VERSION ""

NS_ :

BS_:

BU_: ICC DVR PCL EAMP FLZCU_HCU_IC FLZCU_IC HCU_IC FLZCU_Signal_IC CGW TBOX BNCM CWC FRZCU

BO_ 771 FLZCU_303h: 16 FLZCU_Signal_IC
 SG_ TimeGapAdjustment_33Dh : 26|3@0+ (1,0) [0|7] ""  ICC

BO_ 1127 CDU_DCDC_1: 24 Vector__XXX
 SG_ DCDC_FaultLevelSts : 107|3@0+ (1,0) [0|7] ""  ICC

BO_ 1035 VCC_1: 8 FLZCU_Signal_IC
 SG_ VCC_1_OTASts : 17|2@0- (1,0) [0|3] ""  ICC

BO_ 1364 ICC_RISD_44: 64 ICC
 SG_ ICC_RISD_Pixel504_OnOff : 511|1@0+ (1,0) [0|1] "" Vector__XXX
 SG_ ICC_RISD_Pixel503_OnOff : 510|1@0+ (1,0) [0|1] "" Vector__XXX
 SG_ ICC_RISD_Pixel502_OnOff : 509|1@0+ (1,0) [0|1] "" Vector__XXX
 SG_ ICC_RISD_Pixel501_OnOff : 508|1@0+ (1,0) [0|1] "" Vector__XXX
 SG_ ICC_RISD_Pixel500_OnOff : 507|1@0+ (1,0) [0|1] "" Vector__XXX
 SG_ ICC_RISD_Pixel499_OnOff : 506|1@0+ (1,0) [0|1] "" Vector__XXX
 SG_ ICC_RISD_Pixel498_OnOff : 505|1@0+ (1,0) [0|1] "" Vector__XXX
 SG_ ICC_RISD_Pixel497_OnOff : 504|1@0+ (1,0) [0|1] "" Vector__XXX
 SG_ ICC_RISD_Pixel496_OnOff : 503|1@0+ (1,0) [0|1] "" Vector__XXX
 SG_ ICC_RISD_Pixel495_OnOff : 502|1@0+ (1,0) [0|1] "" Vector__XXX
 SG_ ICC_RISD_Pixel494_OnOff : 501|1@0+ (1,0) [0|1] "" Vector__XXX
 SG_ ICC_RISD_Pixel493_OnOff : 500|1@0+ (1,0) [0|1] "" Vector__XXX
 SG_ ICC_RISD_Pixel492_OnOff : 499|1@0+ (1,0) [0|1] "" Vector__XXX
 SG_ ICC_RISD_Pixel491_OnOff : 498|1@0+ (1,0) [0|1] "" Vector__XXX
 SG_ ICC_RISD_Pixel490_OnOff : 497|1@0+ (1,0) [0|1] "" Vector__XXX
 SG_ ICC_RISD_Pixel489_OnOff : 496|1@0+ (1,0) [0|1] "" Vector__XXX
 SG_ ICC_RISD_Pixel488_OnOff : 495|1@0+ (1,0) [0|1] "" Vector__XXX
 SG_ ICC_RISD_Pixel487_OnOff : 494|1@0+ (1,0) [0|1] "" Vector__XXX
 SG_ ICC_RISD_Pixel486_OnOff : 493|1@0+ (1,0) [0|1] "" Vector__XXX
 SG_ ICC_RISD_Pixel485_OnOff : 492|1@0+ (1,0) [0|1] "" Vector__XXX
 SG_ ICC_RISD_Pixel484_OnOff : 491|1@0+ (1,0) [0|1] "" Vector__XXX
 SG_ ICC_RISD_Pixel483_OnOff : 490|1@0+ (1,0) [0|1] "" Vector__XXX
 SG_ ICC_RISD_Pixel482_OnOff : 489|1@0+ (1,0) [0|1] "" Vector__XXX
 SG_ ICC_RISD_Pixel481_OnOff : 488|1@0+ (1,0) [0|1] "" Vector__XXX
 SG_ ICC_RISD_Pixel480_OnOff : 487|1@0+ (1,0) [0|1] "" Vector__XXX
 SG_ ICC_RISD_Pixel479_OnOff : 486|1@0+ (1,0) [0|1] "" Vector__XXX
 SG_ ICC_RISD_Pixel478_OnOff : 485|1@0+ (1,0) [0|1] "" Vector__XXX
 SG_ ICC_RISD_Pixel477_OnOff : 484|1@0+ (1,0) [0|1] "" Vector__XXX
 SG_ ICC_RISD_Pixel476_OnOff : 483|1@0+ (1,0) [0|1] "" Vector__XXX
 SG_ ICC_RISD_Pixel475_OnOff : 482|1@0+ (1,0) [0|1] "" Vector__XXX
 SG_ ICC_RISD_Pixel474_OnOff : 481|1@0+ (1,0) [0|1] "" Vector__XXX
 SG_ ICC_RISD_Pixel473_OnOff : 480|1@0+ (1,0) [0|1] "" Vector__XXX
 SG_ ICC_RISD_Pixel472_OnOff : 479|1@0+ (1,0) [0|1] "" Vector__XXX
 SG_ ICC_RISD_Pixel471_OnOff : 478|1@0+ (1,0) [0|1] "" Vector__XXX
 SG_ ICC_RISD_Pixel470_OnOff : 477|1@0+ (1,0) [0|1] "" Vector__XXX
 SG_ ICC_RISD_Pixel469_OnOff : 476|1@0+ (1,0) [0|1] "" Vector__XXX
 SG_ ICC_RISD_Pixel468_OnOff : 475|1@0+ (1,0) [0|1] "" Vector__XXX
 SG_ ICC_RISD_Pixel467_OnOff : 474|1@0+ (1,0) [0|1] "" Vector__XXX
 SG_ ICC_RISD_Pixel466_OnOff : 473|1@0+ (1,0) [0|1] "" Vector__XXX
 SG_ ICC_RISD_Pixel465_OnOff : 472|1@0+ (1,0) [0|1] "" Vector__XXX
 SG_ ICC_RISD_Pixel464_OnOff : 471|1@0+ (1,0) [0|1] "" Vector__XXX
 SG_ ICC_RISD_Pixel463_OnOff : 470|1@0+ (1,0) [0|1] "" Vector__XXX
 SG_ ICC_RISD_Pixel462_OnOff : 469|1@0+ (1,0) [0|1] "" Vector__XXX
 SG_ ICC_RISD_Pixel461_OnOff : 468|1@0+ (1,0) [0|1] "" Vector__XXX
 SG_ ICC_RISD_Pixel460_OnOff : 467|1@0+ (1,0) [0|1] "" Vector__XXX
 SG_ ICC_RISD_Pixel459_OnOff : 466|1@0+ (1,0) [0|1] "" Vector__XXX
 SG_ ICC_RISD_Pixel458_OnOff : 465|1@0+ (1,0) [0|1] "" Vector__XXX
 SG_ ICC_RISD_Pixel457_OnOff : 464|1@0+ (1,0) [0|1] "" Vector__XXX
 SG_ ICC_RISD_Pixel456_OnOff : 463|1@0+ (1,0) [0|1] "" Vector__XXX
 SG_ ICC_RISD_Pixel455_OnOff : 462|1@0+ (1,0) [0|1] "" Vector__XXX
 SG_ ICC_RISD_Pixel454_OnOff : 461|1@0+ (1,0) [0|1] "" Vector__XXX
 SG_ ICC_RISD_Pixel453_OnOff : 460|1@0+ (1,0) [0|1] "" Vector__XXX
 SG_ ICC_RISD_Pixel452_OnOff : 459|1@0+ (1,0) [0|1] "" Vector__XXX
 SG_ ICC_RISD_Pixel451_OnOff : 458|1@0+ (1,0) [0|1] "" Vector__XXX
 SG_ ICC_RISD_Pixel450_OnOff : 457|1@0+ (1,0) [0|1] "" Vector__XXX
 SG_ ICC_RISD_Pixel449_OnOff : 456|1@0+ (1,0) [0|1] "" Vector__XXX
 SG_ ICC_RISD_Pixel448_OnOff : 455|1@0+ (1,0) [0|1] "" Vector__XXX
 SG_ ICC_RISD_Pixel447_OnOff : 454|1@0+ (1,0) [0|1] "" Vector__XXX
 SG_ ICC_RISD_Pixel446_OnOff : 453|1@0+ (1,0) [0|1] "" Vector__XXX
 SG_ ICC_RISD_Pixel445_OnOff : 452|1@0+ (1,0) [0|1] "" Vector__XXX
 SG_ ICC_RISD_Pixel444_OnOff : 451|1@0+ (1,0) [0|1] "" Vector__XXX
 SG_ ICC_RISD_Pixel443_OnOff : 450|1@0+ (1,0) [0|1] "" Vector__XXX
 SG_ ICC_RISD_Pixel442_OnOff : 449|1@0+ (1,0) [0|1] "" Vector__XXX
 SG_ ICC_RISD_Pixel441_OnOff : 448|1@0+ (1,0) [0|1] "" Vector__XXX
 SG_ ICC_RISD_Pixel440_OnOff : 447|1@0+ (1,0) [0|1] "" Vector__XXX
 SG_ ICC_RISD_Pixel439_OnOff : 446|1@0+ (1,0) [0|1] "" Vector__XXX
 SG_ ICC_RISD_Pixel438_OnOff : 445|1@0+ (1,0) [0|1] "" Vector__XXX
 SG_ ICC_RISD_Pixel437_OnOff : 444|1@0+ (1,0) [0|1] "" Vector__XXX
 SG_ ICC_RISD_Pixel436_OnOff : 443|1@0+ (1,0) [0|1] "" Vector__XXX
 SG_ ICC_RISD_Pixel435_OnOff : 442|1@0+ (1,0) [0|1] "" Vector__XXX
 SG_ ICC_RISD_Pixel434_OnOff : 441|1@0+ (1,0) [0|1] "" Vector__XXX
 SG_ ICC_RISD_Pixel433_OnOff : 440|1@0+ (1,0) [0|1] "" Vector__XXX
 SG_ ICC_RISD_Pixel432_OnOff : 439|1@0+ (1,0) [0|1] "" Vector__XXX
 SG_ ICC_RISD_Pixel431_OnOff : 438|1@0+ (1,0) [0|1] "" Vector__XXX
 SG_ ICC_RISD_Pixel430_OnOff : 437|1@0+ (1,0) [0|1] "" Vector__XXX
 SG_ ICC_RISD_Pixel429_OnOff : 436|1@0+ (1,0) [0|1] "" Vector__XXX
 SG_ ICC_RISD_Pixel428_OnOff : 435|1@0+ (1,0) [0|1] "" Vector__XXX
 SG_ ICC_RISD_Pixel427_OnOff : 434|1@0+ (1,0) [0|1] "" Vector__XXX
 SG_ ICC_RISD_Pixel426_OnOff : 433|1@0+ (1,0) [0|1] "" Vector__XXX
 SG_ ICC_RISD_Pixel425_OnOff : 432|1@0+ (1,0) [0|1] "" Vector__XXX
 SG_ ICC_RISD_Pixel424_OnOff : 431|1@0+ (1,0) [0|1] "" Vector__XXX
 SG_ ICC_RISD_Pixel423_OnOff : 430|1@0+ (1,0) [0|1] "" Vector__XXX
 SG_ ICC_RISD_Pixel422_OnOff : 429|1@0+ (1,0) [0|1] "" Vector__XXX
 SG_ ICC_RISD_Pixel421_OnOff : 428|1@0+ (1,0) [0|1] "" Vector__XXX
 SG_ ICC_RISD_Pixel420_OnOff : 427|1@0+ (1,0) [0|1] "" Vector__XXX
 SG_ ICC_RISD_Pixel419_OnOff : 426|1@0+ (1,0) [0|1] "" Vector__XXX
 SG_ ICC_RISD_Pixel418_OnOff : 425|1@0+ (1,0) [0|1] "" Vector__XXX
 SG_ ICC_RISD_Pixel417_OnOff : 424|1@0+ (1,0) [0|1] "" Vector__XXX
 SG_ ICC_RISD_Pixel416_OnOff : 423|1@0+ (1,0) [0|1] "" Vector__XXX
 SG_ ICC_RISD_Pixel415_OnOff : 422|1@0+ (1,0) [0|1] "" Vector__XXX
 SG_ ICC_RISD_Pixel414_OnOff : 421|1@0+ (1,0) [0|1] "" Vector__XXX
 SG_ ICC_RISD_Pixel413_OnOff : 420|1@0+ (1,0) [0|1] "" Vector__XXX
 SG_ ICC_RISD_Pixel412_OnOff : 419|1@0+ (1,0) [0|1] "" Vector__XXX
 SG_ ICC_RISD_Pixel411_OnOff : 418|1@0+ (1,0) [0|1] "" Vector__XXX
 SG_ ICC_RISD_Pixel410_OnOff : 417|1@0+ (1,0) [0|1] "" Vector__XXX
 SG_ ICC_RISD_Pixel409_OnOff : 416|1@0+ (1,0) [0|1] "" Vector__XXX
 SG_ ICC_RISD_Pixel408_OnOff : 415|1@0+ (1,0) [0|1] "" Vector__XXX
 SG_ ICC_RISD_Pixel407_OnOff : 414|1@0+ (1,0) [0|1] "" Vector__XXX
 SG_ ICC_RISD_Pixel406_OnOff : 413|1@0+ (1,0) [0|1] "" Vector__XXX
 SG_ ICC_RISD_Pixel405_OnOff : 412|1@0+ (1,0) [0|1] "" Vector__XXX
 SG_ ICC_RISD_Pixel404_OnOff : 411|1@0+ (1,0) [0|1] "" Vector__XXX
 SG_ ICC_RISD_Pixel403_OnOff : 410|1@0+ (1,0) [0|1] "" Vector__XXX
 SG_ ICC_RISD_Pixel402_OnOff : 409|1@0+ (1,0) [0|1] "" Vector__XXX
 SG_ ICC_RISD_Pixel401_OnOff : 408|1@0+ (1,0) [0|1] "" Vector__XXX
 SG_ ICC_RISD_Pixel400_OnOff : 407|1@0+ (1,0) [0|1] "" Vector__XXX
 SG_ ICC_RISD_Pixel399_OnOff : 406|1@0+ (1,0) [0|1] "" Vector__XXX
 SG_ ICC_RISD_Pixel398_OnOff : 405|1@0+ (1,0) [0|1] "" Vector__XXX
 SG_ ICC_RISD_Pixel397_OnOff : 404|1@0+ (1,0) [0|1] "" Vector__XXX
 SG_ ICC_RISD_Pixel396_OnOff : 403|1@0+ (1,0) [0|1] "" Vector__XXX
 SG_ ICC_RISD_Pixel395_OnOff : 402|1@0+ (1,0) [0|1] "" Vector__XXX
 SG_ ICC_RISD_Pixel394_OnOff : 401|1@0+ (1,0) [0|1] "" Vector__XXX
 SG_ ICC_RISD_Pixel393_OnOff : 400|1@0+ (1,0) [0|1] "" Vector__XXX
 SG_ ICC_RISD_Pixel392_OnOff : 399|1@0+ (1,0) [0|1] "" Vector__XXX
 SG_ ICC_RISD_Pixel391_OnOff : 398|1@0+ (1,0) [0|1] "" Vector__XXX
 SG_ ICC_RISD_Pixel390_OnOff : 397|1@0+ (1,0) [0|1] "" Vector__XXX
 SG_ ICC_RISD_Pixel389_OnOff : 396|1@0+ (1,0) [0|1] "" Vector__XXX
 SG_ ICC_RISD_Pixel388_OnOff : 395|1@0+ (1,0) [0|1] "" Vector__XXX
 SG_ ICC_RISD_Pixel387_OnOff : 394|1@0+ (1,0) [0|1] "" Vector__XXX
 SG_ ICC_RISD_Pixel386_OnOff : 393|1@0+ (1,0) [0|1] "" Vector__XXX
 SG_ ICC_RISD_Pixel385_OnOff : 392|1@0+ (1,0) [0|1] "" Vector__XXX
 SG_ ICC_RISD_Pixel384_OnOff : 391|1@0+ (1,0) [0|1] "" Vector__XXX
 SG_ ICC_RISD_Pixel383_OnOff : 390|1@0+ (1,0) [0|1] "" Vector__XXX
 SG_ ICC_RISD_Pixel382_OnOff : 389|1@0+ (1,0) [0|1] "" Vector__XXX
 SG_ ICC_RISD_Pixel381_OnOff : 388|1@0+ (1,0) [0|1] "" Vector__XXX
 SG_ ICC_RISD_Pixel380_OnOff : 387|1@0+ (1,0) [0|1] "" Vector__XXX
 SG_ ICC_RISD_Pixel379_OnOff : 386|1@0+ (1,0) [0|1] "" Vector__XXX
 SG_ ICC_RISD_Pixel378_OnOff : 385|1@0+ (1,0) [0|1] "" Vector__XXX
 SG_ ICC_RISD_Pixel377_OnOff : 384|1@0+ (1,0) [0|1] "" Vector__XXX
 SG_ ICC_RISD_Pixel376_OnOff : 383|1@0+ (1,0) [0|1] "" Vector__XXX
 SG_ ICC_RISD_Pixel375_OnOff : 382|1@0+ (1,0) [0|1] "" Vector__XXX
 SG_ ICC_RISD_Pixel374_OnOff : 381|1@0+ (1,0) [0|1] "" Vector__XXX
 SG_ ICC_RISD_Pixel373_OnOff : 380|1@0+ (1,0) [0|1] "" Vector__XXX
 SG_ ICC_RISD_Pixel372_OnOff : 379|1@0+ (1,0) [0|1] "" Vector__XXX
 SG_ ICC_RISD_Pixel371_OnOff : 378|1@0+ (1,0) [0|1] "" Vector__XXX
 SG_ ICC_RISD_Pixel370_OnOff : 377|1@0+ (1,0) [0|1] "" Vector__XXX
 SG_ ICC_RISD_Pixel369_OnOff : 376|1@0+ (1,0) [0|1] "" Vector__XXX
 SG_ ICC_RISD_Pixel368_OnOff : 375|1@0+ (1,0) [0|1] "" Vector__XXX
 SG_ ICC_RISD_Pixel367_OnOff : 374|1@0+ (1,0) [0|1] "" Vector__XXX
 SG_ ICC_RISD_Pixel366_OnOff : 373|1@0+ (1,0) [0|1] "" Vector__XXX
 SG_ ICC_RISD_Pixel365_OnOff : 372|1@0+ (1,0) [0|1] "" Vector__XXX
 SG_ ICC_RISD_Pixel364_OnOff : 371|1@0+ (1,0) [0|1] "" Vector__XXX
 SG_ ICC_RISD_Pixel363_OnOff : 370|1@0+ (1,0) [0|1] "" Vector__XXX
 SG_ ICC_RISD_Pixel362_OnOff : 369|1@0+ (1,0) [0|1] "" Vector__XXX
 SG_ ICC_RISD_Pixel361_OnOff : 368|1@0+ (1,0) [0|1] "" Vector__XXX
 SG_ ICC_RISD_Pixel360_OnOff : 367|1@0+ (1,0) [0|1] "" Vector__XXX
 SG_ ICC_RISD_Pixel359_OnOff : 366|1@0+ (1,0) [0|1] "" Vector__XXX
 SG_ ICC_RISD_Pixel358_OnOff : 365|1@0+ (1,0) [0|1] "" Vector__XXX
 SG_ ICC_RISD_Pixel357_OnOff : 364|1@0+ (1,0) [0|1] "" Vector__XXX
 SG_ ICC_RISD_Pixel356_OnOff : 363|1@0+ (1,0) [0|1] "" Vector__XXX
 SG_ ICC_RISD_Pixel355_OnOff : 362|1@0+ (1,0) [0|1] "" Vector__XXX
 SG_ ICC_RISD_Pixel354_OnOff : 361|1@0+ (1,0) [0|1] "" Vector__XXX
 SG_ ICC_RISD_Pixel353_OnOff : 360|1@0+ (1,0) [0|1] "" Vector__XXX
 SG_ ICC_RISD_Pixel352_OnOff : 359|1@0+ (1,0) [0|1] "" Vector__XXX
 SG_ ICC_RISD_Pixel351_OnOff : 358|1@0+ (1,0) [0|1] "" Vector__XXX
 SG_ ICC_RISD_Pixel350_OnOff : 357|1@0+ (1,0) [0|1] "" Vector__XXX
 SG_ ICC_RISD_Pixel349_OnOff : 356|1@0+ (1,0) [0|1] "" Vector__XXX
 SG_ ICC_RISD_Pixel348_OnOff : 355|1@0+ (1,0) [0|1] "" Vector__XXX
 SG_ ICC_RISD_Pixel347_OnOff : 354|1@0+ (1,0) [0|1] "" Vector__XXX
 SG_ ICC_RISD_Pixel346_OnOff : 353|1@0+ (1,0) [0|1] "" Vector__XXX
 SG_ ICC_RISD_Pixel345_OnOff : 352|1@0+ (1,0) [0|1] "" Vector__XXX
 SG_ ICC_RISD_Pixel344_OnOff : 351|1@0+ (1,0) [0|1] "" Vector__XXX
 SG_ ICC_RISD_Pixel343_OnOff : 350|1@0+ (1,0) [0|1] "" Vector__XXX
 SG_ ICC_RISD_Pixel342_OnOff : 349|1@0+ (1,0) [0|1] "" Vector__XXX
 SG_ ICC_RISD_Pixel341_OnOff : 348|1@0+ (1,0) [0|1] "" Vector__XXX
 SG_ ICC_RISD_Pixel340_OnOff : 347|1@0+ (1,0) [0|1] "" Vector__XXX
 SG_ ICC_RISD_Pixel339_OnOff : 346|1@0+ (1,0) [0|1] "" Vector__XXX
 SG_ ICC_RISD_Pixel338_OnOff : 345|1@0+ (1,0) [0|1] "" Vector__XXX
 SG_ ICC_RISD_Pixel337_OnOff : 344|1@0+ (1,0) [0|1] "" Vector__XXX
 SG_ ICC_RISD_Pixel336_OnOff : 343|1@0+ (1,0) [0|1] "" Vector__XXX
 SG_ ICC_RISD_Pixel335_OnOff : 342|1@0+ (1,0) [0|1] "" Vector__XXX
 SG_ ICC_RISD_Pixel334_OnOff : 341|1@0+ (1,0) [0|1] "" Vector__XXX
 SG_ ICC_RISD_Pixel333_OnOff : 340|1@0+ (1,0) [0|1] "" Vector__XXX
 SG_ ICC_RISD_Pixel332_OnOff : 339|1@0+ (1,0) [0|1] "" Vector__XXX
 SG_ ICC_RISD_Pixel331_OnOff : 338|1@0+ (1,0) [0|1] "" Vector__XXX
 SG_ ICC_RISD_Pixel330_OnOff : 337|1@0+ (1,0) [0|1] "" Vector__XXX
 SG_ ICC_RISD_Pixel329_OnOff : 336|1@0+ (1,0) [0|1] "" Vector__XXX
 SG_ ICC_RISD_Pixel328_OnOff : 335|1@0+ (1,0) [0|1] "" Vector__XXX
 SG_ ICC_RISD_Pixel327_OnOff : 334|1@0+ (1,0) [0|1] "" Vector__XXX
 SG_ ICC_RISD_Pixel326_OnOff : 333|1@0+ (1,0) [0|1] "" Vector__XXX
 SG_ ICC_RISD_Pixel325_OnOff : 332|1@0+ (1,0) [0|1] "" Vector__XXX
 SG_ ICC_RISD_Pixel324_OnOff : 331|1@0+ (1,0) [0|1] "" Vector__XXX
 SG_ ICC_RISD_Pixel323_OnOff : 330|1@0+ (1,0) [0|1] "" Vector__XXX
 SG_ ICC_RISD_Pixel322_OnOff : 329|1@0+ (1,0) [0|1] "" Vector__XXX
 SG_ ICC_RISD_Pixel321_OnOff : 328|1@0+ (1,0) [0|1] "" Vector__XXX
 SG_ ICC_RISD_Pixel320_OnOff : 327|1@0+ (1,0) [0|1] "" Vector__XXX
 SG_ ICC_RISD_Pixel319_OnOff : 326|1@0+ (1,0) [0|1] "" Vector__XXX
 SG_ ICC_RISD_Pixel318_OnOff : 325|1@0+ (1,0) [0|1] "" Vector__XXX
 SG_ ICC_RISD_Pixel317_OnOff : 324|1@0+ (1,0) [0|1] "" Vector__XXX
 SG_ ICC_RISD_Pixel316_OnOff : 323|1@0+ (1,0) [0|1] "" Vector__XXX
 SG_ ICC_RISD_Pixel315_OnOff : 322|1@0+ (1,0) [0|1] "" Vector__XXX
 SG_ ICC_RISD_Pixel314_OnOff : 321|1@0+ (1,0) [0|1] "" Vector__XXX
 SG_ ICC_RISD_Pixel313_OnOff : 320|1@0+ (1,0) [0|1] "" Vector__XXX
 SG_ ICC_RISD_Pixel312_OnOff : 319|1@0+ (1,0) [0|1] "" Vector__XXX
 SG_ ICC_RISD_Pixel311_OnOff : 318|1@0+ (1,0) [0|1] "" Vector__XXX
 SG_ ICC_RISD_Pixel310_OnOff : 317|1@0+ (1,0) [0|1] "" Vector__XXX
 SG_ ICC_RISD_Pixel309_OnOff : 316|1@0+ (1,0) [0|1] "" Vector__XXX
 SG_ ICC_RISD_Pixel308_OnOff : 315|1@0+ (1,0) [0|1] "" Vector__XXX
 SG_ ICC_RISD_Pixel307_OnOff : 314|1@0+ (1,0) [0|1] "" Vector__XXX
 SG_ ICC_RISD_Pixel306_OnOff : 313|1@0+ (1,0) [0|1] "" Vector__XXX
 SG_ ICC_RISD_Pixel305_OnOff : 312|1@0+ (1,0) [0|1] "" Vector__XXX
 SG_ ICC_RISD_Pixel304_OnOff : 311|1@0+ (1,0) [0|1] "" Vector__XXX
 SG_ ICC_RISD_Pixel303_OnOff : 310|1@0+ (1,0) [0|1] "" Vector__XXX
 SG_ ICC_RISD_Pixel302_OnOff : 309|1@0+ (1,0) [0|1] "" Vector__XXX
 SG_ ICC_RISD_Pixel301_OnOff : 308|1@0+ (1,0) [0|1] "" Vector__XXX
 SG_ ICC_RISD_Pixel300_OnOff : 307|1@0+ (1,0) [0|1] "" Vector__XXX
 SG_ ICC_RISD_Pixel299_OnOff : 306|1@0+ (1,0) [0|1] "" Vector__XXX
 SG_ ICC_RISD_Pixel298_OnOff : 305|1@0+ (1,0) [0|1] "" Vector__XXX
 SG_ ICC_RISD_Pixel297_OnOff : 304|1@0+ (1,0) [0|1] "" Vector__XXX
 SG_ ICC_RISD_Pixel296_OnOff : 303|1@0+ (1,0) [0|1] "" Vector__XXX
 SG_ ICC_RISD_Pixel295_OnOff : 302|1@0+ (1,0) [0|1] "" Vector__XXX
 SG_ ICC_RISD_Pixel294_OnOff : 301|1@0+ (1,0) [0|1] "" Vector__XXX
 SG_ ICC_RISD_Pixel293_OnOff : 300|1@0+ (1,0) [0|1] "" Vector__XXX
 SG_ ICC_RISD_Pixel292_OnOff : 299|1@0+ (1,0) [0|1] "" Vector__XXX
 SG_ ICC_RISD_Pixel291_OnOff : 298|1@0+ (1,0) [0|1] "" Vector__XXX
 SG_ ICC_RISD_Pixel290_OnOff : 297|1@0+ (1,0) [0|1] "" Vector__XXX
 SG_ ICC_RISD_Pixel289_OnOff : 296|1@0+ (1,0) [0|1] "" Vector__XXX
 SG_ ICC_RISD_Pixel288_OnOff : 295|1@0+ (1,0) [0|1] "" Vector__XXX
 SG_ ICC_RISD_Pixel287_OnOff : 294|1@0+ (1,0) [0|1] "" Vector__XXX
 SG_ ICC_RISD_Pixel286_OnOff : 293|1@0+ (1,0) [0|1] "" Vector__XXX
 SG_ ICC_RISD_Pixel285_OnOff : 292|1@0+ (1,0) [0|1] "" Vector__XXX
 SG_ ICC_RISD_Pixel284_OnOff : 291|1@0+ (1,0) [0|1] "" Vector__XXX
 SG_ ICC_RISD_Pixel283_OnOff : 290|1@0+ (1,0) [0|1] "" Vector__XXX
 SG_ ICC_RISD_Pixel282_OnOff : 289|1@0+ (1,0) [0|1] "" Vector__XXX
 SG_ ICC_RISD_Pixel281_OnOff : 288|1@0+ (1,0) [0|1] "" Vector__XXX
 SG_ ICC_RISD_Pixel280_OnOff : 287|1@0+ (1,0) [0|1] "" Vector__XXX
 SG_ ICC_RISD_Pixel279_OnOff : 286|1@0+ (1,0) [0|1] "" Vector__XXX
 SG_ ICC_RISD_Pixel278_OnOff : 285|1@0+ (1,0) [0|1] "" Vector__XXX
 SG_ ICC_RISD_Pixel277_OnOff : 284|1@0+ (1,0) [0|1] "" Vector__XXX
 SG_ ICC_RISD_Pixel276_OnOff : 283|1@0+ (1,0) [0|1] "" Vector__XXX
 SG_ ICC_RISD_Pixel275_OnOff : 282|1@0+ (1,0) [0|1] "" Vector__XXX
 SG_ ICC_RISD_Pixel274_OnOff : 281|1@0+ (1,0) [0|1] "" Vector__XXX
 SG_ ICC_RISD_Pixel273_OnOff : 280|1@0+ (1,0) [0|1] "" Vector__XXX
 SG_ ICC_RISD_Pixel272_OnOff : 279|1@0+ (1,0) [0|1] "" Vector__XXX
 SG_ ICC_RISD_Pixel271_OnOff : 278|1@0+ (1,0) [0|1] "" Vector__XXX
 SG_ ICC_RISD_Pixel270_OnOff : 277|1@0+ (1,0) [0|1] "" Vector__XXX
 SG_ ICC_RISD_Pixel269_OnOff : 276|1@0+ (1,0) [0|1] "" Vector__XXX
 SG_ ICC_RISD_Pixel268_OnOff : 275|1@0+ (1,0) [0|1] "" Vector__XXX
 SG_ ICC_RISD_Pixel267_OnOff : 274|1@0+ (1,0) [0|1] "" Vector__XXX
 SG_ ICC_RISD_Pixel266_OnOff : 273|1@0+ (1,0) [0|1] "" Vector__XXX
 SG_ ICC_RISD_Pixel265_OnOff : 272|1@0+ (1,0) [0|1] "" Vector__XXX
 SG_ ICC_RISD_Pixel264_OnOff : 271|1@0+ (1,0) [0|1] "" Vector__XXX
 SG_ ICC_RISD_Pixel263_OnOff : 270|1@0+ (1,0) [0|1] "" Vector__XXX
 SG_ ICC_RISD_Pixel262_OnOff : 269|1@0+ (1,0) [0|1] "" Vector__XXX
 SG_ ICC_RISD_Pixel261_OnOff : 268|1@0+ (1,0) [0|1] "" Vector__XXX
 SG_ ICC_RISD_Pixel260_OnOff : 267|1@0+ (1,0) [0|1] "" Vector__XXX
 SG_ ICC_RISD_Pixel259_OnOff : 266|1@0+ (1,0) [0|1] "" Vector__XXX
 SG_ ICC_RISD_Pixel258_OnOff : 265|1@0+ (1,0) [0|1] "" Vector__XXX
 SG_ ICC_RISD_Pixel257_OnOff : 264|1@0+ (1,0) [0|1] "" Vector__XXX
 SG_ ICC_RISD_Pixel256_OnOff : 263|1@0+ (1,0) [0|1] "" Vector__XXX
 SG_ ICC_RISD_Pixel255_OnOff : 262|1@0+ (1,0) [0|1] "" Vector__XXX
 SG_ ICC_RISD_Pixel254_OnOff : 261|1@0+ (1,0) [0|1] "" Vector__XXX
 SG_ ICC_RISD_Pixel253_OnOff : 260|1@0+ (1,0) [0|1] "" Vector__XXX
 SG_ ICC_RISD_Pixel252_OnOff : 259|1@0+ (1,0) [0|1] "" Vector__XXX
 SG_ ICC_RISD_Pixel251_OnOff : 258|1@0+ (1,0) [0|1] "" Vector__XXX
 SG_ ICC_RISD_Pixel250_OnOff : 257|1@0+ (1,0) [0|1] "" Vector__XXX
 SG_ ICC_RISD_Pixel249_OnOff : 256|1@0+ (1,0) [0|1] "" Vector__XXX
 SG_ ICC_RISD_Pixel248_OnOff : 255|1@0+ (1,0) [0|1] "" Vector__XXX
 SG_ ICC_RISD_Pixel247_OnOff : 254|1@0+ (1,0) [0|1] "" Vector__XXX
 SG_ ICC_RISD_Pixel246_OnOff : 253|1@0+ (1,0) [0|1] "" Vector__XXX
 SG_ ICC_RISD_Pixel245_OnOff : 252|1@0+ (1,0) [0|1] "" Vector__XXX
 SG_ ICC_RISD_Pixel244_OnOff : 251|1@0+ (1,0) [0|1] "" Vector__XXX
 SG_ ICC_RISD_Pixel243_OnOff : 250|1@0+ (1,0) [0|1] "" Vector__XXX
 SG_ ICC_RISD_Pixel242_OnOff : 249|1@0+ (1,0) [0|1] "" Vector__XXX
 SG_ ICC_RISD_Pixel241_OnOff : 248|1@0+ (1,0) [0|1] "" Vector__XXX
 SG_ ICC_RISD_Pixel240_OnOff : 247|1@0+ (1,0) [0|1] "" Vector__XXX
 SG_ ICC_RISD_Pixel239_OnOff : 246|1@0+ (1,0) [0|1] "" Vector__XXX
 SG_ ICC_RISD_Pixel238_OnOff : 245|1@0+ (1,0) [0|1] "" Vector__XXX
 SG_ ICC_RISD_Pixel237_OnOff : 244|1@0+ (1,0) [0|1] "" Vector__XXX
 SG_ ICC_RISD_Pixel236_OnOff : 243|1@0+ (1,0) [0|1] "" Vector__XXX
 SG_ ICC_RISD_Pixel235_OnOff : 242|1@0+ (1,0) [0|1] "" Vector__XXX
 SG_ ICC_RISD_Pixel234_OnOff : 241|1@0+ (1,0) [0|1] "" Vector__XXX
 SG_ ICC_RISD_Pixel233_OnOff : 240|1@0+ (1,0) [0|1] "" Vector__XXX
 SG_ ICC_RISD_Pixel232_OnOff : 239|1@0+ (1,0) [0|1] "" Vector__XXX
 SG_ ICC_RISD_Pixel231_OnOff : 238|1@0+ (1,0) [0|1] "" Vector__XXX
 SG_ ICC_RISD_Pixel230_OnOff : 237|1@0+ (1,0) [0|1] "" Vector__XXX
 SG_ ICC_RISD_Pixel229_OnOff : 236|1@0+ (1,0) [0|1] "" Vector__XXX
 SG_ ICC_RISD_Pixel228_OnOff : 235|1@0+ (1,0) [0|1] "" Vector__XXX
 SG_ ICC_RISD_Pixel227_OnOff : 234|1@0+ (1,0) [0|1] "" Vector__XXX
 SG_ ICC_RISD_Pixel226_OnOff : 233|1@0+ (1,0) [0|1] "" Vector__XXX
 SG_ ICC_RISD_Pixel225_OnOff : 232|1@0+ (1,0) [0|1] "" Vector__XXX
 SG_ ICC_RISD_Pixel224_OnOff : 231|1@0+ (1,0) [0|1] "" Vector__XXX
 SG_ ICC_RISD_Pixel223_OnOff : 230|1@0+ (1,0) [0|1] "" Vector__XXX
 SG_ ICC_RISD_Pixel222_OnOff : 229|1@0+ (1,0) [0|1] "" Vector__XXX
 SG_ ICC_RISD_Pixel221_OnOff : 228|1@0+ (1,0) [0|1] "" Vector__XXX
 SG_ ICC_RISD_Pixel220_OnOff : 227|1@0+ (1,0) [0|1] "" Vector__XXX
 SG_ ICC_RISD_Pixel219_OnOff : 226|1@0+ (1,0) [0|1] "" Vector__XXX
 SG_ ICC_RISD_Pixel218_OnOff : 225|1@0+ (1,0) [0|1] "" Vector__XXX
 SG_ ICC_RISD_Pixel217_OnOff : 224|1@0+ (1,0) [0|1] "" Vector__XXX
 SG_ ICC_RISD_Pixel216_OnOff : 223|1@0+ (1,0) [0|1] "" Vector__XXX
 SG_ ICC_RISD_Pixel215_OnOff : 222|1@0+ (1,0) [0|1] "" Vector__XXX
 SG_ ICC_RISD_Pixel214_OnOff : 221|1@0+ (1,0) [0|1] "" Vector__XXX
 SG_ ICC_RISD_Pixel213_OnOff : 220|1@0+ (1,0) [0|1] "" Vector__XXX
 SG_ ICC_RISD_Pixel212_OnOff : 219|1@0+ (1,0) [0|1] "" Vector__XXX
 SG_ ICC_RISD_Pixel211_OnOff : 218|1@0+ (1,0) [0|1] "" Vector__XXX
 SG_ ICC_RISD_Pixel210_OnOff : 217|1@0+ (1,0) [0|1] "" Vector__XXX
 SG_ ICC_RISD_Pixel209_OnOff : 216|1@0+ (1,0) [0|1] "" Vector__XXX
 SG_ ICC_RISD_Pixel208_OnOff : 215|1@0+ (1,0) [0|1] "" Vector__XXX
 SG_ ICC_RISD_Pixel207_OnOff : 214|1@0+ (1,0) [0|1] "" Vector__XXX
 SG_ ICC_RISD_Pixel206_OnOff : 213|1@0+ (1,0) [0|1] "" Vector__XXX
 SG_ ICC_RISD_Pixel205_OnOff : 212|1@0+ (1,0) [0|1] "" Vector__XXX
 SG_ ICC_RISD_Pixel204_OnOff : 211|1@0+ (1,0) [0|1] "" Vector__XXX
 SG_ ICC_RISD_Pixel203_OnOff : 210|1@0+ (1,0) [0|1] "" Vector__XXX
 SG_ ICC_RISD_Pixel202_OnOff : 209|1@0+ (1,0) [0|1] "" Vector__XXX
 SG_ ICC_RISD_Pixel201_OnOff : 208|1@0+ (1,0) [0|1] "" Vector__XXX
 SG_ ICC_RISD_Pixel200_OnOff : 207|1@0+ (1,0) [0|1] "" Vector__XXX
 SG_ ICC_RISD_Pixel199_OnOff : 206|1@0+ (1,0) [0|1] "" Vector__XXX
 SG_ ICC_RISD_Pixel198_OnOff : 205|1@0+ (1,0) [0|1] "" Vector__XXX
 SG_ ICC_RISD_Pixel197_OnOff : 204|1@0+ (1,0) [0|1] "" Vector__XXX
 SG_ ICC_RISD_Pixel196_OnOff : 203|1@0+ (1,0) [0|1] "" Vector__XXX
 SG_ ICC_RISD_Pixel195_OnOff : 202|1@0+ (1,0) [0|1] "" Vector__XXX
 SG_ ICC_RISD_Pixel194_OnOff : 201|1@0+ (1,0) [0|1] "" Vector__XXX
 SG_ ICC_RISD_Pixel193_OnOff : 200|1@0+ (1,0) [0|1] "" Vector__XXX
 SG_ ICC_RISD_Pixel192_OnOff : 199|1@0+ (1,0) [0|1] "" Vector__XXX
 SG_ ICC_RISD_Pixel191_OnOff : 198|1@0+ (1,0) [0|1] "" Vector__XXX
 SG_ ICC_RISD_Pixel190_OnOff : 197|1@0+ (1,0) [0|1] "" Vector__XXX
 SG_ ICC_RISD_Pixel189_OnOff : 196|1@0+ (1,0) [0|1] "" Vector__XXX
 SG_ ICC_RISD_Pixel188_OnOff : 195|1@0+ (1,0) [0|1] "" Vector__XXX
 SG_ ICC_RISD_Pixel187_OnOff : 194|1@0+ (1,0) [0|1] "" Vector__XXX
 SG_ ICC_RISD_Pixel186_OnOff : 193|1@0+ (1,0) [0|1] "" Vector__XXX
 SG_ ICC_RISD_Pixel185_OnOff : 192|1@0+ (1,0) [0|1] "" Vector__XXX
 SG_ ICC_RISD_Pixel184_OnOff : 191|1@0+ (1,0) [0|1] "" Vector__XXX
 SG_ ICC_RISD_Pixel183_OnOff : 190|1@0+ (1,0) [0|1] "" Vector__XXX
 SG_ ICC_RISD_Pixel182_OnOff : 189|1@0+ (1,0) [0|1] "" Vector__XXX
 SG_ ICC_RISD_Pixel181_OnOff : 188|1@0+ (1,0) [0|1] "" Vector__XXX
 SG_ ICC_RISD_Pixel180_OnOff : 187|1@0+ (1,0) [0|1] "" Vector__XXX
 SG_ ICC_RISD_Pixel179_OnOff : 186|1@0+ (1,0) [0|1] "" Vector__XXX
 SG_ ICC_RISD_Pixel178_OnOff : 185|1@0+ (1,0) [0|1] "" Vector__XXX
 SG_ ICC_RISD_Pixel177_OnOff : 184|1@0+ (1,0) [0|1] "" Vector__XXX
 SG_ ICC_RISD_Pixel176_OnOff : 183|1@0+ (1,0) [0|1] "" Vector__XXX
 SG_ ICC_RISD_Pixel175_OnOff : 182|1@0+ (1,0) [0|1] "" Vector__XXX
 SG_ ICC_RISD_Pixel174_OnOff : 181|1@0+ (1,0) [0|1] "" Vector__XXX
 SG_ ICC_RISD_Pixel173_OnOff : 180|1@0+ (1,0) [0|1] "" Vector__XXX
 SG_ ICC_RISD_Pixel172_OnOff : 179|1@0+ (1,0) [0|1] "" Vector__XXX
 SG_ ICC_RISD_Pixel171_OnOff : 178|1@0+ (1,0) [0|1] "" Vector__XXX
 SG_ ICC_RISD_Pixel170_OnOff : 177|1@0+ (1,0) [0|1] "" Vector__XXX
 SG_ ICC_RISD_Pixel169_OnOff : 176|1@0+ (1,0) [0|1] "" Vector__XXX
 SG_ ICC_RISD_Pixel168_OnOff : 175|1@0+ (1,0) [0|1] "" Vector__XXX
 SG_ ICC_RISD_Pixel167_OnOff : 174|1@0+ (1,0) [0|1] "" Vector__XXX
 SG_ ICC_RISD_Pixel166_OnOff : 173|1@0+ (1,0) [0|1] "" Vector__XXX
 SG_ ICC_RISD_Pixel165_OnOff : 172|1@0+ (1,0) [0|1] "" Vector__XXX
 SG_ ICC_RISD_Pixel164_OnOff : 171|1@0+ (1,0) [0|1] "" Vector__XXX
 SG_ ICC_RISD_Pixel163_OnOff : 170|1@0+ (1,0) [0|1] "" Vector__XXX
 SG_ ICC_RISD_Pixel162_OnOff : 169|1@0+ (1,0) [0|1] "" Vector__XXX
 SG_ ICC_RISD_Pixel161_OnOff : 168|1@0+ (1,0) [0|1] "" Vector__XXX
 SG_ ICC_RISD_Pixel160_OnOff : 167|1@0+ (1,0) [0|1] "" Vector__XXX
 SG_ ICC_RISD_Pixel159_OnOff : 166|1@0+ (1,0) [0|1] "" Vector__XXX
 SG_ ICC_RISD_Pixel158_OnOff : 165|1@0+ (1,0) [0|1] "" Vector__XXX
 SG_ ICC_RISD_Pixel157_OnOff : 164|1@0+ (1,0) [0|1] "" Vector__XXX
 SG_ ICC_RISD_Pixel156_OnOff : 163|1@0+ (1,0) [0|1] "" Vector__XXX
 SG_ ICC_RISD_Pixel155_OnOff : 162|1@0+ (1,0) [0|1] "" Vector__XXX
 SG_ ICC_RISD_Pixel154_OnOff : 161|1@0+ (1,0) [0|1] "" Vector__XXX
 SG_ ICC_RISD_Pixel153_OnOff : 160|1@0+ (1,0) [0|1] "" Vector__XXX
 SG_ ICC_RISD_Pixel152_OnOff : 159|1@0+ (1,0) [0|1] "" Vector__XXX
 SG_ ICC_RISD_Pixel151_OnOff : 158|1@0+ (1,0) [0|1] "" Vector__XXX
 SG_ ICC_RISD_Pixel150_OnOff : 157|1@0+ (1,0) [0|1] "" Vector__XXX
 SG_ ICC_RISD_Pixel149_OnOff : 156|1@0+ (1,0) [0|1] "" Vector__XXX
 SG_ ICC_RISD_Pixel148_OnOff : 155|1@0+ (1,0) [0|1] "" Vector__XXX
 SG_ ICC_RISD_Pixel147_OnOff : 154|1@0+ (1,0) [0|1] "" Vector__XXX
 SG_ ICC_RISD_Pixel146_OnOff : 153|1@0+ (1,0) [0|1] "" Vector__XXX
 SG_ ICC_RISD_Pixel145_OnOff : 152|1@0+ (1,0) [0|1] "" Vector__XXX
 SG_ ICC_RISD_Pixel144_OnOff : 151|1@0+ (1,0) [0|1] "" Vector__XXX
 SG_ ICC_RISD_Pixel143_OnOff : 150|1@0+ (1,0) [0|1] "" Vector__XXX
 SG_ ICC_RISD_Pixel142_OnOff : 149|1@0+ (1,0) [0|1] "" Vector__XXX
 SG_ ICC_RISD_Pixel141_OnOff : 148|1@0+ (1,0) [0|1] "" Vector__XXX
 SG_ ICC_RISD_Pixel140_OnOff : 147|1@0+ (1,0) [0|1] "" Vector__XXX
 SG_ ICC_RISD_Pixel139_OnOff : 146|1@0+ (1,0) [0|1] "" Vector__XXX
 SG_ ICC_RISD_Pixel138_OnOff : 145|1@0+ (1,0) [0|1] "" Vector__XXX
 SG_ ICC_RISD_Pixel137_OnOff : 144|1@0+ (1,0) [0|1] "" Vector__XXX
 SG_ ICC_RISD_Pixel136_OnOff : 143|1@0+ (1,0) [0|1] "" Vector__XXX
 SG_ ICC_RISD_Pixel135_OnOff : 142|1@0+ (1,0) [0|1] "" Vector__XXX
 SG_ ICC_RISD_Pixel134_OnOff : 141|1@0+ (1,0) [0|1] "" Vector__XXX
 SG_ ICC_RISD_Pixel133_OnOff : 140|1@0+ (1,0) [0|1] "" Vector__XXX
 SG_ ICC_RISD_Pixel132_OnOff : 139|1@0+ (1,0) [0|1] "" Vector__XXX
 SG_ ICC_RISD_Pixel131_OnOff : 138|1@0+ (1,0) [0|1] "" Vector__XXX
 SG_ ICC_RISD_Pixel130_OnOff : 137|1@0+ (1,0) [0|1] "" Vector__XXX
 SG_ ICC_RISD_Pixel129_OnOff : 136|1@0+ (1,0) [0|1] "" Vector__XXX
 SG_ ICC_RISD_Pixel128_OnOff : 135|1@0+ (1,0) [0|1] "" Vector__XXX
 SG_ ICC_RISD_Pixel127_OnOff : 134|1@0+ (1,0) [0|1] "" Vector__XXX
 SG_ ICC_RISD_Pixel126_OnOff : 133|1@0+ (1,0) [0|1] "" Vector__XXX
 SG_ ICC_RISD_Pixel125_OnOff : 132|1@0+ (1,0) [0|1] "" Vector__XXX
 SG_ ICC_RISD_Pixel124_OnOff : 131|1@0+ (1,0) [0|1] "" Vector__XXX
 SG_ ICC_RISD_Pixel123_OnOff : 130|1@0+ (1,0) [0|1] "" Vector__XXX
 SG_ ICC_RISD_Pixel122_OnOff : 129|1@0+ (1,0) [0|1] "" Vector__XXX
 SG_ ICC_RISD_Pixel121_OnOff : 128|1@0+ (1,0) [0|1] "" Vector__XXX
 SG_ ICC_RISD_Pixel120_OnOff : 127|1@0+ (1,0) [0|1] "" Vector__XXX
 SG_ ICC_RISD_Pixel119_OnOff : 126|1@0+ (1,0) [0|1] "" Vector__XXX
 SG_ ICC_RISD_Pixel118_OnOff : 125|1@0+ (1,0) [0|1] "" Vector__XXX
 SG_ ICC_RISD_Pixel117_OnOff : 124|1@0+ (1,0) [0|1] "" Vector__XXX
 SG_ ICC_RISD_Pixel116_OnOff : 123|1@0+ (1,0) [0|1] "" Vector__XXX
 SG_ ICC_RISD_Pixel115_OnOff : 122|1@0+ (1,0) [0|1] "" Vector__XXX
 SG_ ICC_RISD_Pixel114_OnOff : 121|1@0+ (1,0) [0|1] "" Vector__XXX
 SG_ ICC_RISD_Pixel113_OnOff : 120|1@0+ (1,0) [0|1] "" Vector__XXX
 SG_ ICC_RISD_Pixel112_OnOff : 119|1@0+ (1,0) [0|1] "" Vector__XXX
 SG_ ICC_RISD_Pixel111_OnOff : 118|1@0+ (1,0) [0|1] "" Vector__XXX
 SG_ ICC_RISD_Pixel110_OnOff : 117|1@0+ (1,0) [0|1] "" Vector__XXX
 SG_ ICC_RISD_Pixel109_OnOff : 116|1@0+ (1,0) [0|1] "" Vector__XXX
 SG_ ICC_RISD_Pixel108_OnOff : 115|1@0+ (1,0) [0|1] "" Vector__XXX
 SG_ ICC_RISD_Pixel107_OnOff : 114|1@0+ (1,0) [0|1] "" Vector__XXX
 SG_ ICC_RISD_Pixel106_OnOff : 113|1@0+ (1,0) [0|1] "" Vector__XXX
 SG_ ICC_RISD_Pixel105_OnOff : 112|1@0+ (1,0) [0|1] "" Vector__XXX
 SG_ ICC_RISD_Pixel104_OnOff : 111|1@0+ (1,0) [0|1] "" Vector__XXX
 SG_ ICC_RISD_Pixel103_OnOff : 110|1@0+ (1,0) [0|1] "" Vector__XXX
 SG_ ICC_RISD_Pixel102_OnOff : 109|1@0+ (1,0) [0|1] "" Vector__XXX
 SG_ ICC_RISD_Pixel101_OnOff : 108|1@0+ (1,0) [0|1] "" Vector__XXX
 SG_ ICC_RISD_Pixel100_OnOff : 107|1@0+ (1,0) [0|1] "" Vector__XXX
 SG_ ICC_RISD_Pixel99_OnOff : 106|1@0+ (1,0) [0|1] "" Vector__XXX
 SG_ ICC_RISD_Pixel98_OnOff : 105|1@0+ (1,0) [0|1] "" Vector__XXX
 SG_ ICC_RISD_Pixel97_OnOff : 104|1@0+ (1,0) [0|1] "" Vector__XXX
 SG_ ICC_RISD_Pixel96_OnOff : 103|1@0+ (1,0) [0|1] "" Vector__XXX
 SG_ ICC_RISD_Pixel95_OnOff : 102|1@0+ (1,0) [0|1] "" Vector__XXX
 SG_ ICC_RISD_Pixel94_OnOff : 101|1@0+ (1,0) [0|1] "" Vector__XXX
 SG_ ICC_RISD_Pixel93_OnOff : 100|1@0+ (1,0) [0|1] "" Vector__XXX
 SG_ ICC_RISD_Pixel92_OnOff : 99|1@0+ (1,0) [0|1] "" Vector__XXX
 SG_ ICC_RISD_Pixel91_OnOff : 98|1@0+ (1,0) [0|1] "" Vector__XXX
 SG_ ICC_RISD_Pixel90_OnOff : 97|1@0+ (1,0) [0|1] "" Vector__XXX
 SG_ ICC_RISD_Pixel89_OnOff : 96|1@0+ (1,0) [0|1] "" Vector__XXX
 SG_ ICC_RISD_Pixel88_OnOff : 95|1@0+ (1,0) [0|1] "" Vector__XXX
 SG_ ICC_RISD_Pixel87_OnOff : 94|1@0+ (1,0) [0|1] "" Vector__XXX
 SG_ ICC_RISD_Pixel86_OnOff : 93|1@0+ (1,0) [0|1] "" Vector__XXX
 SG_ ICC_RISD_Pixel85_OnOff : 92|1@0+ (1,0) [0|1] "" Vector__XXX
 SG_ ICC_RISD_Pixel84_OnOff : 91|1@0+ (1,0) [0|1] "" Vector__XXX
 SG_ ICC_RISD_Pixel83_OnOff : 90|1@0+ (1,0) [0|1] "" Vector__XXX
 SG_ ICC_RISD_Pixel82_OnOff : 89|1@0+ (1,0) [0|1] "" Vector__XXX
 SG_ ICC_RISD_Pixel81_OnOff : 88|1@0+ (1,0) [0|1] "" Vector__XXX
 SG_ ICC_RISD_Pixel80_OnOff : 87|1@0+ (1,0) [0|1] "" Vector__XXX
 SG_ ICC_RISD_Pixel79_OnOff : 86|1@0+ (1,0) [0|1] "" Vector__XXX
 SG_ ICC_RISD_Pixel78_OnOff : 85|1@0+ (1,0) [0|1] "" Vector__XXX
 SG_ ICC_RISD_Pixel77_OnOff : 84|1@0+ (1,0) [0|1] "" Vector__XXX
 SG_ ICC_RISD_Pixel76_OnOff : 83|1@0+ (1,0) [0|1] "" Vector__XXX
 SG_ ICC_RISD_Pixel75_OnOff : 82|1@0+ (1,0) [0|1] "" Vector__XXX
 SG_ ICC_RISD_Pixel74_OnOff : 81|1@0+ (1,0) [0|1] "" Vector__XXX
 SG_ ICC_RISD_Pixel73_OnOff : 80|1@0+ (1,0) [0|1] "" Vector__XXX
 SG_ ICC_RISD_Pixel72_OnOff : 79|1@0+ (1,0) [0|1] "" Vector__XXX
 SG_ ICC_RISD_Pixel71_OnOff : 78|1@0+ (1,0) [0|1] "" Vector__XXX
 SG_ ICC_RISD_Pixel70_OnOff : 77|1@0+ (1,0) [0|1] "" Vector__XXX
 SG_ ICC_RISD_Pixel69_OnOff : 76|1@0+ (1,0) [0|1] "" Vector__XXX
 SG_ ICC_RISD_Pixel68_OnOff : 75|1@0+ (1,0) [0|1] "" Vector__XXX
 SG_ ICC_RISD_Pixel67_OnOff : 74|1@0+ (1,0) [0|1] "" Vector__XXX
 SG_ ICC_RISD_Pixel66_OnOff : 73|1@0+ (1,0) [0|1] "" Vector__XXX
 SG_ ICC_RISD_Pixel65_OnOff : 72|1@0+ (1,0) [0|1] "" Vector__XXX
 SG_ ICC_RISD_Pixel64_OnOff : 71|1@0+ (1,0) [0|1] "" Vector__XXX
 SG_ ICC_RISD_Pixel63_OnOff : 70|1@0+ (1,0) [0|1] "" Vector__XXX
 SG_ ICC_RISD_Pixel62_OnOff : 69|1@0+ (1,0) [0|1] "" Vector__XXX
 SG_ ICC_RISD_Pixel61_OnOff : 68|1@0+ (1,0) [0|1] "" Vector__XXX
 SG_ ICC_RISD_Pixel60_OnOff : 67|1@0+ (1,0) [0|1] "" Vector__XXX
 SG_ ICC_RISD_Pixel59_OnOff : 66|1@0+ (1,0) [0|1] "" Vector__XXX
 SG_ ICC_RISD_Pixel58_OnOff : 65|1@0+ (1,0) [0|1] "" Vector__XXX
 SG_ ICC_RISD_Pixel57_OnOff : 64|1@0+ (1,0) [0|1] "" Vector__XXX
 SG_ ICC_RISD_Pixel56_OnOff : 63|1@0+ (1,0) [0|1] "" Vector__XXX
 SG_ ICC_RISD_Pixel55_OnOff : 62|1@0+ (1,0) [0|1] "" Vector__XXX
 SG_ ICC_RISD_Pixel54_OnOff : 61|1@0+ (1,0) [0|1] "" Vector__XXX
 SG_ ICC_RISD_Pixel53_OnOff : 60|1@0+ (1,0) [0|1] "" Vector__XXX
 SG_ ICC_RISD_Pixel52_OnOff : 59|1@0+ (1,0) [0|1] "" Vector__XXX
 SG_ ICC_RISD_Pixel51_OnOff : 58|1@0+ (1,0) [0|1] "" Vector__XXX
 SG_ ICC_RISD_Pixel50_OnOff : 57|1@0+ (1,0) [0|1] "" Vector__XXX
 SG_ ICC_RISD_Pixel49_OnOff : 56|1@0+ (1,0) [0|1] "" Vector__XXX
 SG_ ICC_RISD_Pixel48_OnOff : 55|1@0+ (1,0) [0|1] "" Vector__XXX
 SG_ ICC_RISD_Pixel47_OnOff : 54|1@0+ (1,0) [0|1] "" Vector__XXX
 SG_ ICC_RISD_Pixel46_OnOff : 53|1@0+ (1,0) [0|1] "" Vector__XXX
 SG_ ICC_RISD_Pixel45_OnOff : 52|1@0+ (1,0) [0|1] "" Vector__XXX
 SG_ ICC_RISD_Pixel44_OnOff : 51|1@0+ (1,0) [0|1] "" Vector__XXX
 SG_ ICC_RISD_Pixel43_OnOff : 50|1@0+ (1,0) [0|1] "" Vector__XXX
 SG_ ICC_RISD_Pixel42_OnOff : 49|1@0+ (1,0) [0|1] "" Vector__XXX
 SG_ ICC_RISD_Pixel41_OnOff : 48|1@0+ (1,0) [0|1] "" Vector__XXX
 SG_ ICC_RISD_Pixel40_OnOff : 47|1@0+ (1,0) [0|1] "" Vector__XXX
 SG_ ICC_RISD_Pixel39_OnOff : 46|1@0+ (1,0) [0|1] "" Vector__XXX
 SG_ ICC_RISD_Pixel38_OnOff : 45|1@0+ (1,0) [0|1] "" Vector__XXX
 SG_ ICC_RISD_Pixel37_OnOff : 44|1@0+ (1,0) [0|1] "" Vector__XXX
 SG_ ICC_RISD_Pixel36_OnOff : 43|1@0+ (1,0) [0|1] "" Vector__XXX
 SG_ ICC_RISD_Pixel35_OnOff : 42|1@0+ (1,0) [0|1] "" Vector__XXX
 SG_ ICC_RISD_Pixel34_OnOff : 41|1@0+ (1,0) [0|1] "" Vector__XXX
 SG_ ICC_RISD_Pixel33_OnOff : 40|1@0+ (1,0) [0|1] "" Vector__XXX
 SG_ ICC_RISD_Pixel32_OnOff : 39|1@0+ (1,0) [0|1] "" Vector__XXX
 SG_ ICC_RISD_Pixel31_OnOff : 38|1@0+ (1,0) [0|1] "" Vector__XXX
 SG_ ICC_RISD_Pixel30_OnOff : 37|1@0+ (1,0) [0|1] "" Vector__XXX
 SG_ ICC_RISD_Pixel29_OnOff : 36|1@0+ (1,0) [0|1] "" Vector__XXX
 SG_ ICC_RISD_Pixel28_OnOff : 35|1@0+ (1,0) [0|1] "" Vector__XXX
 SG_ ICC_RISD_Pixel27_OnOff : 34|1@0+ (1,0) [0|1] "" Vector__XXX
 SG_ ICC_RISD_Pixel26_OnOff : 33|1@0+ (1,0) [0|1] "" Vector__XXX
 SG_ ICC_RISD_Pixel25_OnOff : 32|1@0+ (1,0) [0|1] "" Vector__XXX
 SG_ ICC_RISD_Pixel24_OnOff : 31|1@0+ (1,0) [0|1] "" Vector__XXX
 SG_ ICC_RISD_Pixel23_OnOff : 30|1@0+ (1,0) [0|1] "" Vector__XXX
 SG_ ICC_RISD_Pixel22_OnOff : 29|1@0+ (1,0) [0|1] "" Vector__XXX
 SG_ ICC_RISD_Pixel21_OnOff : 28|1@0+ (1,0) [0|1] "" Vector__XXX
 SG_ ICC_RISD_Pixel20_OnOff : 27|1@0+ (1,0) [0|1] "" Vector__XXX
 SG_ ICC_RISD_Pixel19_OnOff : 26|1@0+ (1,0) [0|1] "" Vector__XXX
 SG_ ICC_RISD_Pixel18_OnOff : 25|1@0+ (1,0) [0|1] "" Vector__XXX
 SG_ ICC_RISD_Pixel17_OnOff : 24|1@0+ (1,0) [0|1] "" Vector__XXX
 SG_ ICC_RISD_Pixel16_OnOff : 23|1@0+ (1,0) [0|1] "" Vector__XXX
 SG_ ICC_RISD_Pixel15_OnOff : 22|1@0+ (1,0) [0|1] "" Vector__XXX
 SG_ ICC_RISD_Pixel14_OnOff : 21|1@0+ (1,0) [0|1] "" Vector__XXX
 SG_ ICC_RISD_Pixel13_OnOff : 20|1@0+ (1,0) [0|1] "" Vector__XXX
 SG_ ICC_RISD_Pixel12_OnOff : 19|1@0+ (1,0) [0|1] "" Vector__XXX
 SG_ ICC_RISD_Pixel11_OnOff : 18|1@0+ (1,0) [0|1] "" Vector__XXX
 SG_ ICC_RISD_Pixel10_OnOff : 17|1@0+ (1,0) [0|1] "" Vector__XXX
 SG_ ICC_RISD_Pixel9_OnOff : 16|1@0+ (1,0) [0|1] "" Vector__XXX
 SG_ ICC_RISD_Pixel8_OnOff : 15|1@0+ (1,0) [0|1] "" Vector__XXX
 SG_ ICC_RISD_Pixel7_OnOff : 14|1@0+ (1,0) [0|1] "" Vector__XXX
 SG_ ICC_RISD_Pixel6_OnOff : 13|1@0+ (1,0) [0|1] "" Vector__XXX
 SG_ ICC_RISD_Pixel5_OnOff : 12|1@0+ (1,0) [0|1] "" Vector__XXX
 SG_ ICC_RISD_Pixel4_OnOff : 11|1@0+ (1,0) [0|1] "" Vector__XXX
 SG_ ICC_RISD_Pixel3_OnOff : 10|1@0+ (1,0) [0|1] "" Vector__XXX
 SG_ ICC_RISD_Pixel2_OnOff : 9|1@0+ (1,0) [0|1] "" Vector__XXX
 SG_ ICC_RISD_Pixel1_OnOff : 8|1@0+ (1,0) [0|1] "" Vector__XXX
 SG_ ICC_RISD_RollingCounter : 3|2@0+ (1,0) [0|3] "" Vector__XXX
 SG_ ICC_RISD_FrameCounter : 1|2@0+ (1,0) [0|3] "" Vector__XXX

BO_ 1345 DVR_1: 16 DVR
 SG_ DVR_1_Sdcard_Sts : 26|3@0+ (1,0) [0|7] ""  ICC
 SG_ DVR_1_DVRFailReasons : 20|3@0+ (1,0) [0|7] ""  ICC
 SG_ DVR_1_RecordSts : 22|2@0+ (1,0) [0|3] ""  ICC

BO_ 1121 EAMP_1: 8 EAMP
 SG_ STAT_AMPNaviVolume : 3|4@0+ (1,0) [0|15] ""  ICC
 SG_ STAT_AMPVRVolume : 7|4@0+ (1,0) [0|15] ""  ICC
 SG_ STAT_AMPKeyTone : 9|2@0+ (1,0) [0|3] ""  ICC
 SG_ STAT_AMPMediaVolume : 15|6@0+ (1,0) [0|63] ""  ICC
 SG_ STAT_AMPPhoneVolume : 20|5@0+ (1,0) [0|31] ""  ICC
 SG_ STAT_AMPSoundFocus : 23|3@0+ (1,0) [0|7] ""  ICC
 SG_ STAT_AMPSoundEffect : 27|4@0+ (1,0) [0|15] ""  ICC
 SG_ STAT_AMPSoundEffectBass : 31|4@0+ (1,0) [0|15] ""  ICC
 SG_ STAT_AMPSoundEffectMidrange : 35|4@0+ (1,0) [0|15] ""  ICC
 SG_ STAT_AMPSoundEffectTreble : 39|4@0+ (1,0) [0|15] ""  ICC
 SG_ STAT_AMPSoundFieldBalance : 43|4@0+ (1,0) [0|15] ""  ICC
 SG_ STAT_AMPSoundFieldFader : 47|4@0+ (1,0) [0|15] ""  ICC
 SG_ STAT_REQ_AMPA2BMediaSound : 49|2@0+ (1,0) [0|3] ""  ICC
 SG_ STAT_REQ_AMPA2BNaviSound : 51|2@0+ (1,0) [0|3] ""  ICC
 SG_ STAT_REQ_AMPA2BVRSound : 53|2@0+ (1,0) [0|3] ""  ICC
 SG_ STAT_REQ_AMPA2BTTSSound : 55|2@0+ (1,0) [0|3] ""  ICC
 SG_ STAT_REQ_AMPA2BPhoneSound : 57|2@0+ (1,0) [0|3] ""  ICC
 SG_ STAT_REQ_AMPAlarm : 63|6@0+ (1,0) [0|63] ""  ICC

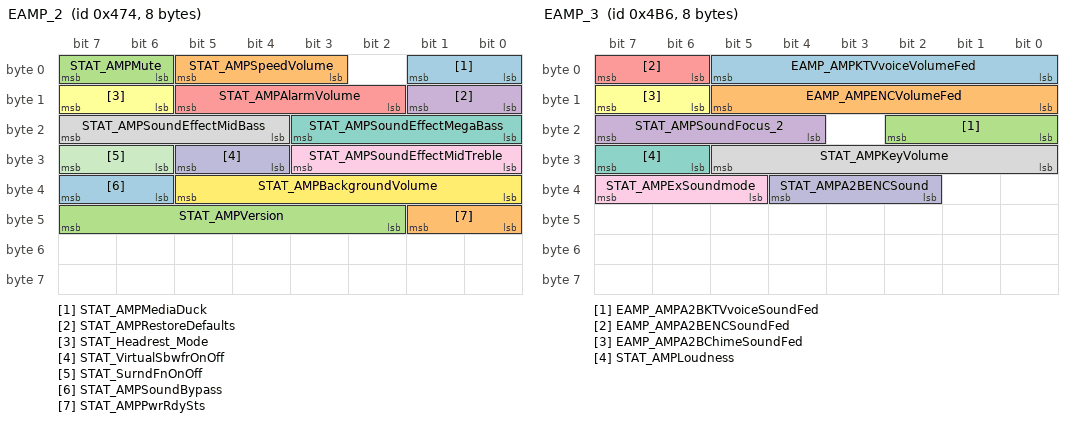
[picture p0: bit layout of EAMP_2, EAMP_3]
BO_ 1140 EAMP_2: 8 EAMP
 SG_ STAT_AMPMediaDuck : 1|2@0+ (1,0) [0|3] ""  ICC
 SG_ STAT_AMPSpeedVolume : 5|3@0+ (1,0) [0|7] ""  ICC
 SG_ STAT_AMPMute : 7|2@0+ (1,0) [0|3] ""  ICC
 SG_ STAT_AMPRestoreDefaults : 9|2@0+ (1,0) [0|3] ""  ICC
 SG_ STAT_AMPAlarmVolume : 13|4@0+ (1,0) [0|15] ""  ICC
 SG_ STAT_Headrest_Mode : 15|2@0+ (1,0) [0|3] ""  ICC
 SG_ STAT_AMPSoundEffectMegaBass : 19|4@0+ (1,0) [0|15] ""  ICC
 SG_ STAT_AMPSoundEffectMidBass : 23|4@0+ (1,0) [0|15] ""  ICC
 SG_ STAT_AMPSoundEffectMidTreble : 27|4@0+ (1,0) [0|15] ""  ICC
 SG_ STAT_VirtualSbwfrOnOff : 29|2@0+ (1,0) [0|3] ""  ICC
 SG_ STAT_SurndFnOnOff : 31|2@0+ (1,0) [0|3] ""  ICC
 SG_ STAT_AMPBackgroundVolume : 37|6@0+ (1,0) [0|63] ""  ICC
 SG_ STAT_AMPSoundBypass : 39|2@0+ (1,0) [0|3] ""  ICC
 SG_ STAT_AMPPwrRdySts : 41|2@0+ (1,0) [0|3] ""  ICC
 SG_ STAT_AMPVersion : 47|6@0+ (1,0) [0|63] ""  ICC

BO_ 1206 EAMP_3: 8 EAMP
 SG_ EAMP_AMPKTVvoiceVolumeFed : 5|6@0+ (1,0) [0|63] ""  ICC
 SG_ EAMP_AMPENCVolumeFed : 13|6@0+ (1,0) [0|63] ""  ICC
 SG_ EAMP_AMPA2BKTVvoiceSoundFed : 18|3@0+ (1,0) [0|7] ""  ICC
 SG_ STAT_AMPSoundFocus_2 : 23|4@0+ (1,0) [0|15] ""  ICC
 SG_ EAMP_AMPA2BENCSoundFed : 7|2@0+ (1,0) [0|3] ""  ICC
 SG_ EAMP_AMPA2BChimeSoundFed : 15|2@0+ (1,0) [0|3] ""  ICC
 SG_ STAT_AMPLoudness : 31|2@0+ (1,0) [0|3] ""  ICC
 SG_ STAT_AMPKeyVolume : 29|6@0+ (1,0) [0|63] ""  ICC
 SG_ STAT_AMPExSoundmode : 39|3@0+ (1,0) [0|7] ""  ICC
 SG_ STAT_AMPA2BENCSound : 36|3@0+ (1,0) [0|7] ""  ICC

BO_ 1078 PLG_1: 8 PCL
 SG_ PLG_LatchSts : 33|2@0+ (1,0) [0|3] ""  ICC,FLZCU_HCU_IC,FLZCU_IC,HCU_IC,TBOX,BNCM

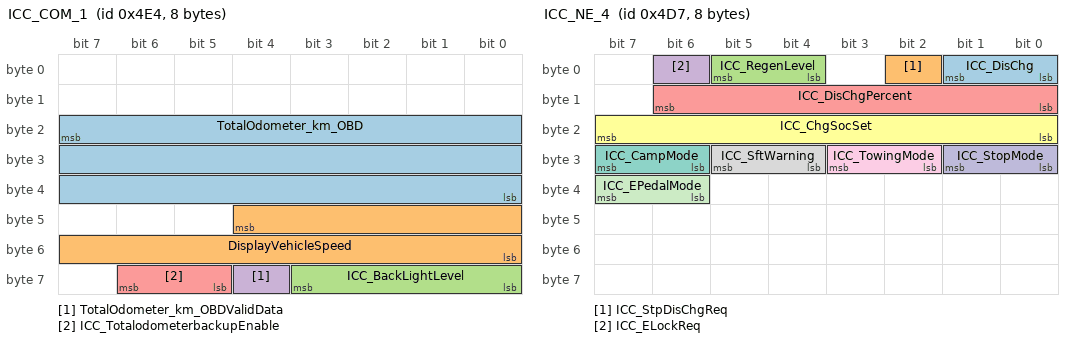
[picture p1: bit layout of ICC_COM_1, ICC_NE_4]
BO_ 1252 ICC_COM_1: 8 ICC
 SG_ TotalOdometer_km_OBD : 23|24@0+ (0.1,0) [0|999999.9] "km"  FLZCU_HCU_IC,FLZCU_IC,HCU_IC,TBOX,BNCM
 SG_ DisplayVehicleSpeed : 44|13@0+ (0.0625,0) [0|511.875] "km/h"  FLZCU_HCU_IC,FLZCU_IC,TBOX,BNCM
 SG_ ICC_BackLightLevel : 59|4@0+ (1,0) [0|15] ""  FLZCU_HCU_IC
 SG_ TotalOdometer_km_OBDValidData : 60|1@0+ (1,0) [0|1] ""  FLZCU_HCU_IC,FLZCU_IC,HCU_IC,TBOX,BNCM
 SG_ ICC_TotalodometerbackupEnable : 62|2@0+ (1,0) [0|3] ""  FLZCU_HCU_IC,FLZCU_IC

BO_ 1322 ICC_IC_2: 8 ICC
 SG_ STAT_AMPAlarm : 7|6@0+ (1,0) [0|63] ""  EAMP

BO_ 1176 ICC_CH_3: 8 ICC
 SG_ Fusa_498_6 : 51|2@0+ (1,0) [0|3] ""  CGW
 SG_ Fusa_498_5 : 45|4@0+ (1,0) [0|15] ""  CGW
 SG_ Fusa_498_4 : 34|3@0+ (1,0) [0|7] ""  CGW
 SG_ Fusa_498_3 : 39|3@0+ (1,0) [0|7] ""  CGW
 SG_ Fusa_498_2 : 31|4@0+ (1,0) [0|15] ""  CGW
 SG_ Fusa_498_1 : 15|2@0+ (1,0) [0|3] ""  CGW
 SG_ ICC_CH_3_CRC : 7|8@0+ (1,0) [0|255] ""  FLZCU_HCU_IC,FLZCU_Signal_IC,CGW
 SG_ ICC_CH_3_RollgCntr : 11|4@0+ (1,0) [0|14] ""  FLZCU_HCU_IC,FLZCU_Signal_IC,CGW
 SG_ ICC_ASUAssistPassSet : 13|2@0+ (1,0) [0|3] ""  FLZCU_HCU_IC,FLZCU_Signal_IC,CGW
 SG_ IHU_AutHldSet : 17|2@0+ (1,0) [0|3] ""  FLZCU_HCU_IC,FLZCU_Signal_IC,CGW
 SG_ ICC_AutoEasyEntrySet : 19|2@0+ (1,0) [0|3] ""  FLZCU_HCU_IC,FLZCU_Signal_IC,CGW
 SG_ ICC_ManualEasyOutSw : 21|2@0+ (1,0) [0|3] ""  FLZCU_HCU_IC,FLZCU_Signal_IC,CGW
 SG_ ICC_ASCMaintainModeReq : 23|2@0+ (1,0) [0|3] ""  FLZCU_HCU_IC,FLZCU_Signal_IC,CGW
 SG_ ICC_PABSetCmd : 25|2@0+ (1,0) [0|3] ""  FLZCU_HCU_IC,FLZCU_Signal_IC,CGW
 SG_ ICC_EPBSetCmd : 27|2@0+ (1,0) [0|3] ""  FLZCU_HCU_IC,FLZCU_Signal_IC,CGW
 SG_ ICC_ASUMemoryPosition : 36|2@0+ (1,0) [0|3] ""  FLZCU_HCU_IC,FLZCU_Signal_IC,CGW
 SG_ ICC_ASUEasyLoadingSet : 41|2@0+ (1,0) [0|3] ""  FLZCU_HCU_IC,FLZCU_Signal_IC,CGW
 SG_ Set_CSTFunctionSts : 47|2@0+ (1,0) [0|3] ""  FLZCU_HCU_IC,FLZCU_Signal_IC,CGW
 SG_ ICC_ASURearaxlewithTaildoor : 49|2@0+ (1,0) [0|3] ""  FLZCU_HCU_IC,FLZCU_Signal_IC,CGW
 SG_ CST_SensitivityReq : 53|2@0+ (1,0) [0|3] ""  FLZCU_HCU_IC,FLZCU_Signal_IC,CGW
 SG_ TIHU_SetHDCOnOff : 55|2@0+ (1,0) [0|3] ""  FLZCU_HCU_IC,FLZCU_Signal_IC,CGW
 SG_ Set_ESPFunctionSts : 57|2@0+ (1,0) [0|3] ""  FLZCU_HCU_IC,FLZCU_Signal_IC,CGW
 SG_ ICC_ASUPreviewCont : 59|2@0+ (1,0) [0|3] ""  FLZCU_HCU_IC,FLZCU_Signal_IC,CGW
 SG_ ICC_ASUHighwayModAdjust : 61|2@0+ (1,0) [0|3] ""  FLZCU_HCU_IC,FLZCU_Signal_IC,CGW
 SG_ ICC_ASUMapAdjust : 63|2@0+ (1,0) [0|3] ""  FLZCU_HCU_IC,FLZCU_Signal_IC,CGW

BO_ 1239 ICC_NE_4: 8 ICC
 SG_ ICC_DisChg : 1|2@0+ (1,0) [0|3] ""  FLZCU_HCU_IC,HCU_IC
 SG_ ICC_StpDisChgReq : 2|1@0+ (1,0) [0|1] "" Vector__XXX
 SG_ ICC_RegenLevel : 5|2@0+ (1,0) [0|3] "" Vector__XXX
 SG_ ICC_ELockReq : 6|1@0+ (1,0) [0|1] "" Vector__XXX
 SG_ ICC_DisChgPercent : 14|7@0+ (1,0) [1|100] "%"  FLZCU_HCU_IC,HCU_IC
 SG_ ICC_ChgSocSet : 23|8@0+ (1,0) [1|100] "%"  FLZCU_HCU_IC,HCU_IC
 SG_ ICC_CampMode : 31|2@0+ (1,0) [0|3] ""  FLZCU_HCU_IC,HCU_IC
 SG_ ICC_SftWarning : 29|2@0+ (1,0) [0|3] "" Vector__XXX
 SG_ ICC_TowingMode : 27|2@0+ (1,0) [0|3] ""  FLZCU_HCU_IC,HCU_IC
 SG_ ICC_StopMode : 25|2@0+ (1,0) [0|3] "" Vector__XXX
 SG_ ICC_EPedalMode : 39|2@0+ (1,0) [0|3] "" Vector__XXX

BO_ 1246 ICC_TMS_5: 32 ICC
 SG_ ICC_WindowKeySts : 1|2@0+ (1,0) [0|3] "" Vector__XXX
 SG_ ICC_FaceKeySts : 3|2@0+ (1,0) [0|3] "" Vector__XXX
 SG_ ICC_FootKeySts : 5|2@0+ (1,0) [0|3] "" Vector__XXX
 SG_ BltCallSts : 7|2@0+ (1,0) [0|3] "" Vector__XXX
 SG_ ICC_DockWinspSts : 9|2@0+ (1,0) [0|3] "" Vector__XXX
 SG_ ICC_DockTSts : 11|2@0+ (1,0) [0|3] "" Vector__XXX
 SG_ ICC_ACFastCool : 13|2@0+ (1,0) [0|3] "" Vector__XXX
 SG_ ICC_ACFastHeat : 15|2@0+ (1,0) [0|3] "" Vector__XXX
 SG_ ICC_SetCLMOn : 17|2@0+ (1,0) [0|3] "" Vector__XXX
 SG_ ICC_SetAutoKeySts : 19|2@0+ (1,0) [0|3] "" Vector__XXX
 SG_ ICC_SetFrontDeforestSts : 21|2@0+ (1,0) [0|3] "" Vector__XXX
 SG_ ICC_SetCirculationModeKeySts : 23|2@0+ (1,0) [0|3] "" Vector__XXX
 SG_ ICC_ZoneSelectionKeySts : 25|2@0+ (1,0) [0|3] "" Vector__XXX
 SG_ ICC_ResetFilter : 27|2@0+ (1,0) [0|3] "" Vector__XXX
 SG_ ICC_AUTODefrostOnKeySts : 29|2@0+ (1,0) [0|3] "" Vector__XXX
 SG_ ICC_AutoAirClean : 33|2@0+ (1,0) [0|3] "" Vector__XXX
 SG_ ICC_KeepWarm : 35|2@0+ (1,0) [0|3] ""  FLZCU_HCU_IC,HCU_IC
 SG_ ICC_BlowSpeedLevelKeySts : 39|4@0+ (1,0) [0|15] "" Vector__XXX
 SG_ ICC_SetACRequestKeySts : 42|3@0+ (1,0) [0|7] "" Vector__XXX
 SG_ ICC_DSwingSet : 45|3@0+ (1,0) [0|7] "" Vector__XXX
 SG_ ICC_PSwingSet : 50|3@0+ (1,0) [0|7] "" Vector__XXX
 SG_ ICC_AUTODefLevelSet : 58|3@0+ (1,0) [0|7] "" Vector__XXX
 SG_ ICC_SetTemperature_L_C : 55|5@0+ (0.5,15.5) [15.5|30.5] "℃" Vector__XXX
 SG_ ICC_SetTemperature_R_C : 63|5@0+ (0.5,15.5) [15.5|30.5] "℃" Vector__XXX
 SG_ ICC_DLSwingUpDwn : 70|7@0+ (1,0) [0|100] "%" Vector__XXX
 SG_ ICC_DLSwingLeRi : 78|7@0+ (1,0) [0|100] "%" Vector__XXX
 SG_ ICC_DRSwingUpDwn : 86|7@0+ (1,0) [0|100] "%" Vector__XXX
 SG_ ICC_DRSwingLeRi : 94|7@0+ (1,0) [0|100] "%" Vector__XXX
 SG_ ICC_PLSwingUpDwn : 102|7@0+ (1,0) [0|100] "%" Vector__XXX
 SG_ ICC_PLSwingLeRi : 110|7@0+ (1,0) [0|100] "%" Vector__XXX
 SG_ ICC_PRSwingUpDwn : 118|7@0+ (1,0) [0|100] "%" Vector__XXX
 SG_ ICC_PRSwingLeRi : 126|7@0+ (1,0) [0|100] "%" Vector__XXX
 SG_ ICC_DCSwingLeRi : 134|7@0+ (1,0) [0|100] "%" Vector__XXX
 SG_ ICC_NetWorkTemperature : 143|8@0+ (0.5,-40) [-40|85] "°C" Vector__XXX
 SG_ ICC_NetWorkHumidity : 151|8@0+ (0.5,-0.5) [0|100] "%" Vector__XXX
 SG_ ICC_DLOnOff : 201|2@0+ (1,0) [0|3] "" Vector__XXX
 SG_ ICC_DROnOff : 203|2@0+ (1,0) [0|3] "" Vector__XXX
 SG_ ICC_PLOnOff : 205|2@0+ (1,0) [0|3] "" Vector__XXX
 SG_ ICC_PROnOff : 207|2@0+ (1,0) [0|3] "" Vector__XXX
 SG_ ICC_DCOnOff : 209|2@0+ (1,0) [0|3] "" Vector__XXX
 SG_ ICC_LoveRemind : 211|2@0+ (1,0) [0|3] "" Vector__XXX
 SG_ ICC_InteCleanCar : 213|2@0+ (1,0) [0|3] "" Vector__XXX
 SG_ ICC_KeepWarmMemory : 223|2@0+ (1,0) [0|3] "" Vector__XXX

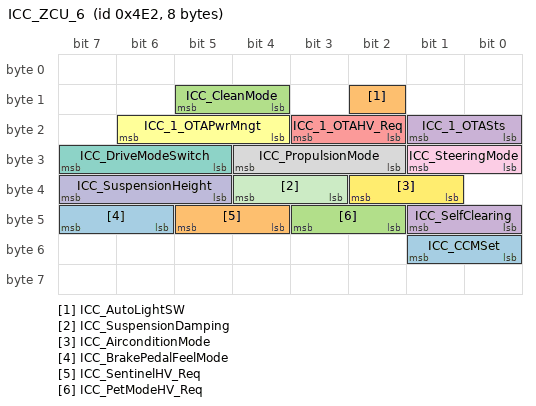
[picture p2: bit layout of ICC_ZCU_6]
BO_ 1250 ICC_ZCU_6: 8 ICC
 SG_ ICC_CCMSet : 49|2@0+ (1,0) [0|3] ""  FLZCU_HCU_IC,HCU_IC
 SG_ ICC_AutoLightSW : 10|1@0+ (1,0) [0|1] ""  FLZCU_HCU_IC,CGW
 SG_ ICC_CleanMode : 13|2@0+ (1,0) [0|3] ""  FLZCU_HCU_IC,FLZCU_IC,CGW
 SG_ ICC_1_OTASts : 17|2@0+ (1,0) [0|3] ""  FLZCU_HCU_IC,FLZCU_IC,HCU_IC,FLZCU_Signal_IC,CGW
 SG_ ICC_1_OTAHV_Req : 19|2@0+ (1,0) [0|3] ""  FLZCU_HCU_IC,FLZCU_IC,HCU_IC,CGW
 SG_ ICC_1_OTAPwrMngt : 22|3@0+ (1,0) [0|7] ""  FLZCU_HCU_IC,FLZCU_IC,CGW
 SG_ ICC_DriveModeSwitch : 31|3@0+ (1,0) [0|7] ""  FLZCU_HCU_IC,CGW
 SG_ ICC_PropulsionMode : 28|3@0+ (1,0) [0|7] ""  FLZCU_HCU_IC,CGW
 SG_ ICC_SteeringMode : 25|2@0+ (1,0) [0|3] ""  FLZCU_HCU_IC,HCU_IC,CGW
 SG_ ICC_SuspensionHeight : 39|3@0+ (1,0) [0|7] ""  FLZCU_HCU_IC,HCU_IC,CGW
 SG_ ICC_SuspensionDamping : 36|2@0+ (1,0) [0|3] ""  FLZCU_HCU_IC,HCU_IC,CGW
 SG_ ICC_AirconditionMode : 34|2@0+ (1,0) [0|3] ""  FLZCU_HCU_IC,CGW
 SG_ ICC_BrakePedalFeelMode : 47|2@0+ (1,0) [0|3] ""  FLZCU_HCU_IC,CGW
 SG_ ICC_SentinelHV_Req : 45|2@0+ (1,0) [0|3] ""  FLZCU_HCU_IC,HCU_IC,CGW
 SG_ ICC_PetModeHV_Req : 43|2@0+ (1,0) [0|3] ""  FLZCU_HCU_IC,HCU_IC,CGW
 SG_ ICC_SelfClearing : 41|2@0+ (1,0) [0|3] ""  FLZCU_HCU_IC,HCU_IC,CGW

BO_TX_BU_ 771 : FLZCU_HCU_IC,FLZCU_IC,FLZCU_Signal_IC;
BO_TX_BU_ 1035 : FLZCU_HCU_IC,FLZCU_IC,FLZCU_Signal_IC;

CM_ SG_ 1364 ICC_RISD_Pixel504_OnOff "对应像素点的亮灭";
CM_ SG_ 1364 ICC_RISD_Pixel503_OnOff "对应像素点的亮灭";
CM_ SG_ 1364 ICC_RISD_Pixel502_OnOff "对应像素点的亮灭";
CM_ SG_ 1364 ICC_RISD_Pixel501_OnOff "对应像素点的亮灭";
CM_ SG_ 1364 ICC_RISD_Pixel500_OnOff "对应像素点的亮灭";
CM_ SG_ 1364 ICC_RISD_Pixel499_OnOff "对应像素点的亮灭";
CM_ SG_ 1364 ICC_RISD_Pixel498_OnOff "对应像素点的亮灭";
CM_ SG_ 1364 ICC_RISD_Pixel497_OnOff "对应像素点的亮灭";
CM_ SG_ 1364 ICC_RISD_Pixel496_OnOff "对应像素点的亮灭";
CM_ SG_ 1364 ICC_RISD_Pixel495_OnOff "对应像素点的亮灭";
CM_ SG_ 1364 ICC_RISD_Pixel494_OnOff "对应像素点的亮灭";
CM_ SG_ 1364 ICC_RISD_Pixel493_OnOff "对应像素点的亮灭";
CM_ SG_ 1364 ICC_RISD_Pixel492_OnOff "对应像素点的亮灭";
CM_ SG_ 1364 ICC_RISD_Pixel491_OnOff "对应像素点的亮灭";
CM_ SG_ 1364 ICC_RISD_Pixel490_OnOff "对应像素点的亮灭";
CM_ SG_ 1364 ICC_RISD_Pixel489_OnOff "对应像素点的亮灭";
CM_ SG_ 1364 ICC_RISD_Pixel488_OnOff "对应像素点的亮灭";
CM_ SG_ 1364 ICC_RISD_Pixel487_OnOff "对应像素点的亮灭";
CM_ SG_ 1364 ICC_RISD_Pixel486_OnOff "对应像素点的亮灭";
CM_ SG_ 1364 ICC_RISD_Pixel485_OnOff "对应像素点的亮灭";
CM_ SG_ 1364 ICC_RISD_Pixel484_OnOff "对应像素点的亮灭";
CM_ SG_ 1364 ICC_RISD_Pixel483_OnOff "对应像素点的亮灭";
CM_ SG_ 1364 ICC_RISD_Pixel482_OnOff "对应像素点的亮灭";
CM_ SG_ 1364 ICC_RISD_Pixel481_OnOff "对应像素点的亮灭";
CM_ SG_ 1364 ICC_RISD_Pixel480_OnOff "对应像素点的亮灭";
CM_ SG_ 1364 ICC_RISD_Pixel479_OnOff "对应像素点的亮灭";
CM_ SG_ 1364 ICC_RISD_Pixel478_OnOff "对应像素点的亮灭";
CM_ SG_ 1364 ICC_RISD_Pixel477_OnOff "对应像素点的亮灭";
CM_ SG_ 1364 ICC_RISD_Pixel476_OnOff "对应像素点的亮灭";
CM_ SG_ 1364 ICC_RISD_Pixel475_OnOff "对应像素点的亮灭";
CM_ SG_ 1364 ICC_RISD_Pixel474_OnOff "对应像素点的亮灭";
CM_ SG_ 1364 ICC_RISD_Pixel473_OnOff "对应像素点的亮灭";
CM_ SG_ 1364 ICC_RISD_Pixel472_OnOff "对应像素点的亮灭";
CM_ SG_ 1364 ICC_RISD_Pixel471_OnOff "对应像素点的亮灭";
CM_ SG_ 1364 ICC_RISD_Pixel470_OnOff "对应像素点的亮灭";
CM_ SG_ 1364 ICC_RISD_Pixel469_OnOff "对应像素点的亮灭";
CM_ SG_ 1364 ICC_RISD_Pixel468_OnOff "对应像素点的亮灭";
CM_ SG_ 1364 ICC_RISD_Pixel467_OnOff "对应像素点的亮灭";
CM_ SG_ 1364 ICC_RISD_Pixel466_OnOff "对应像素点的亮灭";
CM_ SG_ 1364 ICC_RISD_Pixel465_OnOff "对应像素点的亮灭";
CM_ SG_ 1364 ICC_RISD_Pixel464_OnOff "对应像素点的亮灭";
CM_ SG_ 1364 ICC_RISD_Pixel463_OnOff "对应像素点的亮灭";
CM_ SG_ 1364 ICC_RISD_Pixel462_OnOff "对应像素点的亮灭";
CM_ SG_ 1364 ICC_RISD_Pixel461_OnOff "对应像素点的亮灭";
CM_ SG_ 1364 ICC_RISD_Pixel460_OnOff "对应像素点的亮灭";
CM_ SG_ 1364 ICC_RISD_Pixel459_OnOff "对应像素点的亮灭";
CM_ SG_ 1364 ICC_RISD_Pixel458_OnOff "对应像素点的亮灭";
CM_ SG_ 1364 ICC_RISD_Pixel457_OnOff "对应像素点的亮灭";
CM_ SG_ 1364 ICC_RISD_Pixel456_OnOff "对应像素点的亮灭";
CM_ SG_ 1364 ICC_RISD_Pixel455_OnOff "对应像素点的亮灭";
CM_ SG_ 1364 ICC_RISD_Pixel454_OnOff "对应像素点的亮灭";
CM_ SG_ 1364 ICC_RISD_Pixel453_OnOff "对应像素点的亮灭";
CM_ SG_ 1364 ICC_RISD_Pixel452_OnOff "对应像素点的亮灭";
CM_ SG_ 1364 ICC_RISD_Pixel451_OnOff "对应像素点的亮灭";
CM_ SG_ 1364 ICC_RISD_Pixel450_OnOff "对应像素点的亮灭";
CM_ SG_ 1364 ICC_RISD_Pixel449_OnOff "对应像素点的亮灭";
CM_ SG_ 1364 ICC_RISD_Pixel448_OnOff "对应像素点的亮灭";
CM_ SG_ 1364 ICC_RISD_Pixel447_OnOff "对应像素点的亮灭";
CM_ SG_ 1364 ICC_RISD_Pixel446_OnOff "对应像素点的亮灭";
CM_ SG_ 1364 ICC_RISD_Pixel445_OnOff "对应像素点的亮灭";
CM_ SG_ 1364 ICC_RISD_Pixel444_OnOff "对应像素点的亮灭";
CM_ SG_ 1364 ICC_RISD_Pixel443_OnOff "对应像素点的亮灭";
CM_ SG_ 1364 ICC_RISD_Pixel442_OnOff "对应像素点的亮灭";
CM_ SG_ 1364 ICC_RISD_Pixel441_OnOff "对应像素点的亮灭";
CM_ SG_ 1364 ICC_RISD_Pixel440_OnOff "对应像素点的亮灭";
CM_ SG_ 1364 ICC_RISD_Pixel439_OnOff "对应像素点的亮灭";
CM_ SG_ 1364 ICC_RISD_Pixel438_OnOff "对应像素点的亮灭";
CM_ SG_ 1364 ICC_RISD_Pixel437_OnOff "对应像素点的亮灭";
CM_ SG_ 1364 ICC_RISD_Pixel436_OnOff "对应像素点的亮灭";
CM_ SG_ 1364 ICC_RISD_Pixel435_OnOff "对应像素点的亮灭";
CM_ SG_ 1364 ICC_RISD_Pixel434_OnOff "对应像素点的亮灭";
CM_ SG_ 1364 ICC_RISD_Pixel433_OnOff "对应像素点的亮灭";
CM_ SG_ 1364 ICC_RISD_Pixel432_OnOff "对应像素点的亮灭";
CM_ SG_ 1364 ICC_RISD_Pixel431_OnOff "对应像素点的亮灭";
CM_ SG_ 1364 ICC_RISD_Pixel430_OnOff "对应像素点的亮灭";
CM_ SG_ 1364 ICC_RISD_Pixel429_OnOff "对应像素点的亮灭";
CM_ SG_ 1364 ICC_RISD_Pixel428_OnOff "对应像素点的亮灭";
CM_ SG_ 1364 ICC_RISD_Pixel427_OnOff "对应像素点的亮灭";
CM_ SG_ 1364 ICC_RISD_Pixel426_OnOff "对应像素点的亮灭";
CM_ SG_ 1364 ICC_RISD_Pixel425_OnOff "对应像素点的亮灭";
CM_ SG_ 1364 ICC_RISD_Pixel424_OnOff "对应像素点的亮灭";
CM_ SG_ 1364 ICC_RISD_Pixel423_OnOff "对应像素点的亮灭";
CM_ SG_ 1364 ICC_RISD_Pixel422_OnOff "对应像素点的亮灭";
CM_ SG_ 1364 ICC_RISD_Pixel421_OnOff "对应像素点的亮灭";
CM_ SG_ 1364 ICC_RISD_Pixel420_OnOff "对应像素点的亮灭";
CM_ SG_ 1364 ICC_RISD_Pixel419_OnOff "对应像素点的亮灭";
CM_ SG_ 1364 ICC_RISD_Pixel418_OnOff "对应像素点的亮灭";
CM_ SG_ 1364 ICC_RISD_Pixel417_OnOff "对应像素点的亮灭";
CM_ SG_ 1364 ICC_RISD_Pixel416_OnOff "对应像素点的亮灭";
CM_ SG_ 1364 ICC_RISD_Pixel415_OnOff "对应像素点的亮灭";
CM_ SG_ 1364 ICC_RISD_Pixel414_OnOff "对应像素点的亮灭";
CM_ SG_ 1364 ICC_RISD_Pixel413_OnOff "对应像素点的亮灭";
CM_ SG_ 1364 ICC_RISD_Pixel412_OnOff "对应像素点的亮灭";
CM_ SG_ 1364 ICC_RISD_Pixel411_OnOff "对应像素点的亮灭";
CM_ SG_ 1364 ICC_RISD_Pixel410_OnOff "对应像素点的亮灭";
CM_ SG_ 1364 ICC_RISD_Pixel409_OnOff "对应像素点的亮灭";
CM_ SG_ 1364 ICC_RISD_Pixel408_OnOff "对应像素点的亮灭";
CM_ SG_ 1364 ICC_RISD_Pixel407_OnOff "对应像素点的亮灭";
CM_ SG_ 1364 ICC_RISD_Pixel406_OnOff "对应像素点的亮灭";
CM_ SG_ 1364 ICC_RISD_Pixel405_OnOff "对应像素点的亮灭";
CM_ SG_ 1364 ICC_RISD_Pixel404_OnOff "对应像素点的亮灭";
CM_ SG_ 1364 ICC_RISD_Pixel403_OnOff "对应像素点的亮灭";
CM_ SG_ 1364 ICC_RISD_Pixel402_OnOff "对应像素点的亮灭";
CM_ SG_ 1364 ICC_RISD_Pixel401_OnOff "对应像素点的亮灭";
CM_ SG_ 1364 ICC_RISD_Pixel400_OnOff "对应像素点的亮灭";
CM_ SG_ 1364 ICC_RISD_Pixel399_OnOff "对应像素点的亮灭";
CM_ SG_ 1364 ICC_RISD_Pixel398_OnOff "对应像素点的亮灭";
CM_ SG_ 1364 ICC_RISD_Pixel397_OnOff "对应像素点的亮灭";
CM_ SG_ 1364 ICC_RISD_Pixel396_OnOff "对应像素点的亮灭";
CM_ SG_ 1364 ICC_RISD_Pixel395_OnOff "对应像素点的亮灭";
CM_ SG_ 1364 ICC_RISD_Pixel394_OnOff "对应像素点的亮灭";
CM_ SG_ 1364 ICC_RISD_Pixel393_OnOff "对应像素点的亮灭";
CM_ SG_ 1364 ICC_RISD_Pixel392_OnOff "对应像素点的亮灭";
CM_ SG_ 1364 ICC_RISD_Pixel391_OnOff "对应像素点的亮灭";
CM_ SG_ 1364 ICC_RISD_Pixel390_OnOff "对应像素点的亮灭";
CM_ SG_ 1364 ICC_RISD_Pixel389_OnOff "对应像素点的亮灭";
CM_ SG_ 1364 ICC_RISD_Pixel388_OnOff "对应像素点的亮灭";
CM_ SG_ 1364 ICC_RISD_Pixel387_OnOff "对应像素点的亮灭";
CM_ SG_ 1364 ICC_RISD_Pixel386_OnOff "对应像素点的亮灭";
CM_ SG_ 1364 ICC_RISD_Pixel385_OnOff "对应像素点的亮灭";
CM_ SG_ 1364 ICC_RISD_Pixel384_OnOff "对应像素点的亮灭";
CM_ SG_ 1364 ICC_RISD_Pixel383_OnOff "对应像素点的亮灭";
CM_ SG_ 1364 ICC_RISD_Pixel382_OnOff "对应像素点的亮灭";
CM_ SG_ 1364 ICC_RISD_Pixel381_OnOff "对应像素点的亮灭";
CM_ SG_ 1364 ICC_RISD_Pixel380_OnOff "对应像素点的亮灭";
CM_ SG_ 1364 ICC_RISD_Pixel379_OnOff "对应像素点的亮灭";
CM_ SG_ 1364 ICC_RISD_Pixel378_OnOff "对应像素点的亮灭";
CM_ SG_ 1364 ICC_RISD_Pixel377_OnOff "对应像素点的亮灭";
CM_ SG_ 1364 ICC_RISD_Pixel376_OnOff "对应像素点的亮灭";
CM_ SG_ 1364 ICC_RISD_Pixel375_OnOff "对应像素点的亮灭";
CM_ SG_ 1364 ICC_RISD_Pixel374_OnOff "对应像素点的亮灭";
CM_ SG_ 1364 ICC_RISD_Pixel373_OnOff "对应像素点的亮灭";
CM_ SG_ 1364 ICC_RISD_Pixel372_OnOff "对应像素点的亮灭";
CM_ SG_ 1364 ICC_RISD_Pixel371_OnOff "对应像素点的亮灭";
CM_ SG_ 1364 ICC_RISD_Pixel370_OnOff "对应像素点的亮灭";
CM_ SG_ 1364 ICC_RISD_Pixel369_OnOff "对应像素点的亮灭";
CM_ SG_ 1364 ICC_RISD_Pixel368_OnOff "对应像素点的亮灭";
CM_ SG_ 1364 ICC_RISD_Pixel367_OnOff "对应像素点的亮灭";
CM_ SG_ 1364 ICC_RISD_Pixel366_OnOff "对应像素点的亮灭";
CM_ SG_ 1364 ICC_RISD_Pixel365_OnOff "对应像素点的亮灭";
CM_ SG_ 1364 ICC_RISD_Pixel364_OnOff "对应像素点的亮灭";
CM_ SG_ 1364 ICC_RISD_Pixel363_OnOff "对应像素点的亮灭";
CM_ SG_ 1364 ICC_RISD_Pixel362_OnOff "对应像素点的亮灭";
CM_ SG_ 1364 ICC_RISD_Pixel361_OnOff "对应像素点的亮灭";
CM_ SG_ 1364 ICC_RISD_Pixel360_OnOff "对应像素点的亮灭";
CM_ SG_ 1364 ICC_RISD_Pixel359_OnOff "对应像素点的亮灭";
CM_ SG_ 1364 ICC_RISD_Pixel358_OnOff "对应像素点的亮灭";
CM_ SG_ 1364 ICC_RISD_Pixel357_OnOff "对应像素点的亮灭";
CM_ SG_ 1364 ICC_RISD_Pixel356_OnOff "对应像素点的亮灭";
CM_ SG_ 1364 ICC_RISD_Pixel355_OnOff "对应像素点的亮灭";
CM_ SG_ 1364 ICC_RISD_Pixel354_OnOff "对应像素点的亮灭";
CM_ SG_ 1364 ICC_RISD_Pixel353_OnOff "对应像素点的亮灭";
CM_ SG_ 1364 ICC_RISD_Pixel352_OnOff "对应像素点的亮灭";
CM_ SG_ 1364 ICC_RISD_Pixel351_OnOff "对应像素点的亮灭";
CM_ SG_ 1364 ICC_RISD_Pixel350_OnOff "对应像素点的亮灭";
CM_ SG_ 1364 ICC_RISD_Pixel349_OnOff "对应像素点的亮灭";
CM_ SG_ 1364 ICC_RISD_Pixel348_OnOff "对应像素点的亮灭";
CM_ SG_ 1364 ICC_RISD_Pixel347_OnOff "对应像素点的亮灭";
CM_ SG_ 1364 ICC_RISD_Pixel346_OnOff "对应像素点的亮灭";
CM_ SG_ 1364 ICC_RISD_Pixel345_OnOff "对应像素点的亮灭";
CM_ SG_ 1364 ICC_RISD_Pixel344_OnOff "对应像素点的亮灭";
CM_ SG_ 1364 ICC_RISD_Pixel343_OnOff "对应像素点的亮灭";
CM_ SG_ 1364 ICC_RISD_Pixel342_OnOff "对应像素点的亮灭";
CM_ SG_ 1364 ICC_RISD_Pixel341_OnOff "对应像素点的亮灭";
CM_ SG_ 1364 ICC_RISD_Pixel340_OnOff "对应像素点的亮灭";
CM_ SG_ 1364 ICC_RISD_Pixel339_OnOff "对应像素点的亮灭";
CM_ SG_ 1364 ICC_RISD_Pixel338_OnOff "对应像素点的亮灭";
CM_ SG_ 1364 ICC_RISD_Pixel337_OnOff "对应像素点的亮灭";
CM_ SG_ 1364 ICC_RISD_Pixel336_OnOff "对应像素点的亮灭";
CM_ SG_ 1364 ICC_RISD_Pixel335_OnOff "对应像素点的亮灭";
CM_ SG_ 1364 ICC_RISD_Pixel334_OnOff "对应像素点的亮灭";
CM_ SG_ 1364 ICC_RISD_Pixel333_OnOff "对应像素点的亮灭";
CM_ SG_ 1364 ICC_RISD_Pixel332_OnOff "对应像素点的亮灭";
CM_ SG_ 1364 ICC_RISD_Pixel331_OnOff "对应像素点的亮灭";
CM_ SG_ 1364 ICC_RISD_Pixel330_OnOff "对应像素点的亮灭";
CM_ SG_ 1364 ICC_RISD_Pixel329_OnOff "对应像素点的亮灭";
CM_ SG_ 1364 ICC_RISD_Pixel328_OnOff "对应像素点的亮灭";
CM_ SG_ 1364 ICC_RISD_Pixel327_OnOff "对应像素点的亮灭";
CM_ SG_ 1364 ICC_RISD_Pixel326_OnOff "对应像素点的亮灭";
CM_ SG_ 1364 ICC_RISD_Pixel325_OnOff "对应像素点的亮灭";
CM_ SG_ 1364 ICC_RISD_Pixel324_OnOff "对应像素点的亮灭";
CM_ SG_ 1364 ICC_RISD_Pixel323_OnOff "对应像素点的亮灭";
CM_ SG_ 1364 ICC_RISD_Pixel322_OnOff "对应像素点的亮灭";
CM_ SG_ 1364 ICC_RISD_Pixel321_OnOff "对应像素点的亮灭";
CM_ SG_ 1364 ICC_RISD_Pixel320_OnOff "对应像素点的亮灭";
CM_ SG_ 1364 ICC_RISD_Pixel319_OnOff "对应像素点的亮灭";
CM_ SG_ 1364 ICC_RISD_Pixel318_OnOff "对应像素点的亮灭";
CM_ SG_ 1364 ICC_RISD_Pixel317_OnOff "对应像素点的亮灭";
CM_ SG_ 1364 ICC_RISD_Pixel316_OnOff "对应像素点的亮灭";
CM_ SG_ 1364 ICC_RISD_Pixel315_OnOff "对应像素点的亮灭";
CM_ SG_ 1364 ICC_RISD_Pixel314_OnOff "对应像素点的亮灭";
CM_ SG_ 1364 ICC_RISD_Pixel313_OnOff "对应像素点的亮灭";
CM_ SG_ 1364 ICC_RISD_Pixel312_OnOff "对应像素点的亮灭";
CM_ SG_ 1364 ICC_RISD_Pixel311_OnOff "对应像素点的亮灭";
CM_ SG_ 1364 ICC_RISD_Pixel310_OnOff "对应像素点的亮灭";
CM_ SG_ 1364 ICC_RISD_Pixel309_OnOff "对应像素点的亮灭";
CM_ SG_ 1364 ICC_RISD_Pixel308_OnOff "对应像素点的亮灭";
CM_ SG_ 1364 ICC_RISD_Pixel307_OnOff "对应像素点的亮灭";
CM_ SG_ 1364 ICC_RISD_Pixel306_OnOff "对应像素点的亮灭";
CM_ SG_ 1364 ICC_RISD_Pixel305_OnOff "对应像素点的亮灭";
CM_ SG_ 1364 ICC_RISD_Pixel304_OnOff "对应像素点的亮灭";
CM_ SG_ 1364 ICC_RISD_Pixel303_OnOff "对应像素点的亮灭";
CM_ SG_ 1364 ICC_RISD_Pixel302_OnOff "对应像素点的亮灭";
CM_ SG_ 1364 ICC_RISD_Pixel301_OnOff "对应像素点的亮灭";
CM_ SG_ 1364 ICC_RISD_Pixel300_OnOff "对应像素点的亮灭";
CM_ SG_ 1364 ICC_RISD_Pixel299_OnOff "对应像素点的亮灭";
CM_ SG_ 1364 ICC_RISD_Pixel298_OnOff "对应像素点的亮灭";
CM_ SG_ 1364 ICC_RISD_Pixel297_OnOff "对应像素点的亮灭";
CM_ SG_ 1364 ICC_RISD_Pixel296_OnOff "对应像素点的亮灭";
CM_ SG_ 1364 ICC_RISD_Pixel295_OnOff "对应像素点的亮灭";
CM_ SG_ 1364 ICC_RISD_Pixel294_OnOff "对应像素点的亮灭";
CM_ SG_ 1364 ICC_RISD_Pixel293_OnOff "对应像素点的亮灭";
CM_ SG_ 1364 ICC_RISD_Pixel292_OnOff "对应像素点的亮灭";
CM_ SG_ 1364 ICC_RISD_Pixel291_OnOff "对应像素点的亮灭";
CM_ SG_ 1364 ICC_RISD_Pixel290_OnOff "对应像素点的亮灭";
CM_ SG_ 1364 ICC_RISD_Pixel289_OnOff "对应像素点的亮灭";
CM_ SG_ 1364 ICC_RISD_Pixel288_OnOff "对应像素点的亮灭";
CM_ SG_ 1364 ICC_RISD_Pixel287_OnOff "对应像素点的亮灭";
CM_ SG_ 1364 ICC_RISD_Pixel286_OnOff "对应像素点的亮灭";
CM_ SG_ 1364 ICC_RISD_Pixel285_OnOff "对应像素点的亮灭";
CM_ SG_ 1364 ICC_RISD_Pixel284_OnOff "对应像素点的亮灭";
CM_ SG_ 1364 ICC_RISD_Pixel283_OnOff "对应像素点的亮灭";
CM_ SG_ 1364 ICC_RISD_Pixel282_OnOff "对应像素点的亮灭";
CM_ SG_ 1364 ICC_RISD_Pixel281_OnOff "对应像素点的亮灭";
CM_ SG_ 1364 ICC_RISD_Pixel280_OnOff "对应像素点的亮灭";
CM_ SG_ 1364 ICC_RISD_Pixel279_OnOff "对应像素点的亮灭";
CM_ SG_ 1364 ICC_RISD_Pixel278_OnOff "对应像素点的亮灭";
CM_ SG_ 1364 ICC_RISD_Pixel277_OnOff "对应像素点的亮灭";
CM_ SG_ 1364 ICC_RISD_Pixel276_OnOff "对应像素点的亮灭";
CM_ SG_ 1364 ICC_RISD_Pixel275_OnOff "对应像素点的亮灭";
CM_ SG_ 1364 ICC_RISD_Pixel274_OnOff "对应像素点的亮灭";
CM_ SG_ 1364 ICC_RISD_Pixel273_OnOff "对应像素点的亮灭";
CM_ SG_ 1364 ICC_RISD_Pixel272_OnOff "对应像素点的亮灭";
CM_ SG_ 1364 ICC_RISD_Pixel271_OnOff "对应像素点的亮灭";
CM_ SG_ 1364 ICC_RISD_Pixel270_OnOff "对应像素点的亮灭";
CM_ SG_ 1364 ICC_RISD_Pixel269_OnOff "对应像素点的亮灭";
CM_ SG_ 1364 ICC_RISD_Pixel268_OnOff "对应像素点的亮灭";
CM_ SG_ 1364 ICC_RISD_Pixel267_OnOff "对应像素点的亮灭";
CM_ SG_ 1364 ICC_RISD_Pixel266_OnOff "对应像素点的亮灭";
CM_ SG_ 1364 ICC_RISD_Pixel265_OnOff "对应像素点的亮灭";
CM_ SG_ 1364 ICC_RISD_Pixel264_OnOff "对应像素点的亮灭";
CM_ SG_ 1364 ICC_RISD_Pixel263_OnOff "对应像素点的亮灭";
CM_ SG_ 1364 ICC_RISD_Pixel262_OnOff "对应像素点的亮灭";
CM_ SG_ 1364 ICC_RISD_Pixel261_OnOff "对应像素点的亮灭";
CM_ SG_ 1364 ICC_RISD_Pixel260_OnOff "对应像素点的亮灭";
CM_ SG_ 1364 ICC_RISD_Pixel259_OnOff "对应像素点的亮灭";
CM_ SG_ 1364 ICC_RISD_Pixel258_OnOff "对应像素点的亮灭";
CM_ SG_ 1364 ICC_RISD_Pixel257_OnOff "对应像素点的亮灭";
CM_ SG_ 1364 ICC_RISD_Pixel256_OnOff "对应像素点的亮灭";
CM_ SG_ 1364 ICC_RISD_Pixel255_OnOff "对应像素点的亮灭";
CM_ SG_ 1364 ICC_RISD_Pixel254_OnOff "对应像素点的亮灭";
CM_ SG_ 1364 ICC_RISD_Pixel253_OnOff "对应像素点的亮灭";
CM_ SG_ 1364 ICC_RISD_Pixel252_OnOff "对应像素点的亮灭";
CM_ SG_ 1364 ICC_RISD_Pixel251_OnOff "对应像素点的亮灭";
CM_ SG_ 1364 ICC_RISD_Pixel250_OnOff "对应像素点的亮灭";
CM_ SG_ 1364 ICC_RISD_Pixel249_OnOff "对应像素点的亮灭";
CM_ SG_ 1364 ICC_RISD_Pixel248_OnOff "对应像素点的亮灭";
CM_ SG_ 1364 ICC_RISD_Pixel247_OnOff "对应像素点的亮灭";
CM_ SG_ 1364 ICC_RISD_Pixel246_OnOff "对应像素点的亮灭";
CM_ SG_ 1364 ICC_RISD_Pixel245_OnOff "对应像素点的亮灭";
CM_ SG_ 1364 ICC_RISD_Pixel244_OnOff "对应像素点的亮灭";
CM_ SG_ 1364 ICC_RISD_Pixel243_OnOff "对应像素点的亮灭";
CM_ SG_ 1364 ICC_RISD_Pixel242_OnOff "对应像素点的亮灭";
CM_ SG_ 1364 ICC_RISD_Pixel241_OnOff "对应像素点的亮灭";
CM_ SG_ 1364 ICC_RISD_Pixel240_OnOff "对应像素点的亮灭";
CM_ SG_ 1364 ICC_RISD_Pixel239_OnOff "对应像素点的亮灭";
CM_ SG_ 1364 ICC_RISD_Pixel238_OnOff "对应像素点的亮灭";
CM_ SG_ 1364 ICC_RISD_Pixel237_OnOff "对应像素点的亮灭";
CM_ SG_ 1364 ICC_RISD_Pixel236_OnOff "对应像素点的亮灭";
CM_ SG_ 1364 ICC_RISD_Pixel235_OnOff "对应像素点的亮灭";
CM_ SG_ 1364 ICC_RISD_Pixel234_OnOff "对应像素点的亮灭";
CM_ SG_ 1364 ICC_RISD_Pixel233_OnOff "对应像素点的亮灭";
CM_ SG_ 1364 ICC_RISD_Pixel232_OnOff "对应像素点的亮灭";
CM_ SG_ 1364 ICC_RISD_Pixel231_OnOff "对应像素点的亮灭";
CM_ SG_ 1364 ICC_RISD_Pixel230_OnOff "对应像素点的亮灭";
CM_ SG_ 1364 ICC_RISD_Pixel229_OnOff "对应像素点的亮灭";
CM_ SG_ 1364 ICC_RISD_Pixel228_OnOff "对应像素点的亮灭";
CM_ SG_ 1364 ICC_RISD_Pixel227_OnOff "对应像素点的亮灭";
CM_ SG_ 1364 ICC_RISD_Pixel226_OnOff "对应像素点的亮灭";
CM_ SG_ 1364 ICC_RISD_Pixel225_OnOff "对应像素点的亮灭";
CM_ SG_ 1364 ICC_RISD_Pixel224_OnOff "对应像素点的亮灭";
CM_ SG_ 1364 ICC_RISD_Pixel223_OnOff "对应像素点的亮灭";
CM_ SG_ 1364 ICC_RISD_Pixel222_OnOff "对应像素点的亮灭";
CM_ SG_ 1364 ICC_RISD_Pixel221_OnOff "对应像素点的亮灭";
CM_ SG_ 1364 ICC_RISD_Pixel220_OnOff "对应像素点的亮灭";
CM_ SG_ 1364 ICC_RISD_Pixel219_OnOff "对应像素点的亮灭";
CM_ SG_ 1364 ICC_RISD_Pixel218_OnOff "对应像素点的亮灭";
CM_ SG_ 1364 ICC_RISD_Pixel217_OnOff "对应像素点的亮灭";
CM_ SG_ 1364 ICC_RISD_Pixel216_OnOff "对应像素点的亮灭";
CM_ SG_ 1364 ICC_RISD_Pixel215_OnOff "对应像素点的亮灭";
CM_ SG_ 1364 ICC_RISD_Pixel214_OnOff "对应像素点的亮灭";
CM_ SG_ 1364 ICC_RISD_Pixel213_OnOff "对应像素点的亮灭";
CM_ SG_ 1364 ICC_RISD_Pixel212_OnOff "对应像素点的亮灭";
CM_ SG_ 1364 ICC_RISD_Pixel211_OnOff "对应像素点的亮灭";
CM_ SG_ 1364 ICC_RISD_Pixel210_OnOff "对应像素点的亮灭";
CM_ SG_ 1364 ICC_RISD_Pixel209_OnOff "对应像素点的亮灭";
CM_ SG_ 1364 ICC_RISD_Pixel208_OnOff "对应像素点的亮灭";
CM_ SG_ 1364 ICC_RISD_Pixel207_OnOff "对应像素点的亮灭";
CM_ SG_ 1364 ICC_RISD_Pixel206_OnOff "对应像素点的亮灭";
CM_ SG_ 1364 ICC_RISD_Pixel205_OnOff "对应像素点的亮灭";
CM_ SG_ 1364 ICC_RISD_Pixel204_OnOff "对应像素点的亮灭";
CM_ SG_ 1364 ICC_RISD_Pixel203_OnOff "对应像素点的亮灭";
CM_ SG_ 1364 ICC_RISD_Pixel202_OnOff "对应像素点的亮灭";
CM_ SG_ 1364 ICC_RISD_Pixel201_OnOff "对应像素点的亮灭";
CM_ SG_ 1364 ICC_RISD_Pixel200_OnOff "对应像素点的亮灭";
CM_ SG_ 1364 ICC_RISD_Pixel199_OnOff "对应像素点的亮灭";
CM_ SG_ 1364 ICC_RISD_Pixel198_OnOff "对应像素点的亮灭";
CM_ SG_ 1364 ICC_RISD_Pixel197_OnOff "对应像素点的亮灭";
CM_ SG_ 1364 ICC_RISD_Pixel196_OnOff "对应像素点的亮灭";
CM_ SG_ 1364 ICC_RISD_Pixel195_OnOff "对应像素点的亮灭";
CM_ SG_ 1364 ICC_RISD_Pixel194_OnOff "对应像素点的亮灭";
CM_ SG_ 1364 ICC_RISD_Pixel193_OnOff "对应像素点的亮灭";
CM_ SG_ 1364 ICC_RISD_Pixel192_OnOff "对应像素点的亮灭";
CM_ SG_ 1364 ICC_RISD_Pixel191_OnOff "对应像素点的亮灭";
CM_ SG_ 1364 ICC_RISD_Pixel190_OnOff "对应像素点的亮灭";
CM_ SG_ 1364 ICC_RISD_Pixel189_OnOff "对应像素点的亮灭";
CM_ SG_ 1364 ICC_RISD_Pixel188_OnOff "对应像素点的亮灭";
CM_ SG_ 1364 ICC_RISD_Pixel187_OnOff "对应像素点的亮灭";
CM_ SG_ 1364 ICC_RISD_Pixel186_OnOff "对应像素点的亮灭";
CM_ SG_ 1364 ICC_RISD_Pixel185_OnOff "对应像素点的亮灭";
CM_ SG_ 1364 ICC_RISD_Pixel184_OnOff "对应像素点的亮灭";
CM_ SG_ 1364 ICC_RISD_Pixel183_OnOff "对应像素点的亮灭";
CM_ SG_ 1364 ICC_RISD_Pixel182_OnOff "对应像素点的亮灭";
CM_ SG_ 1364 ICC_RISD_Pixel181_OnOff "对应像素点的亮灭";
CM_ SG_ 1364 ICC_RISD_Pixel180_OnOff "对应像素点的亮灭";
CM_ SG_ 1364 ICC_RISD_Pixel179_OnOff "对应像素点的亮灭";
CM_ SG_ 1364 ICC_RISD_Pixel178_OnOff "对应像素点的亮灭";
CM_ SG_ 1364 ICC_RISD_Pixel177_OnOff "对应像素点的亮灭";
CM_ SG_ 1364 ICC_RISD_Pixel176_OnOff "对应像素点的亮灭";
CM_ SG_ 1364 ICC_RISD_Pixel175_OnOff "对应像素点的亮灭";
CM_ SG_ 1364 ICC_RISD_Pixel174_OnOff "对应像素点的亮灭";
CM_ SG_ 1364 ICC_RISD_Pixel173_OnOff "对应像素点的亮灭";
CM_ SG_ 1364 ICC_RISD_Pixel172_OnOff "对应像素点的亮灭";
CM_ SG_ 1364 ICC_RISD_Pixel171_OnOff "对应像素点的亮灭";
CM_ SG_ 1364 ICC_RISD_Pixel170_OnOff "对应像素点的亮灭";
CM_ SG_ 1364 ICC_RISD_Pixel169_OnOff "对应像素点的亮灭";
CM_ SG_ 1364 ICC_RISD_Pixel168_OnOff "对应像素点的亮灭";
CM_ SG_ 1364 ICC_RISD_Pixel167_OnOff "对应像素点的亮灭";
CM_ SG_ 1364 ICC_RISD_Pixel166_OnOff "对应像素点的亮灭";
CM_ SG_ 1364 ICC_RISD_Pixel165_OnOff "对应像素点的亮灭";
CM_ SG_ 1364 ICC_RISD_Pixel164_OnOff "对应像素点的亮灭";
CM_ SG_ 1364 ICC_RISD_Pixel163_OnOff "对应像素点的亮灭";
CM_ SG_ 1364 ICC_RISD_Pixel162_OnOff "对应像素点的亮灭";
CM_ SG_ 1364 ICC_RISD_Pixel161_OnOff "对应像素点的亮灭";
CM_ SG_ 1364 ICC_RISD_Pixel160_OnOff "对应像素点的亮灭";
CM_ SG_ 1364 ICC_RISD_Pixel159_OnOff "对应像素点的亮灭";
CM_ SG_ 1364 ICC_RISD_Pixel158_OnOff "对应像素点的亮灭";
CM_ SG_ 1364 ICC_RISD_Pixel157_OnOff "对应像素点的亮灭";
CM_ SG_ 1364 ICC_RISD_Pixel156_OnOff "对应像素点的亮灭";
CM_ SG_ 1364 ICC_RISD_Pixel155_OnOff "对应像素点的亮灭";
CM_ SG_ 1364 ICC_RISD_Pixel154_OnOff "对应像素点的亮灭";
CM_ SG_ 1364 ICC_RISD_Pixel153_OnOff "对应像素点的亮灭";
CM_ SG_ 1364 ICC_RISD_Pixel152_OnOff "对应像素点的亮灭";
CM_ SG_ 1364 ICC_RISD_Pixel151_OnOff "对应像素点的亮灭";
CM_ SG_ 1364 ICC_RISD_Pixel150_OnOff "对应像素点的亮灭";
CM_ SG_ 1364 ICC_RISD_Pixel149_OnOff "对应像素点的亮灭";
CM_ SG_ 1364 ICC_RISD_Pixel148_OnOff "对应像素点的亮灭";
CM_ SG_ 1364 ICC_RISD_Pixel147_OnOff "对应像素点的亮灭";
CM_ SG_ 1364 ICC_RISD_Pixel146_OnOff "对应像素点的亮灭";
CM_ SG_ 1364 ICC_RISD_Pixel145_OnOff "对应像素点的亮灭";
CM_ SG_ 1364 ICC_RISD_Pixel144_OnOff "对应像素点的亮灭";
CM_ SG_ 1364 ICC_RISD_Pixel143_OnOff "对应像素点的亮灭";
CM_ SG_ 1364 ICC_RISD_Pixel142_OnOff "对应像素点的亮灭";
CM_ SG_ 1364 ICC_RISD_Pixel141_OnOff "对应像素点的亮灭";
CM_ SG_ 1364 ICC_RISD_Pixel140_OnOff "对应像素点的亮灭";
CM_ SG_ 1364 ICC_RISD_Pixel139_OnOff "对应像素点的亮灭";
CM_ SG_ 1364 ICC_RISD_Pixel138_OnOff "对应像素点的亮灭";
CM_ SG_ 1364 ICC_RISD_Pixel137_OnOff "对应像素点的亮灭";
CM_ SG_ 1364 ICC_RISD_Pixel136_OnOff "对应像素点的亮灭";
CM_ SG_ 1364 ICC_RISD_Pixel135_OnOff "对应像素点的亮灭";
CM_ SG_ 1364 ICC_RISD_Pixel134_OnOff "对应像素点的亮灭";
CM_ SG_ 1364 ICC_RISD_Pixel133_OnOff "对应像素点的亮灭";
CM_ SG_ 1364 ICC_RISD_Pixel132_OnOff "对应像素点的亮灭";
CM_ SG_ 1364 ICC_RISD_Pixel131_OnOff "对应像素点的亮灭";
CM_ SG_ 1364 ICC_RISD_Pixel130_OnOff "对应像素点的亮灭";
CM_ SG_ 1364 ICC_RISD_Pixel129_OnOff "对应像素点的亮灭";
CM_ SG_ 1364 ICC_RISD_Pixel128_OnOff "对应像素点的亮灭";
CM_ SG_ 1364 ICC_RISD_Pixel127_OnOff "对应像素点的亮灭";
CM_ SG_ 1364 ICC_RISD_Pixel126_OnOff "对应像素点的亮灭";
CM_ SG_ 1364 ICC_RISD_Pixel125_OnOff "对应像素点的亮灭";
CM_ SG_ 1364 ICC_RISD_Pixel124_OnOff "对应像素点的亮灭";
CM_ SG_ 1364 ICC_RISD_Pixel123_OnOff "对应像素点的亮灭";
CM_ SG_ 1364 ICC_RISD_Pixel122_OnOff "对应像素点的亮灭";
CM_ SG_ 1364 ICC_RISD_Pixel121_OnOff "对应像素点的亮灭";
CM_ SG_ 1364 ICC_RISD_Pixel120_OnOff "对应像素点的亮灭";
CM_ SG_ 1364 ICC_RISD_Pixel119_OnOff "对应像素点的亮灭";
CM_ SG_ 1364 ICC_RISD_Pixel118_OnOff "对应像素点的亮灭";
CM_ SG_ 1364 ICC_RISD_Pixel117_OnOff "对应像素点的亮灭";
CM_ SG_ 1364 ICC_RISD_Pixel116_OnOff "对应像素点的亮灭";
CM_ SG_ 1364 ICC_RISD_Pixel115_OnOff "对应像素点的亮灭";
CM_ SG_ 1364 ICC_RISD_Pixel114_OnOff "对应像素点的亮灭";
CM_ SG_ 1364 ICC_RISD_Pixel113_OnOff "对应像素点的亮灭";
CM_ SG_ 1364 ICC_RISD_Pixel112_OnOff "对应像素点的亮灭";
CM_ SG_ 1364 ICC_RISD_Pixel111_OnOff "对应像素点的亮灭";
CM_ SG_ 1364 ICC_RISD_Pixel110_OnOff "对应像素点的亮灭";
CM_ SG_ 1364 ICC_RISD_Pixel109_OnOff "对应像素点的亮灭";
CM_ SG_ 1364 ICC_RISD_Pixel108_OnOff "对应像素点的亮灭";
CM_ SG_ 1364 ICC_RISD_Pixel107_OnOff "对应像素点的亮灭";
CM_ SG_ 1364 ICC_RISD_Pixel106_OnOff "对应像素点的亮灭";
CM_ SG_ 1364 ICC_RISD_Pixel105_OnOff "对应像素点的亮灭";
CM_ SG_ 1364 ICC_RISD_Pixel104_OnOff "对应像素点的亮灭";
CM_ SG_ 1364 ICC_RISD_Pixel103_OnOff "对应像素点的亮灭";
CM_ SG_ 1364 ICC_RISD_Pixel102_OnOff "对应像素点的亮灭";
CM_ SG_ 1364 ICC_RISD_Pixel101_OnOff "对应像素点的亮灭";
CM_ SG_ 1364 ICC_RISD_Pixel100_OnOff "对应像素点的亮灭";
CM_ SG_ 1364 ICC_RISD_Pixel99_OnOff "对应像素点的亮灭";
CM_ SG_ 1364 ICC_RISD_Pixel98_OnOff "对应像素点的亮灭";
CM_ SG_ 1364 ICC_RISD_Pixel97_OnOff "对应像素点的亮灭";
CM_ SG_ 1364 ICC_RISD_Pixel96_OnOff "对应像素点的亮灭";
CM_ SG_ 1364 ICC_RISD_Pixel95_OnOff "对应像素点的亮灭";
CM_ SG_ 1364 ICC_RISD_Pixel94_OnOff "对应像素点的亮灭";
CM_ SG_ 1364 ICC_RISD_Pixel93_OnOff "对应像素点的亮灭";
CM_ SG_ 1364 ICC_RISD_Pixel92_OnOff "对应像素点的亮灭";
CM_ SG_ 1364 ICC_RISD_Pixel91_OnOff "对应像素点的亮灭";
CM_ SG_ 1364 ICC_RISD_Pixel90_OnOff "对应像素点的亮灭";
CM_ SG_ 1364 ICC_RISD_Pixel89_OnOff "对应像素点的亮灭";
CM_ SG_ 1364 ICC_RISD_Pixel88_OnOff "对应像素点的亮灭";
CM_ SG_ 1364 ICC_RISD_Pixel87_OnOff "对应像素点的亮灭";
CM_ SG_ 1364 ICC_RISD_Pixel86_OnOff "对应像素点的亮灭";
CM_ SG_ 1364 ICC_RISD_Pixel85_OnOff "对应像素点的亮灭";
CM_ SG_ 1364 ICC_RISD_Pixel84_OnOff "对应像素点的亮灭";
CM_ SG_ 1364 ICC_RISD_Pixel83_OnOff "对应像素点的亮灭";
CM_ SG_ 1364 ICC_RISD_Pixel82_OnOff "对应像素点的亮灭";
CM_ SG_ 1364 ICC_RISD_Pixel81_OnOff "对应像素点的亮灭";
CM_ SG_ 1364 ICC_RISD_Pixel80_OnOff "对应像素点的亮灭";
CM_ SG_ 1364 ICC_RISD_Pixel79_OnOff "对应像素点的亮灭";
CM_ SG_ 1364 ICC_RISD_Pixel78_OnOff "对应像素点的亮灭";
CM_ SG_ 1364 ICC_RISD_Pixel77_OnOff "对应像素点的亮灭";
CM_ SG_ 1364 ICC_RISD_Pixel76_OnOff "对应像素点的亮灭";
CM_ SG_ 1364 ICC_RISD_Pixel75_OnOff "对应像素点的亮灭";
CM_ SG_ 1364 ICC_RISD_Pixel74_OnOff "对应像素点的亮灭";
CM_ SG_ 1364 ICC_RISD_Pixel73_OnOff "对应像素点的亮灭";
CM_ SG_ 1364 ICC_RISD_Pixel72_OnOff "对应像素点的亮灭";
CM_ SG_ 1364 ICC_RISD_Pixel71_OnOff "对应像素点的亮灭";
CM_ SG_ 1364 ICC_RISD_Pixel70_OnOff "对应像素点的亮灭";
CM_ SG_ 1364 ICC_RISD_Pixel69_OnOff "对应像素点的亮灭";
CM_ SG_ 1364 ICC_RISD_Pixel68_OnOff "对应像素点的亮灭";
CM_ SG_ 1364 ICC_RISD_Pixel67_OnOff "对应像素点的亮灭";
CM_ SG_ 1364 ICC_RISD_Pixel66_OnOff "对应像素点的亮灭";
CM_ SG_ 1364 ICC_RISD_Pixel65_OnOff "对应像素点的亮灭";
CM_ SG_ 1364 ICC_RISD_Pixel64_OnOff "对应像素点的亮灭";
CM_ SG_ 1364 ICC_RISD_Pixel63_OnOff "对应像素点的亮灭";
CM_ SG_ 1364 ICC_RISD_Pixel62_OnOff "对应像素点的亮灭";
CM_ SG_ 1364 ICC_RISD_Pixel61_OnOff "对应像素点的亮灭";
CM_ SG_ 1364 ICC_RISD_Pixel60_OnOff "对应像素点的亮灭";
CM_ SG_ 1364 ICC_RISD_Pixel59_OnOff "对应像素点的亮灭";
CM_ SG_ 1364 ICC_RISD_Pixel58_OnOff "对应像素点的亮灭";
CM_ SG_ 1364 ICC_RISD_Pixel57_OnOff "对应像素点的亮灭";
CM_ SG_ 1364 ICC_RISD_Pixel56_OnOff "对应像素点的亮灭";
CM_ SG_ 1364 ICC_RISD_Pixel55_OnOff "对应像素点的亮灭";
CM_ SG_ 1364 ICC_RISD_Pixel54_OnOff "对应像素点的亮灭";
CM_ SG_ 1364 ICC_RISD_Pixel53_OnOff "对应像素点的亮灭";
CM_ SG_ 1364 ICC_RISD_Pixel52_OnOff "对应像素点的亮灭";
CM_ SG_ 1364 ICC_RISD_Pixel51_OnOff "对应像素点的亮灭";
CM_ SG_ 1364 ICC_RISD_Pixel50_OnOff "对应像素点的亮灭";
CM_ SG_ 1364 ICC_RISD_Pixel49_OnOff "对应像素点的亮灭";
CM_ SG_ 1364 ICC_RISD_Pixel48_OnOff "对应像素点的亮灭";
CM_ SG_ 1364 ICC_RISD_Pixel47_OnOff "对应像素点的亮灭";
CM_ SG_ 1364 ICC_RISD_Pixel46_OnOff "对应像素点的亮灭";
CM_ SG_ 1364 ICC_RISD_Pixel45_OnOff "对应像素点的亮灭";
CM_ SG_ 1364 ICC_RISD_Pixel44_OnOff "对应像素点的亮灭";
CM_ SG_ 1364 ICC_RISD_Pixel43_OnOff "对应像素点的亮灭";
CM_ SG_ 1364 ICC_RISD_Pixel42_OnOff "对应像素点的亮灭";
CM_ SG_ 1364 ICC_RISD_Pixel41_OnOff "对应像素点的亮灭";
CM_ SG_ 1364 ICC_RISD_Pixel40_OnOff "对应像素点的亮灭";
CM_ SG_ 1364 ICC_RISD_Pixel39_OnOff "对应像素点的亮灭";
CM_ SG_ 1364 ICC_RISD_Pixel38_OnOff "对应像素点的亮灭";
CM_ SG_ 1364 ICC_RISD_Pixel37_OnOff "对应像素点的亮灭";
CM_ SG_ 1364 ICC_RISD_Pixel36_OnOff "对应像素点的亮灭";
CM_ SG_ 1364 ICC_RISD_Pixel35_OnOff "对应像素点的亮灭";
CM_ SG_ 1364 ICC_RISD_Pixel34_OnOff "对应像素点的亮灭";
CM_ SG_ 1364 ICC_RISD_Pixel33_OnOff "对应像素点的亮灭";
CM_ SG_ 1364 ICC_RISD_Pixel32_OnOff "对应像素点的亮灭";
CM_ SG_ 1364 ICC_RISD_Pixel31_OnOff "对应像素点的亮灭";
CM_ SG_ 1364 ICC_RISD_Pixel30_OnOff "对应像素点的亮灭";
CM_ SG_ 1364 ICC_RISD_Pixel29_OnOff "对应像素点的亮灭";
CM_ SG_ 1364 ICC_RISD_Pixel28_OnOff "对应像素点的亮灭";
CM_ SG_ 1364 ICC_RISD_Pixel27_OnOff "对应像素点的亮灭";
CM_ SG_ 1364 ICC_RISD_Pixel26_OnOff "对应像素点的亮灭";
CM_ SG_ 1364 ICC_RISD_Pixel25_OnOff "对应像素点的亮灭";
CM_ SG_ 1364 ICC_RISD_Pixel24_OnOff "对应像素点的亮灭";
CM_ SG_ 1364 ICC_RISD_Pixel23_OnOff "对应像素点的亮灭";
CM_ SG_ 1364 ICC_RISD_Pixel22_OnOff "对应像素点的亮灭";
CM_ SG_ 1364 ICC_RISD_Pixel21_OnOff "对应像素点的亮灭";
CM_ SG_ 1364 ICC_RISD_Pixel20_OnOff "对应像素点的亮灭";
CM_ SG_ 1364 ICC_RISD_Pixel19_OnOff "对应像素点的亮灭";
CM_ SG_ 1364 ICC_RISD_Pixel18_OnOff "对应像素点的亮灭";
CM_ SG_ 1364 ICC_RISD_Pixel17_OnOff "对应像素点的亮灭";
CM_ SG_ 1364 ICC_RISD_Pixel16_OnOff "对应像素点的亮灭";
CM_ SG_ 1364 ICC_RISD_Pixel15_OnOff "对应像素点的亮灭";
CM_ SG_ 1364 ICC_RISD_Pixel14_OnOff "对应像素点的亮灭";
CM_ SG_ 1364 ICC_RISD_Pixel13_OnOff "对应像素点的亮灭";
CM_ SG_ 1364 ICC_RISD_Pixel12_OnOff "对应像素点的亮灭";
CM_ SG_ 1364 ICC_RISD_Pixel11_OnOff "对应像素点的亮灭";
CM_ SG_ 1364 ICC_RISD_Pixel10_OnOff "对应像素点的亮灭";
CM_ SG_ 1364 ICC_RISD_Pixel9_OnOff "对应像素点的亮灭";
CM_ SG_ 1364 ICC_RISD_Pixel8_OnOff "对应像素点的亮灭";
CM_ SG_ 1364 ICC_RISD_Pixel7_OnOff "对应像素点的亮灭";
CM_ SG_ 1364 ICC_RISD_Pixel6_OnOff "对应像素点的亮灭";
CM_ SG_ 1364 ICC_RISD_Pixel5_OnOff "对应像素点的亮灭";
CM_ SG_ 1364 ICC_RISD_Pixel4_OnOff "对应像素点的亮灭";
CM_ SG_ 1364 ICC_RISD_Pixel3_OnOff "对应像素点的亮灭";
CM_ SG_ 1364 ICC_RISD_Pixel2_OnOff "对应像素点的亮灭";
CM_ SG_ 1364 ICC_RISD_Pixel1_OnOff "对应像素点的亮灭";
CM_ SG_ 1364 ICC_RISD_RollingCounter "顺序计数器，确保图片数据按预期顺序发送、接收。";
CM_ SG_ 1345 DVR_1_DVRFailReasons "DVR失效原因";
CM_ SG_ 1345 DVR_1_RecordSts "DVR普通录像状态";
CM_ SG_ 1121 STAT_AMPNaviVolume "Amplifier navigation volume status
反馈-导航音量设定";
CM_ SG_ 1121 STAT_AMPVRVolume "Amplifier voice recognize volume status
反馈语音音量设定";
CM_ SG_ 1121 STAT_AMPKeyTone "Amplifier key tone status
反馈按键音开关";
CM_ SG_ 1121 STAT_AMPMediaVolume "Amplifier media volume status
反馈媒体音量设定";
CM_ SG_ 1121 STAT_AMPPhoneVolume "Amplifier phone volume status
反馈电话音量设定";
CM_ SG_ 1121 STAT_AMPSoundFocus "Amplifier sound focus status
反馈音场（最佳听音位）设定";
CM_ SG_ 1121 STAT_AMPSoundEffect "Amplifier sound effect status
反馈-音效设定（预设EQ）";
CM_ SG_ 1121 STAT_AMPSoundEffectBass "Amplifier sound effect bass status
反馈-低音设定（用户自定义EQ下）";
CM_ SG_ 1121 STAT_AMPSoundEffectMidrange "Amplifier sound effect midrange status
反馈-中音设定（用户自定义EQ下）";
CM_ SG_ 1121 STAT_AMPSoundEffectTreble "Amplifier sound effect treble status
反馈-高音设定（用户自定义EQ下）";
CM_ SG_ 1121 STAT_AMPSoundFieldBalance "Amplifier sound field balance status
反馈-Balance设定（用户自定义声场)";
CM_ SG_ 1121 STAT_AMPSoundFieldFader "Amplifier sound field fader status
反馈-反馈-Fader设定（用户自定义声场）";
CM_ SG_ 1121 STAT_REQ_AMPA2BMediaSound "Status of Head unit media sound request to amplifier
媒体音源需求状态";
CM_ SG_ 1121 STAT_REQ_AMPA2BNaviSound "Status of Head unit navigation sound request to amplifier
导航音源需求状态";
CM_ SG_ 1121 STAT_REQ_AMPA2BVRSound "Status of Head unit VR sound request to amplifier
VR/Siri音源需求状态";
CM_ SG_ 1121 STAT_REQ_AMPA2BTTSSound "Status of Head unit TTS sound request to amplifier
TTS音源需求状态";
CM_ SG_ 1121 STAT_REQ_AMPA2BPhoneSound "Status of Head unit BT Phone and Tbox sound request to amplifier
电话/Tbox音源需求状态";
CM_ SG_ 1121 STAT_REQ_AMPAlarm "Status of Instrument panel cluster alarm status to amplifier for chime play
警报音需求状态";
CM_ SG_ 1140 STAT_AMPMediaDuck "Media Duck request to amplifier/发送媒体降音反馈给主机";
CM_ SG_ 1140 STAT_AMPSpeedVolume "Amplifier vehicle speed volume compensation status
反馈-随速补偿等级设定";
CM_ SG_ 1140 STAT_AMPMute "Amplifier audio mute or not status
反馈-媒体音量开关";
CM_ SG_ 1140 STAT_AMPRestoreDefaults "Amplifier audio restore defaults status/恢复默认音频参数设置状态";
CM_ SG_ 1140 STAT_AMPAlarmVolume "Amplifier instrument panel cluster alarm volume status/警报音量值状态";
CM_ SG_ 1140 STAT_Headrest_Mode "Headrest mode status/头枕模式状态";
CM_ SG_ 1140 STAT_AMPSoundEffectMegaBass "Amplifier sound effect megabass feedback/重低音设定值反馈";
CM_ SG_ 1140 STAT_AMPSoundEffectMidBass "Amplifier sound effect midbass feedback/中低音设定值反馈";
CM_ SG_ 1140 STAT_AMPSoundEffectMidTreble "Amplifier sound effect midtreble feedback/中高音设定值反馈";
CM_ SG_ 1140 STAT_VirtualSbwfrOnOff "Amplifier sound effect midtreble feedback/虚拟现场设定状态";
CM_ SG_ 1140 STAT_SurndFnOnOff "Surround_On_Off_Request feedback/3D环绕设定状态";
CM_ SG_ 1140 STAT_AMPBackgroundVolume "Amplifier background media volume status/背景音（迎宾音）音量值状态";
CM_ SG_ 1140 STAT_AMPSoundBypass "Amplifier sound bypass status/第三方APP打开时，外置功放做音效bypass处理状态";
CM_ SG_ 1140 STAT_AMPPwrRdySts "Amplifier Power Ready Status with A2B/A2B交互成功并支持出声后，反馈Ready";
CM_ SG_ 1206 EAMP_AMPKTVvoiceVolumeFed "Feedback Amplifier KTV voice volume status
反馈KTV人声音量设定";
CM_ SG_ 1206 EAMP_AMPENCVolumeFed "Feedback Amplifier ENC volume status
反馈ENC音量设定";
CM_ SG_ 1206 EAMP_AMPA2BKTVvoiceSoundFed "Feedback Status of Head unit KTV voice/IESS sound request to amplifier
反馈KTV人声/模拟声浪音源需求状态";
CM_ SG_ 1206 STAT_AMPSoundFocus_2 "Amplifier sound focus status反馈音场（最佳听音位）设定";
CM_ SG_ 1206 EAMP_AMPA2BENCSoundFed "Feedback Status of Head unit ENC sound request to amplifier
反馈ENC音源需求状态";
CM_ SG_ 1206 EAMP_AMPA2BChimeSoundFed "Feedback Status of Head unit Chime sound request to amplifier
反馈Chime音源需求状态";
CM_ SG_ 1206 STAT_AMPLoudness "Amplifier Loudness feedback/响度设定值反馈";
CM_ SG_ 1206 STAT_AMPKeyVolume "Amplifier Keytone volume status/反馈按键音通道音量设定";
CM_ SG_ 1206 STAT_AMPExSoundmode "Amplifier Exsound mode/高级音效模式";
CM_ SG_ 1206 STAT_AMPA2BENCSound "扬声器位置反馈";
CM_ SG_ 1078 PLG_LatchSts "尾门门锁状态";
CM_ SG_ 1252 TotalOdometer_km_OBD "GB18285-2018新增OBD输出检查要求车辆累积行驶里程信号。";
CM_ SG_ 1252 DisplayVehicleSpeed "仪表显示的车速，比实际车速略大。";
CM_ SG_ 1252 ICC_TotalodometerbackupEnable "里程备份使能";
CM_ SG_ 1322 STAT_AMPAlarm "Instrument panel cluster alarm status to amplifier for chime play";
CM_ SG_ 1176 ICC_CH_3_CRC "Profile1A:E2E CRC (SAE J1850 CRC-8) for 8 Bytes
DataID:0x0048";
CM_ SG_ 1176 ICC_CH_3_RollgCntr "Profile1A:E2E Rolling message counter(the maximum value of Alive counter is 14)";
CM_ SG_ 1176 ICC_ASUAssistPassSet "Suspension assist in passing setting
悬架辅助通过设置";
CM_ SG_ 1176 IHU_AutHldSet "automatic hold set";
CM_ SG_ 1176 ICC_PABSetCmd "PAB Set Command";
CM_ SG_ 1176 ICC_EPBSetCmd "EPB Set Command";
CM_ SG_ 1176 ICC_ASUMemoryPosition "是否记忆当前悬架高度调节位置";
CM_ SG_ 1176 ICC_ASUEasyLoadingSet "ASU Easy Loading Setting
悬架手动便利装载设置";
CM_ SG_ 1176 Set_CSTFunctionSts "CST:Comfortable stop
To switch on or off CST function.";
CM_ SG_ 1176 ICC_ASURearaxlewithTaildoor "后轴高度与尾门开合关联";
CM_ SG_ 1176 TIHU_SetHDCOnOff "通过DVD设置HDC功能开关";
CM_ SG_ 1176 ICC_ASUPreviewCont "预瞄功能";
CM_ SG_ 1176 ICC_ASUHighwayModAdjust "高速路悬架高度自动调节";
CM_ SG_ 1176 ICC_ASUMapAdjust "悬架基于地图高度调节";
CM_ SG_ 1239 ICC_DisChg "Discharge switch";
CM_ SG_ 1239 ICC_StpDisChgReq "Stop discharge set";
CM_ SG_ 1239 ICC_RegenLevel "recovery level set";
CM_ SG_ 1239 ICC_ELockReq "解锁充放电枪电子锁";
CM_ SG_ 1239 ICC_DisChgPercent "discharge limit set SOC(ICC确认发送)";
CM_ SG_ 1239 ICC_ChgSocSet "Charge target SOC(ICC确认发送)";
CM_ SG_ 1239 ICC_CampMode "露营模式开启/关闭";
CM_ SG_ 1239 ICC_SftWarning "打开/关闭N档防误触提醒";
CM_ SG_ 1239 ICC_TowingMode "打开/关闭拖车模式服务";
CM_ SG_ 1239 ICC_StopMode "停车模式开关";
CM_ SG_ 1239 ICC_EPedalMode "E-Pedal模式开关";
CM_ SG_ 1246 ICC_WindowKeySts "Window Key Status
吹窗按键开关";
CM_ SG_ 1246 ICC_FaceKeySts "Face Key Status
吹面按键开关";
CM_ SG_ 1246 ICC_FootKeySts "Foot Key Status
吹脚按键开关";
CM_ SG_ 1246 BltCallSts "Whether the bluetooth call is turned on
蓝牙通话状态";
CM_ SG_ 1246 ICC_DockWinspSts "Constant display Blower Level
Set it once, first send the setting value three times and then send Not Active three times.";
CM_ SG_ 1246 ICC_DockTSts "Constant display SetTemp
Set it once, first send the setting value three times and then send Not Active three times.";
CM_ SG_ 1246 ICC_ACFastCool "AC Fast Cooling Working Status Set
空调极速降温工作状态设置";
CM_ SG_ 1246 ICC_ACFastHeat "AC Fast Heating Working Status Set
空调快速升温工作状态设置";
CM_ SG_ 1246 ICC_SetCLMOn "Set CLM On 
DVD设置空调开启";
CM_ SG_ 1246 ICC_SetAutoKeySts "Set Auto Status
DVD设置开启空调自动模式";
CM_ SG_ 1246 ICC_SetFrontDeforestSts "Set Front Deforest Status
DVD设置最大前除霜开启";
CM_ SG_ 1246 ICC_SetCirculationModeKeySts "Set Circulation Mode Key Status
DVD设置内外循环切换";
CM_ SG_ 1246 ICC_ZoneSelectionKeySts "Zone Selection Key Status
DVD设置单双区模式切换";
CM_ SG_ 1246 ICC_ResetFilter "Reset Filter Status
滤芯重置";
CM_ SG_ 1246 ICC_AUTODefrostOnKeySts "AUTO Defrost On Key Status
上报自动除雾设置项状态";
CM_ SG_ 1246 ICC_AutoAirClean "Auto Air Clean Set
上报座舱自动清洁设置项状态";
CM_ SG_ 1246 ICC_KeepWarm "Keep Warm Working Status Set
恒温模式工作状态设置";
CM_ SG_ 1246 ICC_BlowSpeedLevelKeySts "Blower Speed Level Key Status
鼓风机档位设置
在IHU上直接设置也通过此信号实现
电动IPM收，自动IPM不收";
CM_ SG_ 1246 ICC_SetACRequestKeySts "Set AC Request Status
DVD设置AC请求开启";
CM_ SG_ 1246 ICC_DSwingSet "Driver Air Swing Mode
主驾扫风模式设置";
CM_ SG_ 1246 ICC_PSwingSet "Passenge rAir Swing Mode
副驾扫风模式设置";
CM_ SG_ 1246 ICC_AUTODefLevelSet "AUTO Deforest Level Set
自动除雾等级信息";
CM_ SG_ 1246 ICC_SetTemperature_L_C "在单区模式下，调节左旋钮可以同时设定左右两边的温度设定。在双区模式下，左旋钮设定左区温度，右旋钮设定右区温度。
IHU未收到设定温值时，以及收到设定温值为startup 或default对应的1F时，IHU屏幕上温度显示区域均显示空白。
在IHU上直接设置也通过此信号实现 
电动空调配置时此信号预留不发
温度范围15.5-30.5℃
温度调节每次0.5℃
参数改变";
CM_ SG_ 1246 ICC_SetTemperature_R_C "在单区模式下，调节左旋钮可以同时设定左右两边的温度设定。在双区模式下，左旋钮设定左区温度，右旋钮设定右区温度。
IHU未收到设定温值时，以及收到设定温值为startup 或default对应的1F时，IHU屏幕上温度显示区域均显示空白。
在IHU上直接设置也通过此信号实现 
电动空调配置时此信号预留不发
温度范围15.5-30.5℃
温度调节每次0.5℃
参数改变";
CM_ SG_ 1246 ICC_DLSwingUpDwn "Driver Left Swing Up_Down Working Position Set
设置主驾左上下扫风电机工作位置";
CM_ SG_ 1246 ICC_DLSwingLeRi "Driver Left Swing Left_Right Working Position Set
设置主驾左左右扫风电机工作位置";
CM_ SG_ 1246 ICC_DRSwingUpDwn "Driver Right Swing Up_Down Working Position Set
设置主驾右上下扫风电机工作位置";
CM_ SG_ 1246 ICC_DRSwingLeRi "Driver Right Swing Left_Right Working Position Set
设置主驾右左右扫风电机工作位置";
CM_ SG_ 1246 ICC_PLSwingUpDwn "Passenger Left Swing Up_Down Working Position Set
设置副驾左上下扫风电机工作位置";
CM_ SG_ 1246 ICC_PLSwingLeRi "Passenger Left Swing Left_Right Working Position Set
设置副驾左左右扫风电机工作位置";
CM_ SG_ 1246 ICC_PRSwingUpDwn "Passenger Right Swing Up_Down Working Position Set
设置副驾右上下扫风电机工作位置";
CM_ SG_ 1246 ICC_PRSwingLeRi "Passenger Right Swing Left_Right Working Position Set
设置副驾右左右扫风电机工作位置";
CM_ SG_ 1246 ICC_DCSwingLeRi "Driver Center Swing Left_Right Working Position Set
设置主驾中上左右扫风电机工作位置";
CM_ SG_ 1246 ICC_NetWorkTemperature "Net Work Temperature
上报网络上温度";
CM_ SG_ 1246 ICC_NetWorkHumidity "Net Work Humidity
上报网络上湿度";
CM_ SG_ 1246 ICC_DLOnOff "Driver Left On_Off Status Set
主驾左出风口开关状态设置";
CM_ SG_ 1246 ICC_DROnOff "Driver Right On_Off Status Set
主驾右出风口开关状态设置";
CM_ SG_ 1246 ICC_PLOnOff "Passenger Left On_Off Status Set
副驾左出风口开关状态设置";
CM_ SG_ 1246 ICC_PROnOff "Passenger Right On_Off Status Set
副驾右出风口开关状态设置";
CM_ SG_ 1246 ICC_DCOnOff "Driver Center On_Off Status Set
中上出风口开关状态设置";
CM_ SG_ 1246 ICC_LoveRemind "Love Remind Working Status Set
爱心提醒工作状态设置";
CM_ SG_ 1246 ICC_InteCleanCar "Intelligent Clean Car Working Status Set
智能除味工作状态设置";
CM_ SG_ 1246 ICC_KeepWarmMemory "ICC恒温模式开关设定记忆状态
0x1:MemoryON(本次操作记忆)
0x2:Memory OFF(本次操作不记忆)";
CM_ SG_ 1250 ICC_AutoLightSW "AUTO灯开关，拨到该位置（打开）发1，不拨到该位置（关闭）发0，默认发0";
CM_ SG_ 1250 ICC_CleanMode "洗车模式";
CM_ SG_ 1250 ICC_1_OTASts "OTA status（拆帧为40B）";
CM_ SG_ 1250 ICC_1_OTAHV_Req "OTA high voltage power down request";
CM_ SG_ 1250 ICC_1_OTAPwrMngt "Power Management";
CM_ SG_ 1250 ICC_DriveModeSwitch "驾驶模式设置";
CM_ SG_ 1250 ICC_PropulsionMode "个性化-动力模式设置";
CM_ SG_ 1250 ICC_SteeringMode "个性化-转向模式设置";
CM_ SG_ 1250 ICC_SuspensionHeight "个性化-悬架高度设置";
CM_ SG_ 1250 ICC_SuspensionDamping "个性化-悬架阻尼设置";
CM_ SG_ 1250 ICC_AirconditionMode "个性化-空调模式设置";
CM_ SG_ 1250 ICC_BrakePedalFeelMode "个性化-制动踏板感觉设置
0x3:越野模式";
CM_ SG_ 1250 ICC_SentinelHV_Req "哨兵模式高压请求";
CM_ SG_ 1250 ICC_PetModeHV_Req "宠物模式高压请求";
CM_ SG_ 1250 ICC_SelfClearing "能耗分布自清零指令";
BA_DEF_  "DBName" STRING ;
BA_DEF_  "BusType" STRING ;
BA_DEF_  "NmMessageCount" INT 0 255;
BA_DEF_  "NmBaseAddress" HEX 1536 1663;
BA_DEF_ BO_  "GenMsgCycleTimeFast" INT 0 50000;
BA_DEF_ BO_  "GenMsgNrOfRepetition" INT 0 999999;
BA_DEF_ BO_  "GenMsgDelayTime" INT 0 1000;
BA_DEF_ BO_  "VFrameFormat" ENUM  "StandardCAN","ExtendedCAN","reserved","reserved","reserved","reserved","reserved","reserved","reserved","reserved","reserved","reserved","reserved","reserved","StandardCAN_FD","ExtendedCAN_FD";
BA_DEF_ BO_  "GenMsgILSupport" ENUM  "No","Yes";
BA_DEF_ BO_  "NmMessage" ENUM  "No","Yes";
BA_DEF_ BO_  "GenMsgSendType" ENUM  "Cycle","Event","IfActive","CE","CA","NoMsgSendType";
BA_DEF_ BO_  "GenMsgCycleTime" INT 0 50000;
BA_DEF_ BO_  "CANFD_BRS" INT 0 1;
BA_DEF_ BO_  "NmAsrMessage" ENUM  "No","Yes";
BA_DEF_ BO_  "GRC_ASIL" ENUM  "vector_leerstring","QM","A","B","C","D";
BA_DEF_ BO_  "GRC_History" STRING ;
BA_DEF_ SG_  "GenSigStartValue" FLOAT 0 100000000000;
BA_DEF_ SG_  "GenSigInactiveValue" INT 0 100000;
BA_DEF_ SG_  "GenSigInvalidValue" INT 0 100000000;
BA_DEF_ SG_  "GenSigSendType" ENUM  "Cycle","OnChange","OnWrite","IfActive","OnChangeWithRepetition","OnWriteWithRepetition","IfActiveWithRepetition","NoSigSendType","OnChangeAndIfActive","OnChangeAndIfActiveWithRepetition","CA","CE","Event";
BA_DEF_ SG_  "GRC_Sig_ASIL" ENUM  "vector_leerstring","QM","A","B","C","D";
BA_DEF_ SG_  "E2EDataId" INT 0 0;
BA_DEF_ SG_  "E2EProfile" STRING ;
BA_DEF_ SG_  "E2EDataLength" INT 0 512;
BA_DEF_DEF_  "DBName" "";
BA_DEF_DEF_  "BusType" "CAN FD";
BA_DEF_DEF_  "NmMessageCount" 128;
BA_DEF_DEF_  "NmBaseAddress" 1536;
BA_DEF_DEF_  "GenMsgCycleTimeFast" 0;
BA_DEF_DEF_  "GenMsgNrOfRepetition" 0;
BA_DEF_DEF_  "GenMsgDelayTime" 0;
BA_DEF_DEF_  "VFrameFormat" "StandardCAN";
BA_DEF_DEF_  "GenMsgILSupport" "No";
BA_DEF_DEF_  "NmMessage" "No";
BA_DEF_DEF_  "GenMsgSendType" "NoMsgSendType";
BA_DEF_DEF_  "GenMsgCycleTime" 0;
BA_DEF_DEF_  "CANFD_BRS" 0;
BA_DEF_DEF_  "NmAsrMessage" "No";
BA_DEF_DEF_  "GRC_ASIL" "";
BA_DEF_DEF_  "GRC_History" "";
BA_DEF_DEF_  "GenSigStartValue" 0;
BA_DEF_DEF_  "GenSigInactiveValue" 0;
BA_DEF_DEF_  "GenSigInvalidValue" 0;
BA_DEF_DEF_  "GenSigSendType" "NoSigSendType";
BA_DEF_DEF_  "GRC_Sig_ASIL" "";
BA_DEF_DEF_  "E2EDataId" 0;
BA_DEF_DEF_  "E2EProfile" "";
BA_DEF_DEF_  "E2EDataLength" 0;
BA_ "DBName" "T1JFL2PHEVMessageListICCANFDEEA5";
BA_ "GenMsgILSupport" BO_ 771 1;
BA_ "GenMsgSendType" BO_ 771 0;
BA_ "GenMsgCycleTime" BO_ 771 50;
BA_ "CANFD_BRS" BO_ 771 1;
BA_ "VFrameFormat" BO_ 771 14;
BA_ "CANFD_BRS" BO_ 1127 1;
BA_ "GenMsgCycleTime" BO_ 1127 100;
BA_ "GenMsgSendType" BO_ 1127 0;
BA_ "GenMsgILSupport" BO_ 1127 1;
BA_ "VFrameFormat" BO_ 1127 14;
BA_ "CANFD_BRS" BO_ 1035 1;
BA_ "GenMsgCycleTime" BO_ 1035 100;
BA_ "GenMsgSendType" BO_ 1035 0;
BA_ "GenMsgILSupport" BO_ 1035 1;
BA_ "CANFD_BRS" BO_ 1364 1;
BA_ "GenMsgSendType" BO_ 1364 1;
BA_ "GenMsgILSupport" BO_ 1364 1;
BA_ "GenMsgDelayTime" BO_ 1364 5;
BA_ "GenMsgCycleTimeFast" BO_ 1364 100;
BA_ "VFrameFormat" BO_ 1364 14;
BA_ "CANFD_BRS" BO_ 1345 1;
BA_ "GenMsgSendType" BO_ 1345 3;
BA_ "GenMsgCycleTime" BO_ 1345 100;
BA_ "GenMsgCycleTimeFast" BO_ 1345 50;
BA_ "GenMsgNrOfRepetition" BO_ 1345 3;
BA_ "GenMsgDelayTime" BO_ 1345 5;
BA_ "GenMsgILSupport" BO_ 1345 1;
BA_ "VFrameFormat" BO_ 1345 14;
BA_ "CANFD_BRS" BO_ 1121 1;
BA_ "GenMsgSendType" BO_ 1121 0;
BA_ "GenMsgCycleTime" BO_ 1121 100;
BA_ "GenMsgILSupport" BO_ 1121 1;
BA_ "VFrameFormat" BO_ 1121 14;
BA_ "CANFD_BRS" BO_ 1140 1;
BA_ "GenMsgSendType" BO_ 1140 0;
BA_ "GenMsgCycleTime" BO_ 1140 100;
BA_ "GenMsgILSupport" BO_ 1140 1;
BA_ "VFrameFormat" BO_ 1140 14;
BA_ "CANFD_BRS" BO_ 1206 1;
BA_ "GenMsgSendType" BO_ 1206 0;
BA_ "GenMsgCycleTime" BO_ 1206 100;
BA_ "GenMsgILSupport" BO_ 1206 1;
BA_ "GRC_History" BO_ 1206 "[{'approvedBy':'贾少辉','author':'吴慧','changesComments':'姜新EAMP新增发送STAT_AMPLoudness和STAT_AMPKeyVolume和STAT_AMPExSoundmode和STAT_AMPA2BENCSound信号，ICC接收','date':'2025/4/15','ecu':'EAMP_3(0x4B6)','ecuName':'ICC,EAMP','reviewedBy':'杨华','revi";
BA_ "VFrameFormat" BO_ 1206 14;
BA_ "CANFD_BRS" BO_ 1078 1;
BA_ "GenMsgSendType" BO_ 1078 0;
BA_ "GenMsgCycleTime" BO_ 1078 100;
BA_ "GenMsgILSupport" BO_ 1078 1;
BA_ "VFrameFormat" BO_ 1078 14;
BA_ "CANFD_BRS" BO_ 1252 1;
BA_ "GenMsgSendType" BO_ 1252 0;
BA_ "GenMsgCycleTime" BO_ 1252 100;
BA_ "GenMsgILSupport" BO_ 1252 1;
BA_ "VFrameFormat" BO_ 1252 14;
BA_ "CANFD_BRS" BO_ 1322 1;
BA_ "GenMsgSendType" BO_ 1322 1;
BA_ "GenMsgCycleTimeFast" BO_ 1322 100;
BA_ "GenMsgNrOfRepetition" BO_ 1322 2;
BA_ "GenMsgDelayTime" BO_ 1322 5;
BA_ "GenMsgILSupport" BO_ 1322 1;
BA_ "VFrameFormat" BO_ 1322 14;
BA_ "CANFD_BRS" BO_ 1176 1;
BA_ "GenMsgSendType" BO_ 1176 3;
BA_ "GenMsgCycleTime" BO_ 1176 100;
BA_ "GenMsgCycleTimeFast" BO_ 1176 20;
BA_ "GenMsgNrOfRepetition" BO_ 1176 2;
BA_ "GenMsgDelayTime" BO_ 1176 5;
BA_ "GenMsgILSupport" BO_ 1176 1;
BA_ "VFrameFormat" BO_ 1176 14;
BA_ "CANFD_BRS" BO_ 1239 1;
BA_ "GenMsgSendType" BO_ 1239 3;
BA_ "GenMsgCycleTime" BO_ 1239 100;
BA_ "GenMsgCycleTimeFast" BO_ 1239 50;
BA_ "GenMsgNrOfRepetition" BO_ 1239 2;
BA_ "GenMsgDelayTime" BO_ 1239 5;
BA_ "GenMsgILSupport" BO_ 1239 1;
BA_ "VFrameFormat" BO_ 1239 14;
BA_ "CANFD_BRS" BO_ 1246 1;
BA_ "GenMsgSendType" BO_ 1246 3;
BA_ "GenMsgCycleTime" BO_ 1246 100;
BA_ "GenMsgCycleTimeFast" BO_ 1246 50;
BA_ "GenMsgNrOfRepetition" BO_ 1246 2;
BA_ "GenMsgDelayTime" BO_ 1246 5;
BA_ "GenMsgILSupport" BO_ 1246 1;
BA_ "VFrameFormat" BO_ 1246 14;
BA_ "CANFD_BRS" BO_ 1250 1;
BA_ "GenMsgSendType" BO_ 1250 3;
BA_ "GenMsgCycleTime" BO_ 1250 100;
BA_ "GenMsgCycleTimeFast" BO_ 1250 50;
BA_ "GenMsgNrOfRepetition" BO_ 1250 2;
BA_ "GenMsgDelayTime" BO_ 1250 5;
BA_ "GenMsgILSupport" BO_ 1250 1;
BA_ "VFrameFormat" BO_ 1250 14;
BA_ "GenSigSendType" SG_ 771 TimeGapAdjustment_33Dh 0;
BA_ "GenSigSendType" SG_ 1127 DCDC_FaultLevelSts 0;
BA_ "GenSigSendType" SG_ 1035 VCC_1_OTASts 0;
BA_ "GenSigSendType" SG_ 1364 ICC_RISD_Pixel504_OnOff 5;
BA_ "GenSigSendType" SG_ 1364 ICC_RISD_Pixel503_OnOff 5;
BA_ "GenSigSendType" SG_ 1364 ICC_RISD_Pixel502_OnOff 5;
BA_ "GenSigSendType" SG_ 1364 ICC_RISD_Pixel501_OnOff 5;
BA_ "GenSigSendType" SG_ 1364 ICC_RISD_Pixel500_OnOff 5;
BA_ "GenSigSendType" SG_ 1364 ICC_RISD_Pixel499_OnOff 5;
BA_ "GenSigSendType" SG_ 1364 ICC_RISD_Pixel498_OnOff 5;
BA_ "GenSigSendType" SG_ 1364 ICC_RISD_Pixel497_OnOff 5;
BA_ "GenSigSendType" SG_ 1364 ICC_RISD_Pixel496_OnOff 5;
BA_ "GenSigSendType" SG_ 1364 ICC_RISD_Pixel495_OnOff 5;
BA_ "GenSigSendType" SG_ 1364 ICC_RISD_Pixel494_OnOff 5;
BA_ "GenSigSendType" SG_ 1364 ICC_RISD_Pixel493_OnOff 5;
BA_ "GenSigSendType" SG_ 1364 ICC_RISD_Pixel492_OnOff 5;
BA_ "GenSigSendType" SG_ 1364 ICC_RISD_Pixel491_OnOff 5;
BA_ "GenSigSendType" SG_ 1364 ICC_RISD_Pixel490_OnOff 5;
BA_ "GenSigSendType" SG_ 1364 ICC_RISD_Pixel489_OnOff 5;
BA_ "GenSigSendType" SG_ 1364 ICC_RISD_Pixel488_OnOff 5;
BA_ "GenSigSendType" SG_ 1364 ICC_RISD_Pixel487_OnOff 5;
BA_ "GenSigSendType" SG_ 1364 ICC_RISD_Pixel486_OnOff 5;
BA_ "GenSigSendType" SG_ 1364 ICC_RISD_Pixel485_OnOff 5;
BA_ "GenSigSendType" SG_ 1364 ICC_RISD_Pixel484_OnOff 5;
BA_ "GenSigSendType" SG_ 1364 ICC_RISD_Pixel483_OnOff 5;
BA_ "GenSigSendType" SG_ 1364 ICC_RISD_Pixel482_OnOff 5;
BA_ "GenSigSendType" SG_ 1364 ICC_RISD_Pixel481_OnOff 5;
BA_ "GenSigSendType" SG_ 1364 ICC_RISD_Pixel480_OnOff 5;
BA_ "GenSigSendType" SG_ 1364 ICC_RISD_Pixel479_OnOff 5;
BA_ "GenSigSendType" SG_ 1364 ICC_RISD_Pixel478_OnOff 5;
BA_ "GenSigSendType" SG_ 1364 ICC_RISD_Pixel477_OnOff 5;
BA_ "GenSigSendType" SG_ 1364 ICC_RISD_Pixel476_OnOff 5;
BA_ "GenSigSendType" SG_ 1364 ICC_RISD_Pixel475_OnOff 5;
BA_ "GenSigSendType" SG_ 1364 ICC_RISD_Pixel474_OnOff 5;
BA_ "GenSigSendType" SG_ 1364 ICC_RISD_Pixel473_OnOff 5;
BA_ "GenSigSendType" SG_ 1364 ICC_RISD_Pixel472_OnOff 5;
BA_ "GenSigSendType" SG_ 1364 ICC_RISD_Pixel471_OnOff 5;
BA_ "GenSigSendType" SG_ 1364 ICC_RISD_Pixel470_OnOff 5;
BA_ "GenSigSendType" SG_ 1364 ICC_RISD_Pixel469_OnOff 5;
BA_ "GenSigSendType" SG_ 1364 ICC_RISD_Pixel468_OnOff 5;
BA_ "GenSigSendType" SG_ 1364 ICC_RISD_Pixel467_OnOff 5;
BA_ "GenSigSendType" SG_ 1364 ICC_RISD_Pixel466_OnOff 5;
BA_ "GenSigSendType" SG_ 1364 ICC_RISD_Pixel465_OnOff 5;
BA_ "GenSigSendType" SG_ 1364 ICC_RISD_Pixel464_OnOff 5;
BA_ "GenSigSendType" SG_ 1364 ICC_RISD_Pixel463_OnOff 5;
BA_ "GenSigSendType" SG_ 1364 ICC_RISD_Pixel462_OnOff 5;
BA_ "GenSigSendType" SG_ 1364 ICC_RISD_Pixel461_OnOff 5;
BA_ "GenSigSendType" SG_ 1364 ICC_RISD_Pixel460_OnOff 5;
BA_ "GenSigSendType" SG_ 1364 ICC_RISD_Pixel459_OnOff 5;
BA_ "GenSigSendType" SG_ 1364 ICC_RISD_Pixel458_OnOff 5;
BA_ "GenSigSendType" SG_ 1364 ICC_RISD_Pixel457_OnOff 5;
BA_ "GenSigSendType" SG_ 1364 ICC_RISD_Pixel456_OnOff 5;
BA_ "GenSigSendType" SG_ 1364 ICC_RISD_Pixel455_OnOff 5;
BA_ "GenSigSendType" SG_ 1364 ICC_RISD_Pixel454_OnOff 5;
BA_ "GenSigSendType" SG_ 1364 ICC_RISD_Pixel453_OnOff 5;
BA_ "GenSigSendType" SG_ 1364 ICC_RISD_Pixel452_OnOff 5;
BA_ "GenSigSendType" SG_ 1364 ICC_RISD_Pixel451_OnOff 5;
BA_ "GenSigSendType" SG_ 1364 ICC_RISD_Pixel450_OnOff 5;
BA_ "GenSigSendType" SG_ 1364 ICC_RISD_Pixel449_OnOff 5;
BA_ "GenSigSendType" SG_ 1364 ICC_RISD_Pixel448_OnOff 5;
BA_ "GenSigSendType" SG_ 1364 ICC_RISD_Pixel447_OnOff 5;
BA_ "GenSigSendType" SG_ 1364 ICC_RISD_Pixel446_OnOff 5;
BA_ "GenSigSendType" SG_ 1364 ICC_RISD_Pixel445_OnOff 5;
BA_ "GenSigSendType" SG_ 1364 ICC_RISD_Pixel444_OnOff 5;
BA_ "GenSigSendType" SG_ 1364 ICC_RISD_Pixel443_OnOff 5;
BA_ "GenSigSendType" SG_ 1364 ICC_RISD_Pixel442_OnOff 5;
BA_ "GenSigSendType" SG_ 1364 ICC_RISD_Pixel441_OnOff 5;
BA_ "GenSigSendType" SG_ 1364 ICC_RISD_Pixel440_OnOff 5;
BA_ "GenSigSendType" SG_ 1364 ICC_RISD_Pixel439_OnOff 5;
BA_ "GenSigSendType" SG_ 1364 ICC_RISD_Pixel438_OnOff 5;
BA_ "GenSigSendType" SG_ 1364 ICC_RISD_Pixel437_OnOff 5;
BA_ "GenSigSendType" SG_ 1364 ICC_RISD_Pixel436_OnOff 5;
BA_ "GenSigSendType" SG_ 1364 ICC_RISD_Pixel435_OnOff 5;
BA_ "GenSigSendType" SG_ 1364 ICC_RISD_Pixel434_OnOff 5;
BA_ "GenSigSendType" SG_ 1364 ICC_RISD_Pixel433_OnOff 5;
BA_ "GenSigSendType" SG_ 1364 ICC_RISD_Pixel432_OnOff 5;
BA_ "GenSigSendType" SG_ 1364 ICC_RISD_Pixel431_OnOff 5;
BA_ "GenSigSendType" SG_ 1364 ICC_RISD_Pixel430_OnOff 5;
BA_ "GenSigSendType" SG_ 1364 ICC_RISD_Pixel429_OnOff 5;
BA_ "GenSigSendType" SG_ 1364 ICC_RISD_Pixel428_OnOff 5;
BA_ "GenSigSendType" SG_ 1364 ICC_RISD_Pixel427_OnOff 5;
BA_ "GenSigSendType" SG_ 1364 ICC_RISD_Pixel426_OnOff 5;
BA_ "GenSigSendType" SG_ 1364 ICC_RISD_Pixel425_OnOff 5;
BA_ "GenSigSendType" SG_ 1364 ICC_RISD_Pixel424_OnOff 5;
BA_ "GenSigSendType" SG_ 1364 ICC_RISD_Pixel423_OnOff 5;
BA_ "GenSigSendType" SG_ 1364 ICC_RISD_Pixel422_OnOff 5;
BA_ "GenSigSendType" SG_ 1364 ICC_RISD_Pixel421_OnOff 5;
BA_ "GenSigSendType" SG_ 1364 ICC_RISD_Pixel420_OnOff 5;
BA_ "GenSigSendType" SG_ 1364 ICC_RISD_Pixel419_OnOff 5;
BA_ "GenSigSendType" SG_ 1364 ICC_RISD_Pixel418_OnOff 5;
BA_ "GenSigSendType" SG_ 1364 ICC_RISD_Pixel417_OnOff 5;
BA_ "GenSigSendType" SG_ 1364 ICC_RISD_Pixel416_OnOff 5;
BA_ "GenSigSendType" SG_ 1364 ICC_RISD_Pixel415_OnOff 5;
BA_ "GenSigSendType" SG_ 1364 ICC_RISD_Pixel414_OnOff 5;
BA_ "GenSigSendType" SG_ 1364 ICC_RISD_Pixel413_OnOff 5;
BA_ "GenSigSendType" SG_ 1364 ICC_RISD_Pixel412_OnOff 5;
BA_ "GenSigSendType" SG_ 1364 ICC_RISD_Pixel411_OnOff 5;
BA_ "GenSigSendType" SG_ 1364 ICC_RISD_Pixel410_OnOff 5;
BA_ "GenSigSendType" SG_ 1364 ICC_RISD_Pixel409_OnOff 5;
BA_ "GenSigSendType" SG_ 1364 ICC_RISD_Pixel408_OnOff 5;
BA_ "GenSigSendType" SG_ 1364 ICC_RISD_Pixel407_OnOff 5;
BA_ "GenSigSendType" SG_ 1364 ICC_RISD_Pixel406_OnOff 5;
BA_ "GenSigSendType" SG_ 1364 ICC_RISD_Pixel405_OnOff 5;
BA_ "GenSigSendType" SG_ 1364 ICC_RISD_Pixel404_OnOff 5;
BA_ "GenSigSendType" SG_ 1364 ICC_RISD_Pixel403_OnOff 5;
BA_ "GenSigSendType" SG_ 1364 ICC_RISD_Pixel402_OnOff 5;
BA_ "GenSigSendType" SG_ 1364 ICC_RISD_Pixel401_OnOff 5;
BA_ "GenSigSendType" SG_ 1364 ICC_RISD_Pixel400_OnOff 5;
BA_ "GenSigSendType" SG_ 1364 ICC_RISD_Pixel399_OnOff 5;
BA_ "GenSigSendType" SG_ 1364 ICC_RISD_Pixel398_OnOff 5;
BA_ "GenSigSendType" SG_ 1364 ICC_RISD_Pixel397_OnOff 5;
BA_ "GenSigSendType" SG_ 1364 ICC_RISD_Pixel396_OnOff 5;
BA_ "GenSigSendType" SG_ 1364 ICC_RISD_Pixel395_OnOff 5;
BA_ "GenSigSendType" SG_ 1364 ICC_RISD_Pixel394_OnOff 5;
BA_ "GenSigSendType" SG_ 1364 ICC_RISD_Pixel393_OnOff 5;
BA_ "GenSigSendType" SG_ 1364 ICC_RISD_Pixel392_OnOff 5;
BA_ "GenSigSendType" SG_ 1364 ICC_RISD_Pixel391_OnOff 5;
BA_ "GenSigSendType" SG_ 1364 ICC_RISD_Pixel390_OnOff 5;
BA_ "GenSigSendType" SG_ 1364 ICC_RISD_Pixel389_OnOff 5;
BA_ "GenSigSendType" SG_ 1364 ICC_RISD_Pixel388_OnOff 5;
BA_ "GenSigSendType" SG_ 1364 ICC_RISD_Pixel387_OnOff 5;
BA_ "GenSigSendType" SG_ 1364 ICC_RISD_Pixel386_OnOff 5;
BA_ "GenSigSendType" SG_ 1364 ICC_RISD_Pixel385_OnOff 5;
BA_ "GenSigSendType" SG_ 1364 ICC_RISD_Pixel384_OnOff 5;
BA_ "GenSigSendType" SG_ 1364 ICC_RISD_Pixel383_OnOff 5;
BA_ "GenSigSendType" SG_ 1364 ICC_RISD_Pixel382_OnOff 5;
BA_ "GenSigSendType" SG_ 1364 ICC_RISD_Pixel381_OnOff 5;
BA_ "GenSigSendType" SG_ 1364 ICC_RISD_Pixel380_OnOff 5;
BA_ "GenSigSendType" SG_ 1364 ICC_RISD_Pixel379_OnOff 5;
BA_ "GenSigSendType" SG_ 1364 ICC_RISD_Pixel378_OnOff 5;
BA_ "GenSigSendType" SG_ 1364 ICC_RISD_Pixel377_OnOff 5;
BA_ "GenSigSendType" SG_ 1364 ICC_RISD_Pixel376_OnOff 5;
BA_ "GenSigSendType" SG_ 1364 ICC_RISD_Pixel375_OnOff 5;
BA_ "GenSigSendType" SG_ 1364 ICC_RISD_Pixel374_OnOff 5;
BA_ "GenSigSendType" SG_ 1364 ICC_RISD_Pixel373_OnOff 5;
BA_ "GenSigSendType" SG_ 1364 ICC_RISD_Pixel372_OnOff 5;
BA_ "GenSigSendType" SG_ 1364 ICC_RISD_Pixel371_OnOff 5;
BA_ "GenSigSendType" SG_ 1364 ICC_RISD_Pixel370_OnOff 5;
BA_ "GenSigSendType" SG_ 1364 ICC_RISD_Pixel369_OnOff 5;
BA_ "GenSigSendType" SG_ 1364 ICC_RISD_Pixel368_OnOff 5;
BA_ "GenSigSendType" SG_ 1364 ICC_RISD_Pixel367_OnOff 5;
BA_ "GenSigSendType" SG_ 1364 ICC_RISD_Pixel366_OnOff 5;
BA_ "GenSigSendType" SG_ 1364 ICC_RISD_Pixel365_OnOff 5;
BA_ "GenSigSendType" SG_ 1364 ICC_RISD_Pixel364_OnOff 5;
BA_ "GenSigSendType" SG_ 1364 ICC_RISD_Pixel363_OnOff 5;
BA_ "GenSigSendType" SG_ 1364 ICC_RISD_Pixel362_OnOff 5;
BA_ "GenSigSendType" SG_ 1364 ICC_RISD_Pixel361_OnOff 5;
BA_ "GenSigSendType" SG_ 1364 ICC_RISD_Pixel360_OnOff 5;
BA_ "GenSigSendType" SG_ 1364 ICC_RISD_Pixel359_OnOff 5;
BA_ "GenSigSendType" SG_ 1364 ICC_RISD_Pixel358_OnOff 5;
BA_ "GenSigSendType" SG_ 1364 ICC_RISD_Pixel357_OnOff 5;
BA_ "GenSigSendType" SG_ 1364 ICC_RISD_Pixel356_OnOff 5;
BA_ "GenSigSendType" SG_ 1364 ICC_RISD_Pixel355_OnOff 5;
BA_ "GenSigSendType" SG_ 1364 ICC_RISD_Pixel354_OnOff 5;
BA_ "GenSigSendType" SG_ 1364 ICC_RISD_Pixel353_OnOff 5;
BA_ "GenSigSendType" SG_ 1364 ICC_RISD_Pixel352_OnOff 5;
BA_ "GenSigSendType" SG_ 1364 ICC_RISD_Pixel351_OnOff 5;
BA_ "GenSigSendType" SG_ 1364 ICC_RISD_Pixel350_OnOff 5;
BA_ "GenSigSendType" SG_ 1364 ICC_RISD_Pixel349_OnOff 5;
BA_ "GenSigSendType" SG_ 1364 ICC_RISD_Pixel348_OnOff 5;
BA_ "GenSigSendType" SG_ 1364 ICC_RISD_Pixel347_OnOff 5;
BA_ "GenSigSendType" SG_ 1364 ICC_RISD_Pixel346_OnOff 5;
BA_ "GenSigSendType" SG_ 1364 ICC_RISD_Pixel345_OnOff 5;
BA_ "GenSigSendType" SG_ 1364 ICC_RISD_Pixel344_OnOff 5;
BA_ "GenSigSendType" SG_ 1364 ICC_RISD_Pixel343_OnOff 5;
BA_ "GenSigSendType" SG_ 1364 ICC_RISD_Pixel342_OnOff 5;
BA_ "GenSigSendType" SG_ 1364 ICC_RISD_Pixel341_OnOff 5;
BA_ "GenSigSendType" SG_ 1364 ICC_RISD_Pixel340_OnOff 5;
BA_ "GenSigSendType" SG_ 1364 ICC_RISD_Pixel339_OnOff 5;
BA_ "GenSigSendType" SG_ 1364 ICC_RISD_Pixel338_OnOff 5;
BA_ "GenSigSendType" SG_ 1364 ICC_RISD_Pixel337_OnOff 5;
BA_ "GenSigSendType" SG_ 1364 ICC_RISD_Pixel336_OnOff 5;
BA_ "GenSigSendType" SG_ 1364 ICC_RISD_Pixel335_OnOff 5;
BA_ "GenSigSendType" SG_ 1364 ICC_RISD_Pixel334_OnOff 5;
BA_ "GenSigSendType" SG_ 1364 ICC_RISD_Pixel333_OnOff 5;
BA_ "GenSigSendType" SG_ 1364 ICC_RISD_Pixel332_OnOff 5;
BA_ "GenSigSendType" SG_ 1364 ICC_RISD_Pixel331_OnOff 5;
BA_ "GenSigSendType" SG_ 1364 ICC_RISD_Pixel330_OnOff 5;
BA_ "GenSigSendType" SG_ 1364 ICC_RISD_Pixel329_OnOff 5;
BA_ "GenSigSendType" SG_ 1364 ICC_RISD_Pixel328_OnOff 5;
BA_ "GenSigSendType" SG_ 1364 ICC_RISD_Pixel327_OnOff 5;
BA_ "GenSigSendType" SG_ 1364 ICC_RISD_Pixel326_OnOff 5;
BA_ "GenSigSendType" SG_ 1364 ICC_RISD_Pixel325_OnOff 5;
BA_ "GenSigSendType" SG_ 1364 ICC_RISD_Pixel324_OnOff 5;
BA_ "GenSigSendType" SG_ 1364 ICC_RISD_Pixel323_OnOff 5;
BA_ "GenSigSendType" SG_ 1364 ICC_RISD_Pixel322_OnOff 5;
BA_ "GenSigSendType" SG_ 1364 ICC_RISD_Pixel321_OnOff 5;
BA_ "GenSigSendType" SG_ 1364 ICC_RISD_Pixel320_OnOff 5;
BA_ "GenSigSendType" SG_ 1364 ICC_RISD_Pixel319_OnOff 5;
BA_ "GenSigSendType" SG_ 1364 ICC_RISD_Pixel318_OnOff 5;
BA_ "GenSigSendType" SG_ 1364 ICC_RISD_Pixel317_OnOff 5;
BA_ "GenSigSendType" SG_ 1364 ICC_RISD_Pixel316_OnOff 5;
BA_ "GenSigSendType" SG_ 1364 ICC_RISD_Pixel315_OnOff 5;
BA_ "GenSigSendType" SG_ 1364 ICC_RISD_Pixel314_OnOff 5;
BA_ "GenSigSendType" SG_ 1364 ICC_RISD_Pixel313_OnOff 5;
BA_ "GenSigSendType" SG_ 1364 ICC_RISD_Pixel312_OnOff 5;
BA_ "GenSigSendType" SG_ 1364 ICC_RISD_Pixel311_OnOff 5;
BA_ "GenSigSendType" SG_ 1364 ICC_RISD_Pixel310_OnOff 5;
BA_ "GenSigSendType" SG_ 1364 ICC_RISD_Pixel309_OnOff 5;
BA_ "GenSigSendType" SG_ 1364 ICC_RISD_Pixel308_OnOff 5;
BA_ "GenSigSendType" SG_ 1364 ICC_RISD_Pixel307_OnOff 5;
BA_ "GenSigSendType" SG_ 1364 ICC_RISD_Pixel306_OnOff 5;
BA_ "GenSigSendType" SG_ 1364 ICC_RISD_Pixel305_OnOff 5;
BA_ "GenSigSendType" SG_ 1364 ICC_RISD_Pixel304_OnOff 5;
BA_ "GenSigSendType" SG_ 1364 ICC_RISD_Pixel303_OnOff 5;
BA_ "GenSigSendType" SG_ 1364 ICC_RISD_Pixel302_OnOff 5;
BA_ "GenSigSendType" SG_ 1364 ICC_RISD_Pixel301_OnOff 5;
BA_ "GenSigSendType" SG_ 1364 ICC_RISD_Pixel300_OnOff 5;
BA_ "GenSigSendType" SG_ 1364 ICC_RISD_Pixel299_OnOff 5;
BA_ "GenSigSendType" SG_ 1364 ICC_RISD_Pixel298_OnOff 5;
BA_ "GenSigSendType" SG_ 1364 ICC_RISD_Pixel297_OnOff 5;
BA_ "GenSigSendType" SG_ 1364 ICC_RISD_Pixel296_OnOff 5;
BA_ "GenSigSendType" SG_ 1364 ICC_RISD_Pixel295_OnOff 5;
BA_ "GenSigSendType" SG_ 1364 ICC_RISD_Pixel294_OnOff 5;
BA_ "GenSigSendType" SG_ 1364 ICC_RISD_Pixel293_OnOff 5;
BA_ "GenSigSendType" SG_ 1364 ICC_RISD_Pixel292_OnOff 5;
BA_ "GenSigSendType" SG_ 1364 ICC_RISD_Pixel291_OnOff 5;
BA_ "GenSigSendType" SG_ 1364 ICC_RISD_Pixel290_OnOff 5;
BA_ "GenSigSendType" SG_ 1364 ICC_RISD_Pixel289_OnOff 5;
BA_ "GenSigSendType" SG_ 1364 ICC_RISD_Pixel288_OnOff 5;
BA_ "GenSigSendType" SG_ 1364 ICC_RISD_Pixel287_OnOff 5;
BA_ "GenSigSendType" SG_ 1364 ICC_RISD_Pixel286_OnOff 5;
BA_ "GenSigSendType" SG_ 1364 ICC_RISD_Pixel285_OnOff 5;
BA_ "GenSigSendType" SG_ 1364 ICC_RISD_Pixel284_OnOff 5;
BA_ "GenSigSendType" SG_ 1364 ICC_RISD_Pixel283_OnOff 5;
BA_ "GenSigSendType" SG_ 1364 ICC_RISD_Pixel282_OnOff 5;
BA_ "GenSigSendType" SG_ 1364 ICC_RISD_Pixel281_OnOff 5;
BA_ "GenSigSendType" SG_ 1364 ICC_RISD_Pixel280_OnOff 5;
BA_ "GenSigSendType" SG_ 1364 ICC_RISD_Pixel279_OnOff 5;
BA_ "GenSigSendType" SG_ 1364 ICC_RISD_Pixel278_OnOff 5;
BA_ "GenSigSendType" SG_ 1364 ICC_RISD_Pixel277_OnOff 5;
BA_ "GenSigSendType" SG_ 1364 ICC_RISD_Pixel276_OnOff 5;
BA_ "GenSigSendType" SG_ 1364 ICC_RISD_Pixel275_OnOff 5;
BA_ "GenSigSendType" SG_ 1364 ICC_RISD_Pixel274_OnOff 5;
BA_ "GenSigSendType" SG_ 1364 ICC_RISD_Pixel273_OnOff 5;
BA_ "GenSigSendType" SG_ 1364 ICC_RISD_Pixel272_OnOff 5;
BA_ "GenSigSendType" SG_ 1364 ICC_RISD_Pixel271_OnOff 5;
BA_ "GenSigSendType" SG_ 1364 ICC_RISD_Pixel270_OnOff 5;
BA_ "GenSigSendType" SG_ 1364 ICC_RISD_Pixel269_OnOff 5;
BA_ "GenSigSendType" SG_ 1364 ICC_RISD_Pixel268_OnOff 5;
BA_ "GenSigSendType" SG_ 1364 ICC_RISD_Pixel267_OnOff 5;
BA_ "GenSigSendType" SG_ 1364 ICC_RISD_Pixel266_OnOff 5;
BA_ "GenSigSendType" SG_ 1364 ICC_RISD_Pixel265_OnOff 5;
BA_ "GenSigSendType" SG_ 1364 ICC_RISD_Pixel264_OnOff 5;
BA_ "GenSigSendType" SG_ 1364 ICC_RISD_Pixel263_OnOff 5;
BA_ "GenSigSendType" SG_ 1364 ICC_RISD_Pixel262_OnOff 5;
BA_ "GenSigSendType" SG_ 1364 ICC_RISD_Pixel261_OnOff 5;
BA_ "GenSigSendType" SG_ 1364 ICC_RISD_Pixel260_OnOff 5;
BA_ "GenSigSendType" SG_ 1364 ICC_RISD_Pixel259_OnOff 5;
BA_ "GenSigSendType" SG_ 1364 ICC_RISD_Pixel258_OnOff 5;
BA_ "GenSigSendType" SG_ 1364 ICC_RISD_Pixel257_OnOff 5;
BA_ "GenSigSendType" SG_ 1364 ICC_RISD_Pixel256_OnOff 5;
BA_ "GenSigSendType" SG_ 1364 ICC_RISD_Pixel255_OnOff 5;
BA_ "GenSigSendType" SG_ 1364 ICC_RISD_Pixel254_OnOff 5;
BA_ "GenSigSendType" SG_ 1364 ICC_RISD_Pixel253_OnOff 5;
BA_ "GenSigSendType" SG_ 1364 ICC_RISD_Pixel252_OnOff 5;
BA_ "GenSigSendType" SG_ 1364 ICC_RISD_Pixel251_OnOff 5;
BA_ "GenSigSendType" SG_ 1364 ICC_RISD_Pixel250_OnOff 5;
BA_ "GenSigSendType" SG_ 1364 ICC_RISD_Pixel249_OnOff 5;
BA_ "GenSigSendType" SG_ 1364 ICC_RISD_Pixel248_OnOff 5;
BA_ "GenSigSendType" SG_ 1364 ICC_RISD_Pixel247_OnOff 5;
BA_ "GenSigSendType" SG_ 1364 ICC_RISD_Pixel246_OnOff 5;
BA_ "GenSigSendType" SG_ 1364 ICC_RISD_Pixel245_OnOff 5;
BA_ "GenSigSendType" SG_ 1364 ICC_RISD_Pixel244_OnOff 5;
BA_ "GenSigSendType" SG_ 1364 ICC_RISD_Pixel243_OnOff 5;
BA_ "GenSigSendType" SG_ 1364 ICC_RISD_Pixel242_OnOff 5;
BA_ "GenSigSendType" SG_ 1364 ICC_RISD_Pixel241_OnOff 5;
BA_ "GenSigSendType" SG_ 1364 ICC_RISD_Pixel240_OnOff 5;
BA_ "GenSigSendType" SG_ 1364 ICC_RISD_Pixel239_OnOff 5;
BA_ "GenSigSendType" SG_ 1364 ICC_RISD_Pixel238_OnOff 5;
BA_ "GenSigSendType" SG_ 1364 ICC_RISD_Pixel237_OnOff 5;
BA_ "GenSigSendType" SG_ 1364 ICC_RISD_Pixel236_OnOff 5;
BA_ "GenSigSendType" SG_ 1364 ICC_RISD_Pixel235_OnOff 5;
BA_ "GenSigSendType" SG_ 1364 ICC_RISD_Pixel234_OnOff 5;
BA_ "GenSigSendType" SG_ 1364 ICC_RISD_Pixel233_OnOff 5;
BA_ "GenSigSendType" SG_ 1364 ICC_RISD_Pixel232_OnOff 5;
BA_ "GenSigSendType" SG_ 1364 ICC_RISD_Pixel231_OnOff 5;
BA_ "GenSigSendType" SG_ 1364 ICC_RISD_Pixel230_OnOff 5;
BA_ "GenSigSendType" SG_ 1364 ICC_RISD_Pixel229_OnOff 5;
BA_ "GenSigSendType" SG_ 1364 ICC_RISD_Pixel228_OnOff 5;
BA_ "GenSigSendType" SG_ 1364 ICC_RISD_Pixel227_OnOff 5;
BA_ "GenSigSendType" SG_ 1364 ICC_RISD_Pixel226_OnOff 5;
BA_ "GenSigSendType" SG_ 1364 ICC_RISD_Pixel225_OnOff 5;
BA_ "GenSigSendType" SG_ 1364 ICC_RISD_Pixel224_OnOff 5;
BA_ "GenSigSendType" SG_ 1364 ICC_RISD_Pixel223_OnOff 5;
BA_ "GenSigSendType" SG_ 1364 ICC_RISD_Pixel222_OnOff 5;
BA_ "GenSigSendType" SG_ 1364 ICC_RISD_Pixel221_OnOff 5;
BA_ "GenSigSendType" SG_ 1364 ICC_RISD_Pixel220_OnOff 5;
BA_ "GenSigSendType" SG_ 1364 ICC_RISD_Pixel219_OnOff 5;
BA_ "GenSigSendType" SG_ 1364 ICC_RISD_Pixel218_OnOff 5;
BA_ "GenSigSendType" SG_ 1364 ICC_RISD_Pixel217_OnOff 5;
BA_ "GenSigSendType" SG_ 1364 ICC_RISD_Pixel216_OnOff 5;
BA_ "GenSigSendType" SG_ 1364 ICC_RISD_Pixel215_OnOff 5;
BA_ "GenSigSendType" SG_ 1364 ICC_RISD_Pixel214_OnOff 5;
BA_ "GenSigSendType" SG_ 1364 ICC_RISD_Pixel213_OnOff 5;
BA_ "GenSigSendType" SG_ 1364 ICC_RISD_Pixel212_OnOff 5;
BA_ "GenSigSendType" SG_ 1364 ICC_RISD_Pixel211_OnOff 5;
BA_ "GenSigSendType" SG_ 1364 ICC_RISD_Pixel210_OnOff 5;
BA_ "GenSigSendType" SG_ 1364 ICC_RISD_Pixel209_OnOff 5;
BA_ "GenSigSendType" SG_ 1364 ICC_RISD_Pixel208_OnOff 5;
BA_ "GenSigSendType" SG_ 1364 ICC_RISD_Pixel207_OnOff 5;
BA_ "GenSigSendType" SG_ 1364 ICC_RISD_Pixel206_OnOff 5;
BA_ "GenSigSendType" SG_ 1364 ICC_RISD_Pixel205_OnOff 5;
BA_ "GenSigSendType" SG_ 1364 ICC_RISD_Pixel204_OnOff 5;
BA_ "GenSigSendType" SG_ 1364 ICC_RISD_Pixel203_OnOff 5;
BA_ "GenSigSendType" SG_ 1364 ICC_RISD_Pixel202_OnOff 5;
BA_ "GenSigSendType" SG_ 1364 ICC_RISD_Pixel201_OnOff 5;
BA_ "GenSigSendType" SG_ 1364 ICC_RISD_Pixel200_OnOff 5;
BA_ "GenSigSendType" SG_ 1364 ICC_RISD_Pixel199_OnOff 5;
BA_ "GenSigSendType" SG_ 1364 ICC_RISD_Pixel198_OnOff 5;
BA_ "GenSigSendType" SG_ 1364 ICC_RISD_Pixel197_OnOff 5;
BA_ "GenSigSendType" SG_ 1364 ICC_RISD_Pixel196_OnOff 5;
BA_ "GenSigSendType" SG_ 1364 ICC_RISD_Pixel195_OnOff 5;
BA_ "GenSigSendType" SG_ 1364 ICC_RISD_Pixel194_OnOff 5;
BA_ "GenSigSendType" SG_ 1364 ICC_RISD_Pixel193_OnOff 5;
BA_ "GenSigSendType" SG_ 1364 ICC_RISD_Pixel192_OnOff 5;
BA_ "GenSigSendType" SG_ 1364 ICC_RISD_Pixel191_OnOff 5;
BA_ "GenSigSendType" SG_ 1364 ICC_RISD_Pixel190_OnOff 5;
BA_ "GenSigSendType" SG_ 1364 ICC_RISD_Pixel189_OnOff 5;
BA_ "GenSigSendType" SG_ 1364 ICC_RISD_Pixel188_OnOff 5;
BA_ "GenSigSendType" SG_ 1364 ICC_RISD_Pixel187_OnOff 5;
BA_ "GenSigSendType" SG_ 1364 ICC_RISD_Pixel186_OnOff 5;
BA_ "GenSigSendType" SG_ 1364 ICC_RISD_Pixel185_OnOff 5;
BA_ "GenSigSendType" SG_ 1364 ICC_RISD_Pixel184_OnOff 5;
BA_ "GenSigSendType" SG_ 1364 ICC_RISD_Pixel183_OnOff 5;
BA_ "GenSigSendType" SG_ 1364 ICC_RISD_Pixel182_OnOff 5;
BA_ "GenSigSendType" SG_ 1364 ICC_RISD_Pixel181_OnOff 5;
BA_ "GenSigSendType" SG_ 1364 ICC_RISD_Pixel180_OnOff 5;
BA_ "GenSigSendType" SG_ 1364 ICC_RISD_Pixel179_OnOff 5;
BA_ "GenSigSendType" SG_ 1364 ICC_RISD_Pixel178_OnOff 5;
BA_ "GenSigSendType" SG_ 1364 ICC_RISD_Pixel177_OnOff 5;
BA_ "GenSigSendType" SG_ 1364 ICC_RISD_Pixel176_OnOff 5;
BA_ "GenSigSendType" SG_ 1364 ICC_RISD_Pixel175_OnOff 5;
BA_ "GenSigSendType" SG_ 1364 ICC_RISD_Pixel174_OnOff 5;
BA_ "GenSigSendType" SG_ 1364 ICC_RISD_Pixel173_OnOff 5;
BA_ "GenSigSendType" SG_ 1364 ICC_RISD_Pixel172_OnOff 5;
BA_ "GenSigSendType" SG_ 1364 ICC_RISD_Pixel171_OnOff 5;
BA_ "GenSigSendType" SG_ 1364 ICC_RISD_Pixel170_OnOff 5;
BA_ "GenSigSendType" SG_ 1364 ICC_RISD_Pixel169_OnOff 5;
BA_ "GenSigSendType" SG_ 1364 ICC_RISD_Pixel168_OnOff 5;
BA_ "GenSigSendType" SG_ 1364 ICC_RISD_Pixel167_OnOff 5;
BA_ "GenSigSendType" SG_ 1364 ICC_RISD_Pixel166_OnOff 5;
BA_ "GenSigSendType" SG_ 1364 ICC_RISD_Pixel165_OnOff 5;
BA_ "GenSigSendType" SG_ 1364 ICC_RISD_Pixel164_OnOff 5;
BA_ "GenSigSendType" SG_ 1364 ICC_RISD_Pixel163_OnOff 5;
BA_ "GenSigSendType" SG_ 1364 ICC_RISD_Pixel162_OnOff 5;
BA_ "GenSigSendType" SG_ 1364 ICC_RISD_Pixel161_OnOff 5;
BA_ "GenSigSendType" SG_ 1364 ICC_RISD_Pixel160_OnOff 5;
BA_ "GenSigSendType" SG_ 1364 ICC_RISD_Pixel159_OnOff 5;
BA_ "GenSigSendType" SG_ 1364 ICC_RISD_Pixel158_OnOff 5;
BA_ "GenSigSendType" SG_ 1364 ICC_RISD_Pixel157_OnOff 5;
BA_ "GenSigSendType" SG_ 1364 ICC_RISD_Pixel156_OnOff 5;
BA_ "GenSigSendType" SG_ 1364 ICC_RISD_Pixel155_OnOff 5;
BA_ "GenSigSendType" SG_ 1364 ICC_RISD_Pixel154_OnOff 5;
BA_ "GenSigSendType" SG_ 1364 ICC_RISD_Pixel153_OnOff 5;
BA_ "GenSigSendType" SG_ 1364 ICC_RISD_Pixel152_OnOff 5;
BA_ "GenSigSendType" SG_ 1364 ICC_RISD_Pixel151_OnOff 5;
BA_ "GenSigSendType" SG_ 1364 ICC_RISD_Pixel150_OnOff 5;
BA_ "GenSigSendType" SG_ 1364 ICC_RISD_Pixel149_OnOff 5;
BA_ "GenSigSendType" SG_ 1364 ICC_RISD_Pixel148_OnOff 5;
BA_ "GenSigSendType" SG_ 1364 ICC_RISD_Pixel147_OnOff 5;
BA_ "GenSigSendType" SG_ 1364 ICC_RISD_Pixel146_OnOff 5;
BA_ "GenSigSendType" SG_ 1364 ICC_RISD_Pixel145_OnOff 5;
BA_ "GenSigSendType" SG_ 1364 ICC_RISD_Pixel144_OnOff 5;
BA_ "GenSigSendType" SG_ 1364 ICC_RISD_Pixel143_OnOff 5;
BA_ "GenSigSendType" SG_ 1364 ICC_RISD_Pixel142_OnOff 5;
BA_ "GenSigSendType" SG_ 1364 ICC_RISD_Pixel141_OnOff 5;
BA_ "GenSigSendType" SG_ 1364 ICC_RISD_Pixel140_OnOff 5;
BA_ "GenSigSendType" SG_ 1364 ICC_RISD_Pixel139_OnOff 5;
BA_ "GenSigSendType" SG_ 1364 ICC_RISD_Pixel138_OnOff 5;
BA_ "GenSigSendType" SG_ 1364 ICC_RISD_Pixel137_OnOff 5;
BA_ "GenSigSendType" SG_ 1364 ICC_RISD_Pixel136_OnOff 5;
BA_ "GenSigSendType" SG_ 1364 ICC_RISD_Pixel135_OnOff 5;
BA_ "GenSigSendType" SG_ 1364 ICC_RISD_Pixel134_OnOff 5;
BA_ "GenSigSendType" SG_ 1364 ICC_RISD_Pixel133_OnOff 5;
BA_ "GenSigSendType" SG_ 1364 ICC_RISD_Pixel132_OnOff 5;
BA_ "GenSigSendType" SG_ 1364 ICC_RISD_Pixel131_OnOff 5;
BA_ "GenSigSendType" SG_ 1364 ICC_RISD_Pixel130_OnOff 5;
BA_ "GenSigSendType" SG_ 1364 ICC_RISD_Pixel129_OnOff 5;
BA_ "GenSigSendType" SG_ 1364 ICC_RISD_Pixel128_OnOff 5;
BA_ "GenSigSendType" SG_ 1364 ICC_RISD_Pixel127_OnOff 5;
BA_ "GenSigSendType" SG_ 1364 ICC_RISD_Pixel126_OnOff 5;
BA_ "GenSigSendType" SG_ 1364 ICC_RISD_Pixel125_OnOff 5;
BA_ "GenSigSendType" SG_ 1364 ICC_RISD_Pixel124_OnOff 5;
BA_ "GenSigSendType" SG_ 1364 ICC_RISD_Pixel123_OnOff 5;
BA_ "GenSigSendType" SG_ 1364 ICC_RISD_Pixel122_OnOff 5;
BA_ "GenSigSendType" SG_ 1364 ICC_RISD_Pixel121_OnOff 5;
BA_ "GenSigSendType" SG_ 1364 ICC_RISD_Pixel120_OnOff 5;
BA_ "GenSigSendType" SG_ 1364 ICC_RISD_Pixel119_OnOff 5;
BA_ "GenSigSendType" SG_ 1364 ICC_RISD_Pixel118_OnOff 5;
BA_ "GenSigSendType" SG_ 1364 ICC_RISD_Pixel117_OnOff 5;
BA_ "GenSigSendType" SG_ 1364 ICC_RISD_Pixel116_OnOff 5;
BA_ "GenSigSendType" SG_ 1364 ICC_RISD_Pixel115_OnOff 5;
BA_ "GenSigSendType" SG_ 1364 ICC_RISD_Pixel114_OnOff 5;
BA_ "GenSigSendType" SG_ 1364 ICC_RISD_Pixel113_OnOff 5;
BA_ "GenSigSendType" SG_ 1364 ICC_RISD_Pixel112_OnOff 5;
BA_ "GenSigSendType" SG_ 1364 ICC_RISD_Pixel111_OnOff 5;
BA_ "GenSigSendType" SG_ 1364 ICC_RISD_Pixel110_OnOff 5;
BA_ "GenSigSendType" SG_ 1364 ICC_RISD_Pixel109_OnOff 5;
BA_ "GenSigSendType" SG_ 1364 ICC_RISD_Pixel108_OnOff 5;
BA_ "GenSigSendType" SG_ 1364 ICC_RISD_Pixel107_OnOff 5;
BA_ "GenSigSendType" SG_ 1364 ICC_RISD_Pixel106_OnOff 5;
BA_ "GenSigSendType" SG_ 1364 ICC_RISD_Pixel105_OnOff 5;
BA_ "GenSigSendType" SG_ 1364 ICC_RISD_Pixel104_OnOff 5;
BA_ "GenSigSendType" SG_ 1364 ICC_RISD_Pixel103_OnOff 5;
BA_ "GenSigSendType" SG_ 1364 ICC_RISD_Pixel102_OnOff 5;
BA_ "GenSigSendType" SG_ 1364 ICC_RISD_Pixel101_OnOff 5;
BA_ "GenSigSendType" SG_ 1364 ICC_RISD_Pixel100_OnOff 5;
BA_ "GenSigSendType" SG_ 1364 ICC_RISD_Pixel99_OnOff 5;
BA_ "GenSigSendType" SG_ 1364 ICC_RISD_Pixel98_OnOff 5;
BA_ "GenSigSendType" SG_ 1364 ICC_RISD_Pixel97_OnOff 5;
BA_ "GenSigSendType" SG_ 1364 ICC_RISD_Pixel96_OnOff 5;
BA_ "GenSigSendType" SG_ 1364 ICC_RISD_Pixel95_OnOff 5;
BA_ "GenSigSendType" SG_ 1364 ICC_RISD_Pixel94_OnOff 5;
BA_ "GenSigSendType" SG_ 1364 ICC_RISD_Pixel93_OnOff 5;
BA_ "GenSigSendType" SG_ 1364 ICC_RISD_Pixel92_OnOff 5;
BA_ "GenSigSendType" SG_ 1364 ICC_RISD_Pixel91_OnOff 5;
BA_ "GenSigSendType" SG_ 1364 ICC_RISD_Pixel90_OnOff 5;
BA_ "GenSigSendType" SG_ 1364 ICC_RISD_Pixel89_OnOff 5;
BA_ "GenSigSendType" SG_ 1364 ICC_RISD_Pixel88_OnOff 5;
BA_ "GenSigSendType" SG_ 1364 ICC_RISD_Pixel87_OnOff 5;
BA_ "GenSigSendType" SG_ 1364 ICC_RISD_Pixel86_OnOff 5;
BA_ "GenSigSendType" SG_ 1364 ICC_RISD_Pixel85_OnOff 5;
BA_ "GenSigSendType" SG_ 1364 ICC_RISD_Pixel84_OnOff 5;
BA_ "GenSigSendType" SG_ 1364 ICC_RISD_Pixel83_OnOff 5;
BA_ "GenSigSendType" SG_ 1364 ICC_RISD_Pixel82_OnOff 5;
BA_ "GenSigSendType" SG_ 1364 ICC_RISD_Pixel81_OnOff 5;
BA_ "GenSigSendType" SG_ 1364 ICC_RISD_Pixel80_OnOff 5;
BA_ "GenSigSendType" SG_ 1364 ICC_RISD_Pixel79_OnOff 5;
BA_ "GenSigSendType" SG_ 1364 ICC_RISD_Pixel78_OnOff 5;
BA_ "GenSigSendType" SG_ 1364 ICC_RISD_Pixel77_OnOff 5;
BA_ "GenSigSendType" SG_ 1364 ICC_RISD_Pixel76_OnOff 5;
BA_ "GenSigSendType" SG_ 1364 ICC_RISD_Pixel75_OnOff 5;
BA_ "GenSigSendType" SG_ 1364 ICC_RISD_Pixel74_OnOff 5;
BA_ "GenSigSendType" SG_ 1364 ICC_RISD_Pixel73_OnOff 5;
BA_ "GenSigSendType" SG_ 1364 ICC_RISD_Pixel72_OnOff 5;
BA_ "GenSigSendType" SG_ 1364 ICC_RISD_Pixel71_OnOff 5;
BA_ "GenSigSendType" SG_ 1364 ICC_RISD_Pixel70_OnOff 5;
BA_ "GenSigSendType" SG_ 1364 ICC_RISD_Pixel69_OnOff 5;
BA_ "GenSigSendType" SG_ 1364 ICC_RISD_Pixel68_OnOff 5;
BA_ "GenSigSendType" SG_ 1364 ICC_RISD_Pixel67_OnOff 5;
BA_ "GenSigSendType" SG_ 1364 ICC_RISD_Pixel66_OnOff 5;
BA_ "GenSigSendType" SG_ 1364 ICC_RISD_Pixel65_OnOff 5;
BA_ "GenSigSendType" SG_ 1364 ICC_RISD_Pixel64_OnOff 5;
BA_ "GenSigSendType" SG_ 1364 ICC_RISD_Pixel63_OnOff 5;
BA_ "GenSigSendType" SG_ 1364 ICC_RISD_Pixel62_OnOff 5;
BA_ "GenSigSendType" SG_ 1364 ICC_RISD_Pixel61_OnOff 5;
BA_ "GenSigSendType" SG_ 1364 ICC_RISD_Pixel60_OnOff 5;
BA_ "GenSigSendType" SG_ 1364 ICC_RISD_Pixel59_OnOff 5;
BA_ "GenSigSendType" SG_ 1364 ICC_RISD_Pixel58_OnOff 5;
BA_ "GenSigSendType" SG_ 1364 ICC_RISD_Pixel57_OnOff 5;
BA_ "GenSigSendType" SG_ 1364 ICC_RISD_Pixel56_OnOff 5;
BA_ "GenSigSendType" SG_ 1364 ICC_RISD_Pixel55_OnOff 5;
BA_ "GenSigSendType" SG_ 1364 ICC_RISD_Pixel54_OnOff 5;
BA_ "GenSigSendType" SG_ 1364 ICC_RISD_Pixel53_OnOff 5;
BA_ "GenSigSendType" SG_ 1364 ICC_RISD_Pixel52_OnOff 5;
BA_ "GenSigSendType" SG_ 1364 ICC_RISD_Pixel51_OnOff 5;
BA_ "GenSigSendType" SG_ 1364 ICC_RISD_Pixel50_OnOff 5;
BA_ "GenSigSendType" SG_ 1364 ICC_RISD_Pixel49_OnOff 5;
BA_ "GenSigSendType" SG_ 1364 ICC_RISD_Pixel48_OnOff 5;
BA_ "GenSigSendType" SG_ 1364 ICC_RISD_Pixel47_OnOff 5;
BA_ "GenSigSendType" SG_ 1364 ICC_RISD_Pixel46_OnOff 5;
BA_ "GenSigSendType" SG_ 1364 ICC_RISD_Pixel45_OnOff 5;
BA_ "GenSigSendType" SG_ 1364 ICC_RISD_Pixel44_OnOff 5;
BA_ "GenSigSendType" SG_ 1364 ICC_RISD_Pixel43_OnOff 5;
BA_ "GenSigSendType" SG_ 1364 ICC_RISD_Pixel42_OnOff 5;
BA_ "GenSigSendType" SG_ 1364 ICC_RISD_Pixel41_OnOff 5;
BA_ "GenSigSendType" SG_ 1364 ICC_RISD_Pixel40_OnOff 5;
BA_ "GenSigSendType" SG_ 1364 ICC_RISD_Pixel39_OnOff 5;
BA_ "GenSigSendType" SG_ 1364 ICC_RISD_Pixel38_OnOff 5;
BA_ "GenSigSendType" SG_ 1364 ICC_RISD_Pixel37_OnOff 5;
BA_ "GenSigSendType" SG_ 1364 ICC_RISD_Pixel36_OnOff 5;
BA_ "GenSigSendType" SG_ 1364 ICC_RISD_Pixel35_OnOff 5;
BA_ "GenSigSendType" SG_ 1364 ICC_RISD_Pixel34_OnOff 5;
BA_ "GenSigSendType" SG_ 1364 ICC_RISD_Pixel33_OnOff 5;
BA_ "GenSigSendType" SG_ 1364 ICC_RISD_Pixel32_OnOff 5;
BA_ "GenSigSendType" SG_ 1364 ICC_RISD_Pixel31_OnOff 5;
BA_ "GenSigSendType" SG_ 1364 ICC_RISD_Pixel30_OnOff 5;
BA_ "GenSigSendType" SG_ 1364 ICC_RISD_Pixel29_OnOff 5;
BA_ "GenSigSendType" SG_ 1364 ICC_RISD_Pixel28_OnOff 5;
BA_ "GenSigSendType" SG_ 1364 ICC_RISD_Pixel27_OnOff 5;
BA_ "GenSigSendType" SG_ 1364 ICC_RISD_Pixel26_OnOff 5;
BA_ "GenSigSendType" SG_ 1364 ICC_RISD_Pixel25_OnOff 5;
BA_ "GenSigSendType" SG_ 1364 ICC_RISD_Pixel24_OnOff 5;
BA_ "GenSigSendType" SG_ 1364 ICC_RISD_Pixel23_OnOff 5;
BA_ "GenSigSendType" SG_ 1364 ICC_RISD_Pixel22_OnOff 5;
BA_ "GenSigSendType" SG_ 1364 ICC_RISD_Pixel21_OnOff 5;
BA_ "GenSigSendType" SG_ 1364 ICC_RISD_Pixel20_OnOff 5;
BA_ "GenSigSendType" SG_ 1364 ICC_RISD_Pixel19_OnOff 5;
BA_ "GenSigSendType" SG_ 1364 ICC_RISD_Pixel18_OnOff 5;
BA_ "GenSigSendType" SG_ 1364 ICC_RISD_Pixel17_OnOff 5;
BA_ "GenSigSendType" SG_ 1364 ICC_RISD_Pixel16_OnOff 5;
BA_ "GenSigSendType" SG_ 1364 ICC_RISD_Pixel15_OnOff 5;
BA_ "GenSigSendType" SG_ 1364 ICC_RISD_Pixel14_OnOff 5;
BA_ "GenSigSendType" SG_ 1364 ICC_RISD_Pixel13_OnOff 5;
BA_ "GenSigSendType" SG_ 1364 ICC_RISD_Pixel12_OnOff 5;
BA_ "GenSigSendType" SG_ 1364 ICC_RISD_Pixel11_OnOff 5;
BA_ "GenSigSendType" SG_ 1364 ICC_RISD_Pixel10_OnOff 5;
BA_ "GenSigSendType" SG_ 1364 ICC_RISD_Pixel9_OnOff 5;
BA_ "GenSigSendType" SG_ 1364 ICC_RISD_Pixel8_OnOff 5;
BA_ "GenSigSendType" SG_ 1364 ICC_RISD_Pixel7_OnOff 5;
BA_ "GenSigSendType" SG_ 1364 ICC_RISD_Pixel6_OnOff 5;
BA_ "GenSigSendType" SG_ 1364 ICC_RISD_Pixel5_OnOff 5;
BA_ "GenSigSendType" SG_ 1364 ICC_RISD_Pixel4_OnOff 5;
BA_ "GenSigSendType" SG_ 1364 ICC_RISD_Pixel3_OnOff 5;
BA_ "GenSigSendType" SG_ 1364 ICC_RISD_Pixel2_OnOff 5;
BA_ "GenSigSendType" SG_ 1364 ICC_RISD_Pixel1_OnOff 5;
BA_ "GenSigSendType" SG_ 1364 ICC_RISD_RollingCounter 5;
BA_ "GenSigSendType" SG_ 1364 ICC_RISD_FrameCounter 5;
BA_ "GenSigSendType" SG_ 1345 DVR_1_Sdcard_Sts 5;
BA_ "GenSigSendType" SG_ 1345 DVR_1_DVRFailReasons 5;
BA_ "GenSigSendType" SG_ 1345 DVR_1_RecordSts 5;
BA_ "GenSigSendType" SG_ 1121 STAT_AMPNaviVolume 0;
BA_ "GenSigSendType" SG_ 1121 STAT_AMPVRVolume 0;
BA_ "GenSigSendType" SG_ 1121 STAT_AMPKeyTone 0;
BA_ "GenSigSendType" SG_ 1121 STAT_AMPMediaVolume 0;
BA_ "GenSigSendType" SG_ 1121 STAT_AMPPhoneVolume 0;
BA_ "GenSigSendType" SG_ 1121 STAT_AMPSoundFocus 0;
BA_ "GenSigSendType" SG_ 1121 STAT_AMPSoundEffect 0;
BA_ "GenSigSendType" SG_ 1121 STAT_AMPSoundEffectBass 0;
BA_ "GenSigSendType" SG_ 1121 STAT_AMPSoundEffectMidrange 0;
BA_ "GenSigSendType" SG_ 1121 STAT_AMPSoundEffectTreble 0;
BA_ "GenSigSendType" SG_ 1121 STAT_AMPSoundFieldBalance 0;
BA_ "GenSigSendType" SG_ 1121 STAT_AMPSoundFieldFader 0;
BA_ "GenSigSendType" SG_ 1121 STAT_REQ_AMPA2BMediaSound 0;
BA_ "GenSigSendType" SG_ 1121 STAT_REQ_AMPA2BNaviSound 0;
BA_ "GenSigSendType" SG_ 1121 STAT_REQ_AMPA2BVRSound 0;
BA_ "GenSigSendType" SG_ 1121 STAT_REQ_AMPA2BTTSSound 0;
BA_ "GenSigSendType" SG_ 1121 STAT_REQ_AMPA2BPhoneSound 0;
BA_ "GenSigSendType" SG_ 1121 STAT_REQ_AMPAlarm 0;
BA_ "GenSigSendType" SG_ 1140 STAT_AMPMediaDuck 0;
BA_ "GenSigSendType" SG_ 1140 STAT_AMPSpeedVolume 0;
BA_ "GenSigSendType" SG_ 1140 STAT_AMPMute 0;
BA_ "GenSigSendType" SG_ 1140 STAT_AMPRestoreDefaults 0;
BA_ "GenSigSendType" SG_ 1140 STAT_AMPAlarmVolume 0;
BA_ "GenSigSendType" SG_ 1140 STAT_Headrest_Mode 0;
BA_ "GenSigSendType" SG_ 1140 STAT_AMPSoundEffectMegaBass 0;
BA_ "GenSigSendType" SG_ 1140 STAT_AMPSoundEffectMidBass 0;
BA_ "GenSigSendType" SG_ 1140 STAT_AMPSoundEffectMidTreble 0;
BA_ "GenSigSendType" SG_ 1140 STAT_VirtualSbwfrOnOff 0;
BA_ "GenSigSendType" SG_ 1140 STAT_SurndFnOnOff 0;
BA_ "GenSigSendType" SG_ 1140 STAT_AMPBackgroundVolume 0;
BA_ "GenSigSendType" SG_ 1140 STAT_AMPSoundBypass 0;
BA_ "GenSigSendType" SG_ 1140 STAT_AMPPwrRdySts 0;
BA_ "GenSigSendType" SG_ 1140 STAT_AMPVersion 0;
BA_ "GenSigSendType" SG_ 1206 EAMP_AMPKTVvoiceVolumeFed 0;
BA_ "GenSigSendType" SG_ 1206 EAMP_AMPENCVolumeFed 0;
BA_ "GenSigSendType" SG_ 1206 EAMP_AMPA2BKTVvoiceSoundFed 0;
BA_ "GenSigSendType" SG_ 1206 STAT_AMPSoundFocus_2 0;
BA_ "GenSigSendType" SG_ 1206 EAMP_AMPA2BENCSoundFed 0;
BA_ "GenSigSendType" SG_ 1206 EAMP_AMPA2BChimeSoundFed 0;
BA_ "GenSigSendType" SG_ 1206 STAT_AMPLoudness 0;
BA_ "GenSigSendType" SG_ 1206 STAT_AMPKeyVolume 0;
BA_ "GenSigSendType" SG_ 1206 STAT_AMPExSoundmode 0;
BA_ "GenSigSendType" SG_ 1206 STAT_AMPA2BENCSound 0;
BA_ "GenSigSendType" SG_ 1078 PLG_LatchSts 0;
BA_ "GenSigInvalidValue" SG_ 1078 PLG_LatchSts 3;
BA_ "GenSigStartValue" SG_ 1078 PLG_LatchSts 2;
BA_ "GenSigInvalidValue" SG_ 1252 TotalOdometer_km_OBD 16777215;
BA_ "GenSigSendType" SG_ 1252 TotalOdometer_km_OBD 0;
BA_ "GenSigSendType" SG_ 1252 DisplayVehicleSpeed 0;
BA_ "GenSigSendType" SG_ 1252 ICC_BackLightLevel 0;
BA_ "GenSigSendType" SG_ 1252 TotalOdometer_km_OBDValidData 0;
BA_ "GenSigSendType" SG_ 1252 ICC_TotalodometerbackupEnable 0;
BA_ "GenSigSendType" SG_ 1322 STAT_AMPAlarm 2;
BA_ "GenSigSendType" SG_ 1176 Fusa_498_6 4;
BA_ "GenSigSendType" SG_ 1176 Fusa_498_5 4;
BA_ "GenSigSendType" SG_ 1176 Fusa_498_4 4;
BA_ "GenSigSendType" SG_ 1176 Fusa_498_3 4;
BA_ "GenSigSendType" SG_ 1176 Fusa_498_2 4;
BA_ "GenSigSendType" SG_ 1176 Fusa_498_1 4;
BA_ "GenSigSendType" SG_ 1176 ICC_CH_3_CRC 5;
BA_ "E2EDataId" SG_ 1176 ICC_CH_3_CRC 72;
BA_ "E2EProfile" SG_ 1176 ICC_CH_3_CRC "P01";
BA_ "E2EDataLength" SG_ 1176 ICC_CH_3_CRC 64;
BA_ "GenSigSendType" SG_ 1176 ICC_CH_3_RollgCntr 5;
BA_ "E2EDataId" SG_ 1176 ICC_CH_3_RollgCntr 72;
BA_ "E2EProfile" SG_ 1176 ICC_CH_3_RollgCntr "P01";
BA_ "E2EDataLength" SG_ 1176 ICC_CH_3_RollgCntr 64;
BA_ "GenSigSendType" SG_ 1176 ICC_ASUAssistPassSet 4;
BA_ "E2EDataId" SG_ 1176 ICC_ASUAssistPassSet 72;
BA_ "E2EProfile" SG_ 1176 ICC_ASUAssistPassSet "P01";
BA_ "E2EDataLength" SG_ 1176 ICC_ASUAssistPassSet 64;
BA_ "GenSigSendType" SG_ 1176 IHU_AutHldSet 4;
BA_ "E2EDataId" SG_ 1176 IHU_AutHldSet 72;
BA_ "E2EProfile" SG_ 1176 IHU_AutHldSet "P01";
BA_ "E2EDataLength" SG_ 1176 IHU_AutHldSet 64;
BA_ "GenSigSendType" SG_ 1176 ICC_AutoEasyEntrySet 4;
BA_ "E2EDataId" SG_ 1176 ICC_AutoEasyEntrySet 72;
BA_ "E2EProfile" SG_ 1176 ICC_AutoEasyEntrySet "P01";
BA_ "E2EDataLength" SG_ 1176 ICC_AutoEasyEntrySet 64;
BA_ "GenSigSendType" SG_ 1176 ICC_ManualEasyOutSw 4;
BA_ "E2EDataId" SG_ 1176 ICC_ManualEasyOutSw 72;
BA_ "E2EProfile" SG_ 1176 ICC_ManualEasyOutSw "P01";
BA_ "E2EDataLength" SG_ 1176 ICC_ManualEasyOutSw 64;
BA_ "GenSigSendType" SG_ 1176 ICC_ASCMaintainModeReq 4;
BA_ "E2EDataId" SG_ 1176 ICC_ASCMaintainModeReq 72;
BA_ "E2EProfile" SG_ 1176 ICC_ASCMaintainModeReq "P01";
BA_ "E2EDataLength" SG_ 1176 ICC_ASCMaintainModeReq 64;
BA_ "GenSigSendType" SG_ 1176 ICC_PABSetCmd 4;
BA_ "E2EDataId" SG_ 1176 ICC_PABSetCmd 72;
BA_ "E2EProfile" SG_ 1176 ICC_PABSetCmd "P01";
BA_ "E2EDataLength" SG_ 1176 ICC_PABSetCmd 64;
BA_ "GenSigSendType" SG_ 1176 ICC_EPBSetCmd 4;
BA_ "E2EDataId" SG_ 1176 ICC_EPBSetCmd 72;
BA_ "E2EProfile" SG_ 1176 ICC_EPBSetCmd "P01";
BA_ "E2EDataLength" SG_ 1176 ICC_EPBSetCmd 64;
BA_ "GenSigSendType" SG_ 1176 ICC_ASUMemoryPosition 4;
BA_ "E2EDataId" SG_ 1176 ICC_ASUMemoryPosition 72;
BA_ "E2EProfile" SG_ 1176 ICC_ASUMemoryPosition "P01";
BA_ "E2EDataLength" SG_ 1176 ICC_ASUMemoryPosition 64;
BA_ "GenSigSendType" SG_ 1176 ICC_ASUEasyLoadingSet 4;
BA_ "E2EDataId" SG_ 1176 ICC_ASUEasyLoadingSet 72;
BA_ "E2EProfile" SG_ 1176 ICC_ASUEasyLoadingSet "P01";
BA_ "E2EDataLength" SG_ 1176 ICC_ASUEasyLoadingSet 64;
BA_ "GenSigSendType" SG_ 1176 Set_CSTFunctionSts 4;
BA_ "E2EDataId" SG_ 1176 Set_CSTFunctionSts 72;
BA_ "E2EProfile" SG_ 1176 Set_CSTFunctionSts "P01";
BA_ "E2EDataLength" SG_ 1176 Set_CSTFunctionSts 64;
BA_ "GenSigSendType" SG_ 1176 ICC_ASURearaxlewithTaildoor 4;
BA_ "E2EDataId" SG_ 1176 ICC_ASURearaxlewithTaildoor 72;
BA_ "E2EProfile" SG_ 1176 ICC_ASURearaxlewithTaildoor "P01";
BA_ "E2EDataLength" SG_ 1176 ICC_ASURearaxlewithTaildoor 64;
BA_ "GenSigSendType" SG_ 1176 CST_SensitivityReq 4;
BA_ "E2EDataId" SG_ 1176 CST_SensitivityReq 72;
BA_ "E2EProfile" SG_ 1176 CST_SensitivityReq "P01";
BA_ "E2EDataLength" SG_ 1176 CST_SensitivityReq 64;
BA_ "GenSigSendType" SG_ 1176 TIHU_SetHDCOnOff 4;
BA_ "E2EDataId" SG_ 1176 TIHU_SetHDCOnOff 72;
BA_ "E2EProfile" SG_ 1176 TIHU_SetHDCOnOff "P01";
BA_ "E2EDataLength" SG_ 1176 TIHU_SetHDCOnOff 64;
BA_ "GenSigSendType" SG_ 1176 Set_ESPFunctionSts 4;
BA_ "E2EDataId" SG_ 1176 Set_ESPFunctionSts 72;
BA_ "E2EProfile" SG_ 1176 Set_ESPFunctionSts "P01";
BA_ "E2EDataLength" SG_ 1176 Set_ESPFunctionSts 64;
BA_ "GenSigSendType" SG_ 1176 ICC_ASUPreviewCont 4;
BA_ "E2EDataId" SG_ 1176 ICC_ASUPreviewCont 72;
BA_ "E2EProfile" SG_ 1176 ICC_ASUPreviewCont "P01";
BA_ "E2EDataLength" SG_ 1176 ICC_ASUPreviewCont 64;
BA_ "GenSigSendType" SG_ 1176 ICC_ASUHighwayModAdjust 4;
BA_ "E2EDataId" SG_ 1176 ICC_ASUHighwayModAdjust 72;
BA_ "E2EProfile" SG_ 1176 ICC_ASUHighwayModAdjust "P01";
BA_ "E2EDataLength" SG_ 1176 ICC_ASUHighwayModAdjust 64;
BA_ "GenSigSendType" SG_ 1176 ICC_ASUMapAdjust 4;
BA_ "E2EDataId" SG_ 1176 ICC_ASUMapAdjust 72;
BA_ "E2EProfile" SG_ 1176 ICC_ASUMapAdjust "P01";
BA_ "E2EDataLength" SG_ 1176 ICC_ASUMapAdjust 64;
BA_ "GenSigSendType" SG_ 1239 ICC_DisChg 5;
BA_ "GenSigSendType" SG_ 1239 ICC_StpDisChgReq 0;
BA_ "GenSigSendType" SG_ 1239 ICC_RegenLevel 5;
BA_ "GenSigSendType" SG_ 1239 ICC_ELockReq 0;
BA_ "GenSigSendType" SG_ 1239 ICC_DisChgPercent 0;
BA_ "GenSigInvalidValue" SG_ 1239 ICC_DisChgPercent 127;
BA_ "GenSigSendType" SG_ 1239 ICC_ChgSocSet 5;
BA_ "GenSigInvalidValue" SG_ 1239 ICC_ChgSocSet 255;
BA_ "GenSigStartValue" SG_ 1239 ICC_ChgSocSet 255;
BA_ "GenSigSendType" SG_ 1239 ICC_CampMode 5;
BA_ "GenSigSendType" SG_ 1239 ICC_SftWarning 5;
BA_ "GenSigSendType" SG_ 1239 ICC_TowingMode 5;
BA_ "GenSigSendType" SG_ 1239 ICC_StopMode 5;
BA_ "GenSigSendType" SG_ 1239 ICC_EPedalMode 5;
BA_ "GenSigSendType" SG_ 1246 ICC_WindowKeySts 5;
BA_ "GenSigSendType" SG_ 1246 ICC_FaceKeySts 5;
BA_ "GenSigSendType" SG_ 1246 ICC_FootKeySts 5;
BA_ "GenSigSendType" SG_ 1246 BltCallSts 5;
BA_ "GenSigSendType" SG_ 1246 ICC_DockWinspSts 5;
BA_ "GenSigSendType" SG_ 1246 ICC_DockTSts 5;
BA_ "GenSigSendType" SG_ 1246 ICC_ACFastCool 5;
BA_ "GenSigSendType" SG_ 1246 ICC_ACFastHeat 5;
BA_ "GenSigSendType" SG_ 1246 ICC_SetCLMOn 5;
BA_ "GenSigSendType" SG_ 1246 ICC_SetAutoKeySts 5;
BA_ "GenSigSendType" SG_ 1246 ICC_SetFrontDeforestSts 5;
BA_ "GenSigSendType" SG_ 1246 ICC_SetCirculationModeKeySts 5;
BA_ "GenSigSendType" SG_ 1246 ICC_ZoneSelectionKeySts 5;
BA_ "GenSigSendType" SG_ 1246 ICC_ResetFilter 5;
BA_ "GenSigSendType" SG_ 1246 ICC_AUTODefrostOnKeySts 5;
BA_ "GenSigSendType" SG_ 1246 ICC_AutoAirClean 5;
BA_ "GenSigSendType" SG_ 1246 ICC_KeepWarm 0;
BA_ "GenSigSendType" SG_ 1246 ICC_BlowSpeedLevelKeySts 4;
BA_ "GenSigSendType" SG_ 1246 ICC_SetACRequestKeySts 5;
BA_ "GenSigSendType" SG_ 1246 ICC_DSwingSet 5;
BA_ "GenSigSendType" SG_ 1246 ICC_PSwingSet 5;
BA_ "GenSigSendType" SG_ 1246 ICC_AUTODefLevelSet 5;
BA_ "GenSigSendType" SG_ 1246 ICC_SetTemperature_L_C 5;
BA_ "GenSigInvalidValue" SG_ 1246 ICC_SetTemperature_L_C 31;
BA_ "GenSigStartValue" SG_ 1246 ICC_SetTemperature_L_C 31;
BA_ "GenSigSendType" SG_ 1246 ICC_SetTemperature_R_C 5;
BA_ "GenSigInvalidValue" SG_ 1246 ICC_SetTemperature_R_C 31;
BA_ "GenSigStartValue" SG_ 1246 ICC_SetTemperature_R_C 31;
BA_ "GenSigSendType" SG_ 1246 ICC_DLSwingUpDwn 5;
BA_ "GenSigInvalidValue" SG_ 1246 ICC_DLSwingUpDwn 127;
BA_ "GenSigSendType" SG_ 1246 ICC_DLSwingLeRi 5;
BA_ "GenSigInvalidValue" SG_ 1246 ICC_DLSwingLeRi 127;
BA_ "GenSigSendType" SG_ 1246 ICC_DRSwingUpDwn 5;
BA_ "GenSigInvalidValue" SG_ 1246 ICC_DRSwingUpDwn 127;
BA_ "GenSigSendType" SG_ 1246 ICC_DRSwingLeRi 5;
BA_ "GenSigInvalidValue" SG_ 1246 ICC_DRSwingLeRi 127;
BA_ "GenSigSendType" SG_ 1246 ICC_PLSwingUpDwn 5;
BA_ "GenSigInvalidValue" SG_ 1246 ICC_PLSwingUpDwn 127;
BA_ "GenSigSendType" SG_ 1246 ICC_PLSwingLeRi 5;
BA_ "GenSigInvalidValue" SG_ 1246 ICC_PLSwingLeRi 127;
BA_ "GenSigSendType" SG_ 1246 ICC_PRSwingUpDwn 5;
BA_ "GenSigInvalidValue" SG_ 1246 ICC_PRSwingUpDwn 127;
BA_ "GenSigSendType" SG_ 1246 ICC_PRSwingLeRi 5;
BA_ "GenSigInvalidValue" SG_ 1246 ICC_PRSwingLeRi 127;
BA_ "GenSigSendType" SG_ 1246 ICC_DCSwingLeRi 5;
BA_ "GenSigInvalidValue" SG_ 1246 ICC_DCSwingLeRi 127;
BA_ "GenSigSendType" SG_ 1246 ICC_NetWorkTemperature 0;
BA_ "GenSigInvalidValue" SG_ 1246 ICC_NetWorkTemperature 255;
BA_ "GenSigStartValue" SG_ 1246 ICC_NetWorkTemperature 254;
BA_ "GenSigSendType" SG_ 1246 ICC_NetWorkHumidity 0;
BA_ "GenSigInvalidValue" SG_ 1246 ICC_NetWorkHumidity 255;
BA_ "GenSigStartValue" SG_ 1246 ICC_NetWorkHumidity 1;
BA_ "GenSigSendType" SG_ 1246 ICC_DLOnOff 5;
BA_ "GenSigSendType" SG_ 1246 ICC_DROnOff 5;
BA_ "GenSigSendType" SG_ 1246 ICC_PLOnOff 5;
BA_ "GenSigSendType" SG_ 1246 ICC_PROnOff 5;
BA_ "GenSigSendType" SG_ 1246 ICC_DCOnOff 5;
BA_ "GenSigSendType" SG_ 1246 ICC_LoveRemind 5;
BA_ "GenSigSendType" SG_ 1246 ICC_InteCleanCar 5;
BA_ "GenSigSendType" SG_ 1246 ICC_KeepWarmMemory 5;
BA_ "GenSigSendType" SG_ 1250 ICC_CCMSet 5;
BA_ "GenSigSendType" SG_ 1250 ICC_AutoLightSW 0;
BA_ "GenSigSendType" SG_ 1250 ICC_CleanMode 5;
BA_ "GenSigSendType" SG_ 1250 ICC_1_OTASts 0;
BA_ "GenSigSendType" SG_ 1250 ICC_1_OTAHV_Req 0;
BA_ "GenSigSendType" SG_ 1250 ICC_1_OTAPwrMngt 0;
BA_ "GenSigSendType" SG_ 1250 ICC_DriveModeSwitch 5;
BA_ "GenSigSendType" SG_ 1250 ICC_PropulsionMode 5;
BA_ "GenSigSendType" SG_ 1250 ICC_SteeringMode 5;
BA_ "GenSigSendType" SG_ 1250 ICC_SuspensionHeight 5;
BA_ "GenSigSendType" SG_ 1250 ICC_SuspensionDamping 5;
BA_ "GenSigSendType" SG_ 1250 ICC_AirconditionMode 5;
BA_ "GenSigSendType" SG_ 1250 ICC_BrakePedalFeelMode 5;
BA_ "GenSigSendType" SG_ 1250 ICC_SentinelHV_Req 0;
BA_ "GenSigSendType" SG_ 1250 ICC_PetModeHV_Req 0;
BA_ "GenSigSendType" SG_ 1250 ICC_SelfClearing 5;
VAL_ 1364 ICC_RISD_Pixel504_OnOff 0 "Pixel On" 1 "Pixel Off" ;
VAL_ 1364 ICC_RISD_Pixel503_OnOff 0 "Pixel On" 1 "Pixel Off" ;
VAL_ 1364 ICC_RISD_Pixel502_OnOff 0 "Pixel On" 1 "Pixel Off" ;
VAL_ 1364 ICC_RISD_Pixel501_OnOff 0 "Pixel On" 1 "Pixel Off" ;
VAL_ 1364 ICC_RISD_Pixel500_OnOff 0 "Pixel On" 1 "Pixel Off" ;
VAL_ 1364 ICC_RISD_Pixel499_OnOff 0 "Pixel On" 1 "Pixel Off" ;
VAL_ 1364 ICC_RISD_Pixel498_OnOff 0 "Pixel On" 1 "Pixel Off" ;
VAL_ 1364 ICC_RISD_Pixel497_OnOff 0 "Pixel On" 1 "Pixel Off" ;
VAL_ 1364 ICC_RISD_Pixel496_OnOff 0 "Pixel On" 1 "Pixel Off" ;
VAL_ 1364 ICC_RISD_Pixel495_OnOff 0 "Pixel On" 1 "Pixel Off" ;
VAL_ 1364 ICC_RISD_Pixel494_OnOff 0 "Pixel On" 1 "Pixel Off" ;
VAL_ 1364 ICC_RISD_Pixel493_OnOff 0 "Pixel On" 1 "Pixel Off" ;
VAL_ 1364 ICC_RISD_Pixel492_OnOff 0 "Pixel On" 1 "Pixel Off" ;
VAL_ 1364 ICC_RISD_Pixel491_OnOff 0 "Pixel On" 1 "Pixel Off" ;
VAL_ 1364 ICC_RISD_Pixel490_OnOff 0 "Pixel On" 1 "Pixel Off" ;
VAL_ 1364 ICC_RISD_Pixel489_OnOff 0 "Pixel On" 1 "Pixel Off" ;
VAL_ 1364 ICC_RISD_Pixel488_OnOff 0 "Pixel On" 1 "Pixel Off" ;
VAL_ 1364 ICC_RISD_Pixel487_OnOff 0 "Pixel On" 1 "Pixel Off" ;
VAL_ 1364 ICC_RISD_Pixel486_OnOff 0 "Pixel On" 1 "Pixel Off" ;
VAL_ 1364 ICC_RISD_Pixel485_OnOff 0 "Pixel On" 1 "Pixel Off" ;
VAL_ 1364 ICC_RISD_Pixel484_OnOff 0 "Pixel On" 1 "Pixel Off" ;
VAL_ 1364 ICC_RISD_Pixel483_OnOff 0 "Pixel On" 1 "Pixel Off" ;
VAL_ 1364 ICC_RISD_Pixel482_OnOff 0 "Pixel On" 1 "Pixel Off" ;
VAL_ 1364 ICC_RISD_Pixel481_OnOff 0 "Pixel On" 1 "Pixel Off" ;
VAL_ 1364 ICC_RISD_Pixel480_OnOff 0 "Pixel On" 1 "Pixel Off" ;
VAL_ 1364 ICC_RISD_Pixel479_OnOff 0 "Pixel On" 1 "Pixel Off" ;
VAL_ 1364 ICC_RISD_Pixel478_OnOff 0 "Pixel On" 1 "Pixel Off" ;
VAL_ 1364 ICC_RISD_Pixel477_OnOff 0 "Pixel On" 1 "Pixel Off" ;
VAL_ 1364 ICC_RISD_Pixel476_OnOff 0 "Pixel On" 1 "Pixel Off" ;
VAL_ 1364 ICC_RISD_Pixel475_OnOff 0 "Pixel On" 1 "Pixel Off" ;
VAL_ 1364 ICC_RISD_Pixel474_OnOff 0 "Pixel On" 1 "Pixel Off" ;
VAL_ 1364 ICC_RISD_Pixel473_OnOff 0 "Pixel On" 1 "Pixel Off" ;
VAL_ 1364 ICC_RISD_Pixel472_OnOff 0 "Pixel On" 1 "Pixel Off" ;
VAL_ 1364 ICC_RISD_Pixel471_OnOff 0 "Pixel On" 1 "Pixel Off" ;
VAL_ 1364 ICC_RISD_Pixel470_OnOff 0 "Pixel On" 1 "Pixel Off" ;
VAL_ 1364 ICC_RISD_Pixel469_OnOff 0 "Pixel On" 1 "Pixel Off" ;
VAL_ 1364 ICC_RISD_Pixel468_OnOff 0 "Pixel On" 1 "Pixel Off" ;
VAL_ 1364 ICC_RISD_Pixel467_OnOff 0 "Pixel On" 1 "Pixel Off" ;
VAL_ 1364 ICC_RISD_Pixel466_OnOff 0 "Pixel On" 1 "Pixel Off" ;
VAL_ 1364 ICC_RISD_Pixel465_OnOff 0 "Pixel On" 1 "Pixel Off" ;
VAL_ 1364 ICC_RISD_Pixel464_OnOff 0 "Pixel On" 1 "Pixel Off" ;
VAL_ 1364 ICC_RISD_Pixel463_OnOff 0 "Pixel On" 1 "Pixel Off" ;
VAL_ 1364 ICC_RISD_Pixel462_OnOff 0 "Pixel On" 1 "Pixel Off" ;
VAL_ 1364 ICC_RISD_Pixel461_OnOff 0 "Pixel On" 1 "Pixel Off" ;
VAL_ 1364 ICC_RISD_Pixel460_OnOff 0 "Pixel On" 1 "Pixel Off" ;
VAL_ 1364 ICC_RISD_Pixel459_OnOff 0 "Pixel On" 1 "Pixel Off" ;
VAL_ 1364 ICC_RISD_Pixel458_OnOff 0 "Pixel On" 1 "Pixel Off" ;
VAL_ 1364 ICC_RISD_Pixel457_OnOff 0 "Pixel On" 1 "Pixel Off" ;
VAL_ 1364 ICC_RISD_Pixel456_OnOff 0 "Pixel On" 1 "Pixel Off" ;
VAL_ 1364 ICC_RISD_Pixel455_OnOff 0 "Pixel On" 1 "Pixel Off" ;
VAL_ 1364 ICC_RISD_Pixel454_OnOff 0 "Pixel On" 1 "Pixel Off" ;
VAL_ 1364 ICC_RISD_Pixel453_OnOff 0 "Pixel On" 1 "Pixel Off" ;
VAL_ 1364 ICC_RISD_Pixel452_OnOff 0 "Pixel On" 1 "Pixel Off" ;
VAL_ 1364 ICC_RISD_Pixel451_OnOff 0 "Pixel On" 1 "Pixel Off" ;
VAL_ 1364 ICC_RISD_Pixel450_OnOff 0 "Pixel On" 1 "Pixel Off" ;
VAL_ 1364 ICC_RISD_Pixel449_OnOff 0 "Pixel On" 1 "Pixel Off" ;
VAL_ 1364 ICC_RISD_Pixel448_OnOff 0 "Pixel On" 1 "Pixel Off" ;
VAL_ 1364 ICC_RISD_Pixel447_OnOff 0 "Pixel On" 1 "Pixel Off" ;
VAL_ 1364 ICC_RISD_Pixel446_OnOff 0 "Pixel On" 1 "Pixel Off" ;
VAL_ 1364 ICC_RISD_Pixel445_OnOff 0 "Pixel On" 1 "Pixel Off" ;
VAL_ 1364 ICC_RISD_Pixel444_OnOff 0 "Pixel On" 1 "Pixel Off" ;
VAL_ 1364 ICC_RISD_Pixel443_OnOff 0 "Pixel On" 1 "Pixel Off" ;
VAL_ 1364 ICC_RISD_Pixel442_OnOff 0 "Pixel On" 1 "Pixel Off" ;
VAL_ 1364 ICC_RISD_Pixel441_OnOff 0 "Pixel On" 1 "Pixel Off" ;
VAL_ 1364 ICC_RISD_Pixel440_OnOff 0 "Pixel On" 1 "Pixel Off" ;
VAL_ 1364 ICC_RISD_Pixel439_OnOff 0 "Pixel On" 1 "Pixel Off" ;
VAL_ 1364 ICC_RISD_Pixel438_OnOff 0 "Pixel On" 1 "Pixel Off" ;
VAL_ 1364 ICC_RISD_Pixel437_OnOff 0 "Pixel On" 1 "Pixel Off" ;
VAL_ 1364 ICC_RISD_Pixel436_OnOff 0 "Pixel On" 1 "Pixel Off" ;
VAL_ 1364 ICC_RISD_Pixel435_OnOff 0 "Pixel On" 1 "Pixel Off" ;
VAL_ 1364 ICC_RISD_Pixel434_OnOff 0 "Pixel On" 1 "Pixel Off" ;
VAL_ 1364 ICC_RISD_Pixel433_OnOff 0 "Pixel On" 1 "Pixel Off" ;
VAL_ 1364 ICC_RISD_Pixel432_OnOff 0 "Pixel On" 1 "Pixel Off" ;
VAL_ 1364 ICC_RISD_Pixel431_OnOff 0 "Pixel On" 1 "Pixel Off" ;
VAL_ 1364 ICC_RISD_Pixel430_OnOff 0 "Pixel On" 1 "Pixel Off" ;
VAL_ 1364 ICC_RISD_Pixel429_OnOff 0 "Pixel On" 1 "Pixel Off" ;
VAL_ 1364 ICC_RISD_Pixel428_OnOff 0 "Pixel On" 1 "Pixel Off" ;
VAL_ 1364 ICC_RISD_Pixel427_OnOff 0 "Pixel On" 1 "Pixel Off" ;
VAL_ 1364 ICC_RISD_Pixel426_OnOff 0 "Pixel On" 1 "Pixel Off" ;
VAL_ 1364 ICC_RISD_Pixel425_OnOff 0 "Pixel On" 1 "Pixel Off" ;
VAL_ 1364 ICC_RISD_Pixel424_OnOff 0 "Pixel On" 1 "Pixel Off" ;
VAL_ 1364 ICC_RISD_Pixel423_OnOff 0 "Pixel On" 1 "Pixel Off" ;
VAL_ 1364 ICC_RISD_Pixel422_OnOff 0 "Pixel On" 1 "Pixel Off" ;
VAL_ 1364 ICC_RISD_Pixel421_OnOff 0 "Pixel On" 1 "Pixel Off" ;
VAL_ 1364 ICC_RISD_Pixel420_OnOff 0 "Pixel On" 1 "Pixel Off" ;
VAL_ 1364 ICC_RISD_Pixel419_OnOff 0 "Pixel On" 1 "Pixel Off" ;
VAL_ 1364 ICC_RISD_Pixel418_OnOff 0 "Pixel On" 1 "Pixel Off" ;
VAL_ 1364 ICC_RISD_Pixel417_OnOff 0 "Pixel On" 1 "Pixel Off" ;
VAL_ 1364 ICC_RISD_Pixel416_OnOff 0 "Pixel On" 1 "Pixel Off" ;
VAL_ 1364 ICC_RISD_Pixel415_OnOff 0 "Pixel On" 1 "Pixel Off" ;
VAL_ 1364 ICC_RISD_Pixel414_OnOff 0 "Pixel On" 1 "Pixel Off" ;
VAL_ 1364 ICC_RISD_Pixel413_OnOff 0 "Pixel On" 1 "Pixel Off" ;
VAL_ 1364 ICC_RISD_Pixel412_OnOff 0 "Pixel On" 1 "Pixel Off" ;
VAL_ 1364 ICC_RISD_Pixel411_OnOff 0 "Pixel On" 1 "Pixel Off" ;
VAL_ 1364 ICC_RISD_Pixel410_OnOff 0 "Pixel On" 1 "Pixel Off" ;
VAL_ 1364 ICC_RISD_Pixel409_OnOff 0 "Pixel On" 1 "Pixel Off" ;
VAL_ 1364 ICC_RISD_Pixel408_OnOff 0 "Pixel On" 1 "Pixel Off" ;
VAL_ 1364 ICC_RISD_Pixel407_OnOff 0 "Pixel On" 1 "Pixel Off" ;
VAL_ 1364 ICC_RISD_Pixel406_OnOff 0 "Pixel On" 1 "Pixel Off" ;
VAL_ 1364 ICC_RISD_Pixel405_OnOff 0 "Pixel On" 1 "Pixel Off" ;
VAL_ 1364 ICC_RISD_Pixel404_OnOff 0 "Pixel On" 1 "Pixel Off" ;
VAL_ 1364 ICC_RISD_Pixel403_OnOff 0 "Pixel On" 1 "Pixel Off" ;
VAL_ 1364 ICC_RISD_Pixel402_OnOff 0 "Pixel On" 1 "Pixel Off" ;
VAL_ 1364 ICC_RISD_Pixel401_OnOff 0 "Pixel On" 1 "Pixel Off" ;
VAL_ 1364 ICC_RISD_Pixel400_OnOff 0 "Pixel On" 1 "Pixel Off" ;
VAL_ 1364 ICC_RISD_Pixel399_OnOff 0 "Pixel On" 1 "Pixel Off" ;
VAL_ 1364 ICC_RISD_Pixel398_OnOff 0 "Pixel On" 1 "Pixel Off" ;
VAL_ 1364 ICC_RISD_Pixel397_OnOff 0 "Pixel On" 1 "Pixel Off" ;
VAL_ 1364 ICC_RISD_Pixel396_OnOff 0 "Pixel On" 1 "Pixel Off" ;
VAL_ 1364 ICC_RISD_Pixel395_OnOff 0 "Pixel On" 1 "Pixel Off" ;
VAL_ 1364 ICC_RISD_Pixel394_OnOff 0 "Pixel On" 1 "Pixel Off" ;
VAL_ 1364 ICC_RISD_Pixel393_OnOff 0 "Pixel On" 1 "Pixel Off" ;
VAL_ 1364 ICC_RISD_Pixel392_OnOff 0 "Pixel On" 1 "Pixel Off" ;
VAL_ 1364 ICC_RISD_Pixel391_OnOff 0 "Pixel On" 1 "Pixel Off" ;
VAL_ 1364 ICC_RISD_Pixel390_OnOff 0 "Pixel On" 1 "Pixel Off" ;
VAL_ 1364 ICC_RISD_Pixel389_OnOff 0 "Pixel On" 1 "Pixel Off" ;
VAL_ 1364 ICC_RISD_Pixel388_OnOff 0 "Pixel On" 1 "Pixel Off" ;
VAL_ 1364 ICC_RISD_Pixel387_OnOff 0 "Pixel On" 1 "Pixel Off" ;
VAL_ 1364 ICC_RISD_Pixel386_OnOff 0 "Pixel On" 1 "Pixel Off" ;
VAL_ 1364 ICC_RISD_Pixel385_OnOff 0 "Pixel On" 1 "Pixel Off" ;
VAL_ 1364 ICC_RISD_Pixel384_OnOff 0 "Pixel On" 1 "Pixel Off" ;
VAL_ 1364 ICC_RISD_Pixel383_OnOff 0 "Pixel On" 1 "Pixel Off" ;
VAL_ 1364 ICC_RISD_Pixel382_OnOff 0 "Pixel On" 1 "Pixel Off" ;
VAL_ 1364 ICC_RISD_Pixel381_OnOff 0 "Pixel On" 1 "Pixel Off" ;
VAL_ 1364 ICC_RISD_Pixel380_OnOff 0 "Pixel On" 1 "Pixel Off" ;
VAL_ 1364 ICC_RISD_Pixel379_OnOff 0 "Pixel On" 1 "Pixel Off" ;
VAL_ 1364 ICC_RISD_Pixel378_OnOff 0 "Pixel On" 1 "Pixel Off" ;
VAL_ 1364 ICC_RISD_Pixel377_OnOff 0 "Pixel On" 1 "Pixel Off" ;
VAL_ 1364 ICC_RISD_Pixel376_OnOff 0 "Pixel On" 1 "Pixel Off" ;
VAL_ 1364 ICC_RISD_Pixel375_OnOff 0 "Pixel On" 1 "Pixel Off" ;
VAL_ 1364 ICC_RISD_Pixel374_OnOff 0 "Pixel On" 1 "Pixel Off" ;
VAL_ 1364 ICC_RISD_Pixel373_OnOff 0 "Pixel On" 1 "Pixel Off" ;
VAL_ 1364 ICC_RISD_Pixel372_OnOff 0 "Pixel On" 1 "Pixel Off" ;
VAL_ 1364 ICC_RISD_Pixel371_OnOff 0 "Pixel On" 1 "Pixel Off" ;
VAL_ 1364 ICC_RISD_Pixel370_OnOff 0 "Pixel On" 1 "Pixel Off" ;
VAL_ 1364 ICC_RISD_Pixel369_OnOff 0 "Pixel On" 1 "Pixel Off" ;
VAL_ 1364 ICC_RISD_Pixel368_OnOff 0 "Pixel On" 1 "Pixel Off" ;
VAL_ 1364 ICC_RISD_Pixel367_OnOff 0 "Pixel On" 1 "Pixel Off" ;
VAL_ 1364 ICC_RISD_Pixel366_OnOff 0 "Pixel On" 1 "Pixel Off" ;
VAL_ 1364 ICC_RISD_Pixel365_OnOff 0 "Pixel On" 1 "Pixel Off" ;
VAL_ 1364 ICC_RISD_Pixel364_OnOff 0 "Pixel On" 1 "Pixel Off" ;
VAL_ 1364 ICC_RISD_Pixel363_OnOff 0 "Pixel On" 1 "Pixel Off" ;
VAL_ 1364 ICC_RISD_Pixel362_OnOff 0 "Pixel On" 1 "Pixel Off" ;
VAL_ 1364 ICC_RISD_Pixel361_OnOff 0 "Pixel On" 1 "Pixel Off" ;
VAL_ 1364 ICC_RISD_Pixel360_OnOff 0 "Pixel On" 1 "Pixel Off" ;
VAL_ 1364 ICC_RISD_Pixel359_OnOff 0 "Pixel On" 1 "Pixel Off" ;
VAL_ 1364 ICC_RISD_Pixel358_OnOff 0 "Pixel On" 1 "Pixel Off" ;
VAL_ 1364 ICC_RISD_Pixel357_OnOff 0 "Pixel On" 1 "Pixel Off" ;
VAL_ 1364 ICC_RISD_Pixel356_OnOff 0 "Pixel On" 1 "Pixel Off" ;
VAL_ 1364 ICC_RISD_Pixel355_OnOff 0 "Pixel On" 1 "Pixel Off" ;
VAL_ 1364 ICC_RISD_Pixel354_OnOff 0 "Pixel On" 1 "Pixel Off" ;
VAL_ 1364 ICC_RISD_Pixel353_OnOff 0 "Pixel On" 1 "Pixel Off" ;
VAL_ 1364 ICC_RISD_Pixel352_OnOff 0 "Pixel On" 1 "Pixel Off" ;
VAL_ 1364 ICC_RISD_Pixel351_OnOff 0 "Pixel On" 1 "Pixel Off" ;
VAL_ 1364 ICC_RISD_Pixel350_OnOff 0 "Pixel On" 1 "Pixel Off" ;
VAL_ 1364 ICC_RISD_Pixel349_OnOff 0 "Pixel On" 1 "Pixel Off" ;
VAL_ 1364 ICC_RISD_Pixel348_OnOff 0 "Pixel On" 1 "Pixel Off" ;
VAL_ 1364 ICC_RISD_Pixel347_OnOff 0 "Pixel On" 1 "Pixel Off" ;
VAL_ 1364 ICC_RISD_Pixel346_OnOff 0 "Pixel On" 1 "Pixel Off" ;
VAL_ 1364 ICC_RISD_Pixel345_OnOff 0 "Pixel On" 1 "Pixel Off" ;
VAL_ 1364 ICC_RISD_Pixel344_OnOff 0 "Pixel On" 1 "Pixel Off" ;
VAL_ 1364 ICC_RISD_Pixel343_OnOff 0 "Pixel On" 1 "Pixel Off" ;
VAL_ 1364 ICC_RISD_Pixel342_OnOff 0 "Pixel On" 1 "Pixel Off" ;
VAL_ 1364 ICC_RISD_Pixel341_OnOff 0 "Pixel On" 1 "Pixel Off" ;
VAL_ 1364 ICC_RISD_Pixel340_OnOff 0 "Pixel On" 1 "Pixel Off" ;
VAL_ 1364 ICC_RISD_Pixel339_OnOff 0 "Pixel On" 1 "Pixel Off" ;
VAL_ 1364 ICC_RISD_Pixel338_OnOff 0 "Pixel On" 1 "Pixel Off" ;
VAL_ 1364 ICC_RISD_Pixel337_OnOff 0 "Pixel On" 1 "Pixel Off" ;
VAL_ 1364 ICC_RISD_Pixel336_OnOff 0 "Pixel On" 1 "Pixel Off" ;
VAL_ 1364 ICC_RISD_Pixel335_OnOff 0 "Pixel On" 1 "Pixel Off" ;
VAL_ 1364 ICC_RISD_Pixel334_OnOff 0 "Pixel On" 1 "Pixel Off" ;
VAL_ 1364 ICC_RISD_Pixel333_OnOff 0 "Pixel On" 1 "Pixel Off" ;
VAL_ 1364 ICC_RISD_Pixel332_OnOff 0 "Pixel On" 1 "Pixel Off" ;
VAL_ 1364 ICC_RISD_Pixel331_OnOff 0 "Pixel On" 1 "Pixel Off" ;
VAL_ 1364 ICC_RISD_Pixel330_OnOff 0 "Pixel On" 1 "Pixel Off" ;
VAL_ 1364 ICC_RISD_Pixel329_OnOff 0 "Pixel On" 1 "Pixel Off" ;
VAL_ 1364 ICC_RISD_Pixel328_OnOff 0 "Pixel On" 1 "Pixel Off" ;
VAL_ 1364 ICC_RISD_Pixel327_OnOff 0 "Pixel On" 1 "Pixel Off" ;
VAL_ 1364 ICC_RISD_Pixel326_OnOff 0 "Pixel On" 1 "Pixel Off" ;
VAL_ 1364 ICC_RISD_Pixel325_OnOff 0 "Pixel On" 1 "Pixel Off" ;
VAL_ 1364 ICC_RISD_Pixel324_OnOff 0 "Pixel On" 1 "Pixel Off" ;
VAL_ 1364 ICC_RISD_Pixel323_OnOff 0 "Pixel On" 1 "Pixel Off" ;
VAL_ 1364 ICC_RISD_Pixel322_OnOff 0 "Pixel On" 1 "Pixel Off" ;
VAL_ 1364 ICC_RISD_Pixel321_OnOff 0 "Pixel On" 1 "Pixel Off" ;
VAL_ 1364 ICC_RISD_Pixel320_OnOff 0 "Pixel On" 1 "Pixel Off" ;
VAL_ 1364 ICC_RISD_Pixel319_OnOff 0 "Pixel On" 1 "Pixel Off" ;
VAL_ 1364 ICC_RISD_Pixel318_OnOff 0 "Pixel On" 1 "Pixel Off" ;
VAL_ 1364 ICC_RISD_Pixel317_OnOff 0 "Pixel On" 1 "Pixel Off" ;
VAL_ 1364 ICC_RISD_Pixel316_OnOff 0 "Pixel On" 1 "Pixel Off" ;
VAL_ 1364 ICC_RISD_Pixel315_OnOff 0 "Pixel On" 1 "Pixel Off" ;
VAL_ 1364 ICC_RISD_Pixel314_OnOff 0 "Pixel On" 1 "Pixel Off" ;
VAL_ 1364 ICC_RISD_Pixel313_OnOff 0 "Pixel On" 1 "Pixel Off" ;
VAL_ 1364 ICC_RISD_Pixel312_OnOff 0 "Pixel On" 1 "Pixel Off" ;
VAL_ 1364 ICC_RISD_Pixel311_OnOff 0 "Pixel On" 1 "Pixel Off" ;
VAL_ 1364 ICC_RISD_Pixel310_OnOff 0 "Pixel On" 1 "Pixel Off" ;
VAL_ 1364 ICC_RISD_Pixel309_OnOff 0 "Pixel On" 1 "Pixel Off" ;
VAL_ 1364 ICC_RISD_Pixel308_OnOff 0 "Pixel On" 1 "Pixel Off" ;
VAL_ 1364 ICC_RISD_Pixel307_OnOff 0 "Pixel On" 1 "Pixel Off" ;
VAL_ 1364 ICC_RISD_Pixel306_OnOff 0 "Pixel On" 1 "Pixel Off" ;
VAL_ 1364 ICC_RISD_Pixel305_OnOff 0 "Pixel On" 1 "Pixel Off" ;
VAL_ 1364 ICC_RISD_Pixel304_OnOff 0 "Pixel On" 1 "Pixel Off" ;
VAL_ 1364 ICC_RISD_Pixel303_OnOff 0 "Pixel On" 1 "Pixel Off" ;
VAL_ 1364 ICC_RISD_Pixel302_OnOff 0 "Pixel On" 1 "Pixel Off" ;
VAL_ 1364 ICC_RISD_Pixel301_OnOff 0 "Pixel On" 1 "Pixel Off" ;
VAL_ 1364 ICC_RISD_Pixel300_OnOff 0 "Pixel On" 1 "Pixel Off" ;
VAL_ 1364 ICC_RISD_Pixel299_OnOff 0 "Pixel On" 1 "Pixel Off" ;
VAL_ 1364 ICC_RISD_Pixel298_OnOff 0 "Pixel On" 1 "Pixel Off" ;
VAL_ 1364 ICC_RISD_Pixel297_OnOff 0 "Pixel On" 1 "Pixel Off" ;
VAL_ 1364 ICC_RISD_Pixel296_OnOff 0 "Pixel On" 1 "Pixel Off" ;
VAL_ 1364 ICC_RISD_Pixel295_OnOff 0 "Pixel On" 1 "Pixel Off" ;
VAL_ 1364 ICC_RISD_Pixel294_OnOff 0 "Pixel On" 1 "Pixel Off" ;
VAL_ 1364 ICC_RISD_Pixel293_OnOff 0 "Pixel On" 1 "Pixel Off" ;
VAL_ 1364 ICC_RISD_Pixel292_OnOff 0 "Pixel On" 1 "Pixel Off" ;
VAL_ 1364 ICC_RISD_Pixel291_OnOff 0 "Pixel On" 1 "Pixel Off" ;
VAL_ 1364 ICC_RISD_Pixel290_OnOff 0 "Pixel On" 1 "Pixel Off" ;
VAL_ 1364 ICC_RISD_Pixel289_OnOff 0 "Pixel On" 1 "Pixel Off" ;
VAL_ 1364 ICC_RISD_Pixel288_OnOff 0 "Pixel On" 1 "Pixel Off" ;
VAL_ 1364 ICC_RISD_Pixel287_OnOff 0 "Pixel On" 1 "Pixel Off" ;
VAL_ 1364 ICC_RISD_Pixel286_OnOff 0 "Pixel On" 1 "Pixel Off" ;
VAL_ 1364 ICC_RISD_Pixel285_OnOff 0 "Pixel On" 1 "Pixel Off" ;
VAL_ 1364 ICC_RISD_Pixel284_OnOff 0 "Pixel On" 1 "Pixel Off" ;
VAL_ 1364 ICC_RISD_Pixel283_OnOff 0 "Pixel On" 1 "Pixel Off" ;
VAL_ 1364 ICC_RISD_Pixel282_OnOff 0 "Pixel On" 1 "Pixel Off" ;
VAL_ 1364 ICC_RISD_Pixel281_OnOff 0 "Pixel On" 1 "Pixel Off" ;
VAL_ 1364 ICC_RISD_Pixel280_OnOff 0 "Pixel On" 1 "Pixel Off" ;
VAL_ 1364 ICC_RISD_Pixel279_OnOff 0 "Pixel On" 1 "Pixel Off" ;
VAL_ 1364 ICC_RISD_Pixel278_OnOff 0 "Pixel On" 1 "Pixel Off" ;
VAL_ 1364 ICC_RISD_Pixel277_OnOff 0 "Pixel On" 1 "Pixel Off" ;
VAL_ 1364 ICC_RISD_Pixel276_OnOff 0 "Pixel On" 1 "Pixel Off" ;
VAL_ 1364 ICC_RISD_Pixel275_OnOff 0 "Pixel On" 1 "Pixel Off" ;
VAL_ 1364 ICC_RISD_Pixel274_OnOff 0 "Pixel On" 1 "Pixel Off" ;
VAL_ 1364 ICC_RISD_Pixel273_OnOff 0 "Pixel On" 1 "Pixel Off" ;
VAL_ 1364 ICC_RISD_Pixel272_OnOff 0 "Pixel On" 1 "Pixel Off" ;
VAL_ 1364 ICC_RISD_Pixel271_OnOff 0 "Pixel On" 1 "Pixel Off" ;
VAL_ 1364 ICC_RISD_Pixel270_OnOff 0 "Pixel On" 1 "Pixel Off" ;
VAL_ 1364 ICC_RISD_Pixel269_OnOff 0 "Pixel On" 1 "Pixel Off" ;
VAL_ 1364 ICC_RISD_Pixel268_OnOff 0 "Pixel On" 1 "Pixel Off" ;
VAL_ 1364 ICC_RISD_Pixel267_OnOff 0 "Pixel On" 1 "Pixel Off" ;
VAL_ 1364 ICC_RISD_Pixel266_OnOff 0 "Pixel On" 1 "Pixel Off" ;
VAL_ 1364 ICC_RISD_Pixel265_OnOff 0 "Pixel On" 1 "Pixel Off" ;
VAL_ 1364 ICC_RISD_Pixel264_OnOff 0 "Pixel On" 1 "Pixel Off" ;
VAL_ 1364 ICC_RISD_Pixel263_OnOff 0 "Pixel On" 1 "Pixel Off" ;
VAL_ 1364 ICC_RISD_Pixel262_OnOff 0 "Pixel On" 1 "Pixel Off" ;
VAL_ 1364 ICC_RISD_Pixel261_OnOff 0 "Pixel On" 1 "Pixel Off" ;
VAL_ 1364 ICC_RISD_Pixel260_OnOff 0 "Pixel On" 1 "Pixel Off" ;
VAL_ 1364 ICC_RISD_Pixel259_OnOff 0 "Pixel On" 1 "Pixel Off" ;
VAL_ 1364 ICC_RISD_Pixel258_OnOff 0 "Pixel On" 1 "Pixel Off" ;
VAL_ 1364 ICC_RISD_Pixel257_OnOff 0 "Pixel On" 1 "Pixel Off" ;
VAL_ 1364 ICC_RISD_Pixel256_OnOff 0 "Pixel On" 1 "Pixel Off" ;
VAL_ 1364 ICC_RISD_Pixel255_OnOff 0 "Pixel On" 1 "Pixel Off" ;
VAL_ 1364 ICC_RISD_Pixel254_OnOff 0 "Pixel On" 1 "Pixel Off" ;
VAL_ 1364 ICC_RISD_Pixel253_OnOff 0 "Pixel On" 1 "Pixel Off" ;
VAL_ 1364 ICC_RISD_Pixel252_OnOff 0 "Pixel On" 1 "Pixel Off" ;
VAL_ 1364 ICC_RISD_Pixel251_OnOff 0 "Pixel On" 1 "Pixel Off" ;
VAL_ 1364 ICC_RISD_Pixel250_OnOff 0 "Pixel On" 1 "Pixel Off" ;
VAL_ 1364 ICC_RISD_Pixel249_OnOff 0 "Pixel On" 1 "Pixel Off" ;
VAL_ 1364 ICC_RISD_Pixel248_OnOff 0 "Pixel On" 1 "Pixel Off" ;
VAL_ 1364 ICC_RISD_Pixel247_OnOff 0 "Pixel On" 1 "Pixel Off" ;
VAL_ 1364 ICC_RISD_Pixel246_OnOff 0 "Pixel On" 1 "Pixel Off" ;
VAL_ 1364 ICC_RISD_Pixel245_OnOff 0 "Pixel On" 1 "Pixel Off" ;
VAL_ 1364 ICC_RISD_Pixel244_OnOff 0 "Pixel On" 1 "Pixel Off" ;
VAL_ 1364 ICC_RISD_Pixel243_OnOff 0 "Pixel On" 1 "Pixel Off" ;
VAL_ 1364 ICC_RISD_Pixel242_OnOff 0 "Pixel On" 1 "Pixel Off" ;
VAL_ 1364 ICC_RISD_Pixel241_OnOff 0 "Pixel On" 1 "Pixel Off" ;
VAL_ 1364 ICC_RISD_Pixel240_OnOff 0 "Pixel On" 1 "Pixel Off" ;
VAL_ 1364 ICC_RISD_Pixel239_OnOff 0 "Pixel On" 1 "Pixel Off" ;
VAL_ 1364 ICC_RISD_Pixel238_OnOff 0 "Pixel On" 1 "Pixel Off" ;
VAL_ 1364 ICC_RISD_Pixel237_OnOff 0 "Pixel On" 1 "Pixel Off" ;
VAL_ 1364 ICC_RISD_Pixel236_OnOff 0 "Pixel On" 1 "Pixel Off" ;
VAL_ 1364 ICC_RISD_Pixel235_OnOff 0 "Pixel On" 1 "Pixel Off" ;
VAL_ 1364 ICC_RISD_Pixel234_OnOff 0 "Pixel On" 1 "Pixel Off" ;
VAL_ 1364 ICC_RISD_Pixel233_OnOff 0 "Pixel On" 1 "Pixel Off" ;
VAL_ 1364 ICC_RISD_Pixel232_OnOff 0 "Pixel On" 1 "Pixel Off" ;
VAL_ 1364 ICC_RISD_Pixel231_OnOff 0 "Pixel On" 1 "Pixel Off" ;
VAL_ 1364 ICC_RISD_Pixel230_OnOff 0 "Pixel On" 1 "Pixel Off" ;
VAL_ 1364 ICC_RISD_Pixel229_OnOff 0 "Pixel On" 1 "Pixel Off" ;
VAL_ 1364 ICC_RISD_Pixel228_OnOff 0 "Pixel On" 1 "Pixel Off" ;
VAL_ 1364 ICC_RISD_Pixel227_OnOff 0 "Pixel On" 1 "Pixel Off" ;
VAL_ 1364 ICC_RISD_Pixel226_OnOff 0 "Pixel On" 1 "Pixel Off" ;
VAL_ 1364 ICC_RISD_Pixel225_OnOff 0 "Pixel On" 1 "Pixel Off" ;
VAL_ 1364 ICC_RISD_Pixel224_OnOff 0 "Pixel On" 1 "Pixel Off" ;
VAL_ 1364 ICC_RISD_Pixel223_OnOff 0 "Pixel On" 1 "Pixel Off" ;
VAL_ 1364 ICC_RISD_Pixel222_OnOff 0 "Pixel On" 1 "Pixel Off" ;
VAL_ 1364 ICC_RISD_Pixel221_OnOff 0 "Pixel On" 1 "Pixel Off" ;
VAL_ 1364 ICC_RISD_Pixel220_OnOff 0 "Pixel On" 1 "Pixel Off" ;
VAL_ 1364 ICC_RISD_Pixel219_OnOff 0 "Pixel On" 1 "Pixel Off" ;
VAL_ 1364 ICC_RISD_Pixel218_OnOff 0 "Pixel On" 1 "Pixel Off" ;
VAL_ 1364 ICC_RISD_Pixel217_OnOff 0 "Pixel On" 1 "Pixel Off" ;
VAL_ 1364 ICC_RISD_Pixel216_OnOff 0 "Pixel On" 1 "Pixel Off" ;
VAL_ 1364 ICC_RISD_Pixel215_OnOff 0 "Pixel On" 1 "Pixel Off" ;
VAL_ 1364 ICC_RISD_Pixel214_OnOff 0 "Pixel On" 1 "Pixel Off" ;
VAL_ 1364 ICC_RISD_Pixel213_OnOff 0 "Pixel On" 1 "Pixel Off" ;
VAL_ 1364 ICC_RISD_Pixel212_OnOff 0 "Pixel On" 1 "Pixel Off" ;
VAL_ 1364 ICC_RISD_Pixel211_OnOff 0 "Pixel On" 1 "Pixel Off" ;
VAL_ 1364 ICC_RISD_Pixel210_OnOff 0 "Pixel On" 1 "Pixel Off" ;
VAL_ 1364 ICC_RISD_Pixel209_OnOff 0 "Pixel On" 1 "Pixel Off" ;
VAL_ 1364 ICC_RISD_Pixel208_OnOff 0 "Pixel On" 1 "Pixel Off" ;
VAL_ 1364 ICC_RISD_Pixel207_OnOff 0 "Pixel On" 1 "Pixel Off" ;
VAL_ 1364 ICC_RISD_Pixel206_OnOff 0 "Pixel On" 1 "Pixel Off" ;
VAL_ 1364 ICC_RISD_Pixel205_OnOff 0 "Pixel On" 1 "Pixel Off" ;
VAL_ 1364 ICC_RISD_Pixel204_OnOff 0 "Pixel On" 1 "Pixel Off" ;
VAL_ 1364 ICC_RISD_Pixel203_OnOff 0 "Pixel On" 1 "Pixel Off" ;
VAL_ 1364 ICC_RISD_Pixel202_OnOff 0 "Pixel On" 1 "Pixel Off" ;
VAL_ 1364 ICC_RISD_Pixel201_OnOff 0 "Pixel On" 1 "Pixel Off" ;
VAL_ 1364 ICC_RISD_Pixel200_OnOff 0 "Pixel On" 1 "Pixel Off" ;
VAL_ 1364 ICC_RISD_Pixel199_OnOff 0 "Pixel On" 1 "Pixel Off" ;
VAL_ 1364 ICC_RISD_Pixel198_OnOff 0 "Pixel On" 1 "Pixel Off" ;
VAL_ 1364 ICC_RISD_Pixel197_OnOff 0 "Pixel On" 1 "Pixel Off" ;
VAL_ 1364 ICC_RISD_Pixel196_OnOff 0 "Pixel On" 1 "Pixel Off" ;
VAL_ 1364 ICC_RISD_Pixel195_OnOff 0 "Pixel On" 1 "Pixel Off" ;
VAL_ 1364 ICC_RISD_Pixel194_OnOff 0 "Pixel On" 1 "Pixel Off" ;
VAL_ 1364 ICC_RISD_Pixel193_OnOff 0 "Pixel On" 1 "Pixel Off" ;
VAL_ 1364 ICC_RISD_Pixel192_OnOff 0 "Pixel On" 1 "Pixel Off" ;
VAL_ 1364 ICC_RISD_Pixel191_OnOff 0 "Pixel On" 1 "Pixel Off" ;
VAL_ 1364 ICC_RISD_Pixel190_OnOff 0 "Pixel On" 1 "Pixel Off" ;
VAL_ 1364 ICC_RISD_Pixel189_OnOff 0 "Pixel On" 1 "Pixel Off" ;
VAL_ 1364 ICC_RISD_Pixel188_OnOff 0 "Pixel On" 1 "Pixel Off" ;
VAL_ 1364 ICC_RISD_Pixel187_OnOff 0 "Pixel On" 1 "Pixel Off" ;
VAL_ 1364 ICC_RISD_Pixel186_OnOff 0 "Pixel On" 1 "Pixel Off" ;
VAL_ 1364 ICC_RISD_Pixel185_OnOff 0 "Pixel On" 1 "Pixel Off" ;
VAL_ 1364 ICC_RISD_Pixel184_OnOff 0 "Pixel On" 1 "Pixel Off" ;
VAL_ 1364 ICC_RISD_Pixel183_OnOff 0 "Pixel On" 1 "Pixel Off" ;
VAL_ 1364 ICC_RISD_Pixel182_OnOff 0 "Pixel On" 1 "Pixel Off" ;
VAL_ 1364 ICC_RISD_Pixel181_OnOff 0 "Pixel On" 1 "Pixel Off" ;
VAL_ 1364 ICC_RISD_Pixel180_OnOff 0 "Pixel On" 1 "Pixel Off" ;
VAL_ 1364 ICC_RISD_Pixel179_OnOff 0 "Pixel On" 1 "Pixel Off" ;
VAL_ 1364 ICC_RISD_Pixel178_OnOff 0 "Pixel On" 1 "Pixel Off" ;
VAL_ 1364 ICC_RISD_Pixel177_OnOff 0 "Pixel On" 1 "Pixel Off" ;
VAL_ 1364 ICC_RISD_Pixel176_OnOff 0 "Pixel On" 1 "Pixel Off" ;
VAL_ 1364 ICC_RISD_Pixel175_OnOff 0 "Pixel On" 1 "Pixel Off" ;
VAL_ 1364 ICC_RISD_Pixel174_OnOff 0 "Pixel On" 1 "Pixel Off" ;
VAL_ 1364 ICC_RISD_Pixel173_OnOff 0 "Pixel On" 1 "Pixel Off" ;
VAL_ 1364 ICC_RISD_Pixel172_OnOff 0 "Pixel On" 1 "Pixel Off" ;
VAL_ 1364 ICC_RISD_Pixel171_OnOff 0 "Pixel On" 1 "Pixel Off" ;
VAL_ 1364 ICC_RISD_Pixel170_OnOff 0 "Pixel On" 1 "Pixel Off" ;
VAL_ 1364 ICC_RISD_Pixel169_OnOff 0 "Pixel On" 1 "Pixel Off" ;
VAL_ 1364 ICC_RISD_Pixel168_OnOff 0 "Pixel On" 1 "Pixel Off" ;
VAL_ 1364 ICC_RISD_Pixel167_OnOff 0 "Pixel On" 1 "Pixel Off" ;
VAL_ 1364 ICC_RISD_Pixel166_OnOff 0 "Pixel On" 1 "Pixel Off" ;
VAL_ 1364 ICC_RISD_Pixel165_OnOff 0 "Pixel On" 1 "Pixel Off" ;
VAL_ 1364 ICC_RISD_Pixel164_OnOff 0 "Pixel On" 1 "Pixel Off" ;
VAL_ 1364 ICC_RISD_Pixel163_OnOff 0 "Pixel On" 1 "Pixel Off" ;
VAL_ 1364 ICC_RISD_Pixel162_OnOff 0 "Pixel On" 1 "Pixel Off" ;
VAL_ 1364 ICC_RISD_Pixel161_OnOff 0 "Pixel On" 1 "Pixel Off" ;
VAL_ 1364 ICC_RISD_Pixel160_OnOff 0 "Pixel On" 1 "Pixel Off" ;
VAL_ 1364 ICC_RISD_Pixel159_OnOff 0 "Pixel On" 1 "Pixel Off" ;
VAL_ 1364 ICC_RISD_Pixel158_OnOff 0 "Pixel On" 1 "Pixel Off" ;
VAL_ 1364 ICC_RISD_Pixel157_OnOff 0 "Pixel On" 1 "Pixel Off" ;
VAL_ 1364 ICC_RISD_Pixel156_OnOff 0 "Pixel On" 1 "Pixel Off" ;
VAL_ 1364 ICC_RISD_Pixel155_OnOff 0 "Pixel On" 1 "Pixel Off" ;
VAL_ 1364 ICC_RISD_Pixel154_OnOff 0 "Pixel On" 1 "Pixel Off" ;
VAL_ 1364 ICC_RISD_Pixel153_OnOff 0 "Pixel On" 1 "Pixel Off" ;
VAL_ 1364 ICC_RISD_Pixel152_OnOff 0 "Pixel On" 1 "Pixel Off" ;
VAL_ 1364 ICC_RISD_Pixel151_OnOff 0 "Pixel On" 1 "Pixel Off" ;
VAL_ 1364 ICC_RISD_Pixel150_OnOff 0 "Pixel On" 1 "Pixel Off" ;
VAL_ 1364 ICC_RISD_Pixel149_OnOff 0 "Pixel On" 1 "Pixel Off" ;
VAL_ 1364 ICC_RISD_Pixel148_OnOff 0 "Pixel On" 1 "Pixel Off" ;
VAL_ 1364 ICC_RISD_Pixel147_OnOff 0 "Pixel On" 1 "Pixel Off" ;
VAL_ 1364 ICC_RISD_Pixel146_OnOff 0 "Pixel On" 1 "Pixel Off" ;
VAL_ 1364 ICC_RISD_Pixel145_OnOff 0 "Pixel On" 1 "Pixel Off" ;
VAL_ 1364 ICC_RISD_Pixel144_OnOff 0 "Pixel On" 1 "Pixel Off" ;
VAL_ 1364 ICC_RISD_Pixel143_OnOff 0 "Pixel On" 1 "Pixel Off" ;
VAL_ 1364 ICC_RISD_Pixel142_OnOff 0 "Pixel On" 1 "Pixel Off" ;
VAL_ 1364 ICC_RISD_Pixel141_OnOff 0 "Pixel On" 1 "Pixel Off" ;
VAL_ 1364 ICC_RISD_Pixel140_OnOff 0 "Pixel On" 1 "Pixel Off" ;
VAL_ 1364 ICC_RISD_Pixel139_OnOff 0 "Pixel On" 1 "Pixel Off" ;
VAL_ 1364 ICC_RISD_Pixel138_OnOff 0 "Pixel On" 1 "Pixel Off" ;
VAL_ 1364 ICC_RISD_Pixel137_OnOff 0 "Pixel On" 1 "Pixel Off" ;
VAL_ 1364 ICC_RISD_Pixel136_OnOff 0 "Pixel On" 1 "Pixel Off" ;
VAL_ 1364 ICC_RISD_Pixel135_OnOff 0 "Pixel On" 1 "Pixel Off" ;
VAL_ 1364 ICC_RISD_Pixel134_OnOff 0 "Pixel On" 1 "Pixel Off" ;
VAL_ 1364 ICC_RISD_Pixel133_OnOff 0 "Pixel On" 1 "Pixel Off" ;
VAL_ 1364 ICC_RISD_Pixel132_OnOff 0 "Pixel On" 1 "Pixel Off" ;
VAL_ 1364 ICC_RISD_Pixel131_OnOff 0 "Pixel On" 1 "Pixel Off" ;
VAL_ 1364 ICC_RISD_Pixel130_OnOff 0 "Pixel On" 1 "Pixel Off" ;
VAL_ 1364 ICC_RISD_Pixel129_OnOff 0 "Pixel On" 1 "Pixel Off" ;
VAL_ 1364 ICC_RISD_Pixel128_OnOff 0 "Pixel On" 1 "Pixel Off" ;
VAL_ 1364 ICC_RISD_Pixel127_OnOff 0 "Pixel On" 1 "Pixel Off" ;
VAL_ 1364 ICC_RISD_Pixel126_OnOff 0 "Pixel On" 1 "Pixel Off" ;
VAL_ 1364 ICC_RISD_Pixel125_OnOff 0 "Pixel On" 1 "Pixel Off" ;
VAL_ 1364 ICC_RISD_Pixel124_OnOff 0 "Pixel On" 1 "Pixel Off" ;
VAL_ 1364 ICC_RISD_Pixel123_OnOff 0 "Pixel On" 1 "Pixel Off" ;
VAL_ 1364 ICC_RISD_Pixel122_OnOff 0 "Pixel On" 1 "Pixel Off" ;
VAL_ 1364 ICC_RISD_Pixel121_OnOff 0 "Pixel On" 1 "Pixel Off" ;
VAL_ 1364 ICC_RISD_Pixel120_OnOff 0 "Pixel On" 1 "Pixel Off" ;
VAL_ 1364 ICC_RISD_Pixel119_OnOff 0 "Pixel On" 1 "Pixel Off" ;
VAL_ 1364 ICC_RISD_Pixel118_OnOff 0 "Pixel On" 1 "Pixel Off" ;
VAL_ 1364 ICC_RISD_Pixel117_OnOff 0 "Pixel On" 1 "Pixel Off" ;
VAL_ 1364 ICC_RISD_Pixel116_OnOff 0 "Pixel On" 1 "Pixel Off" ;
VAL_ 1364 ICC_RISD_Pixel115_OnOff 0 "Pixel On" 1 "Pixel Off" ;
VAL_ 1364 ICC_RISD_Pixel114_OnOff 0 "Pixel On" 1 "Pixel Off" ;
VAL_ 1364 ICC_RISD_Pixel113_OnOff 0 "Pixel On" 1 "Pixel Off" ;
VAL_ 1364 ICC_RISD_Pixel112_OnOff 0 "Pixel On" 1 "Pixel Off" ;
VAL_ 1364 ICC_RISD_Pixel111_OnOff 0 "Pixel On" 1 "Pixel Off" ;
VAL_ 1364 ICC_RISD_Pixel110_OnOff 0 "Pixel On" 1 "Pixel Off" ;
VAL_ 1364 ICC_RISD_Pixel109_OnOff 0 "Pixel On" 1 "Pixel Off" ;
VAL_ 1364 ICC_RISD_Pixel108_OnOff 0 "Pixel On" 1 "Pixel Off" ;
VAL_ 1364 ICC_RISD_Pixel107_OnOff 0 "Pixel On" 1 "Pixel Off" ;
VAL_ 1364 ICC_RISD_Pixel106_OnOff 0 "Pixel On" 1 "Pixel Off" ;
VAL_ 1364 ICC_RISD_Pixel105_OnOff 0 "Pixel On" 1 "Pixel Off" ;
VAL_ 1364 ICC_RISD_Pixel104_OnOff 0 "Pixel On" 1 "Pixel Off" ;
VAL_ 1364 ICC_RISD_Pixel103_OnOff 0 "Pixel On" 1 "Pixel Off" ;
VAL_ 1364 ICC_RISD_Pixel102_OnOff 0 "Pixel On" 1 "Pixel Off" ;
VAL_ 1364 ICC_RISD_Pixel101_OnOff 0 "Pixel On" 1 "Pixel Off" ;
VAL_ 1364 ICC_RISD_Pixel100_OnOff 0 "Pixel On" 1 "Pixel Off" ;
VAL_ 1364 ICC_RISD_Pixel99_OnOff 0 "Pixel On" 1 "Pixel Off" ;
VAL_ 1364 ICC_RISD_Pixel98_OnOff 0 "Pixel On" 1 "Pixel Off" ;
VAL_ 1364 ICC_RISD_Pixel97_OnOff 0 "Pixel On" 1 "Pixel Off" ;
VAL_ 1364 ICC_RISD_Pixel96_OnOff 0 "Pixel On" 1 "Pixel Off" ;
VAL_ 1364 ICC_RISD_Pixel95_OnOff 0 "Pixel On" 1 "Pixel Off" ;
VAL_ 1364 ICC_RISD_Pixel94_OnOff 0 "Pixel On" 1 "Pixel Off" ;
VAL_ 1364 ICC_RISD_Pixel93_OnOff 0 "Pixel On" 1 "Pixel Off" ;
VAL_ 1364 ICC_RISD_Pixel92_OnOff 0 "Pixel On" 1 "Pixel Off" ;
VAL_ 1364 ICC_RISD_Pixel91_OnOff 0 "Pixel On" 1 "Pixel Off" ;
VAL_ 1364 ICC_RISD_Pixel90_OnOff 0 "Pixel On" 1 "Pixel Off" ;
VAL_ 1364 ICC_RISD_Pixel89_OnOff 0 "Pixel On" 1 "Pixel Off" ;
VAL_ 1364 ICC_RISD_Pixel88_OnOff 0 "Pixel On" 1 "Pixel Off" ;
VAL_ 1364 ICC_RISD_Pixel87_OnOff 0 "Pixel On" 1 "Pixel Off" ;
VAL_ 1364 ICC_RISD_Pixel86_OnOff 0 "Pixel On" 1 "Pixel Off" ;
VAL_ 1364 ICC_RISD_Pixel85_OnOff 0 "Pixel On" 1 "Pixel Off" ;
VAL_ 1364 ICC_RISD_Pixel84_OnOff 0 "Pixel On" 1 "Pixel Off" ;
VAL_ 1364 ICC_RISD_Pixel83_OnOff 0 "Pixel On" 1 "Pixel Off" ;
VAL_ 1364 ICC_RISD_Pixel82_OnOff 0 "Pixel On" 1 "Pixel Off" ;
VAL_ 1364 ICC_RISD_Pixel81_OnOff 0 "Pixel On" 1 "Pixel Off" ;
VAL_ 1364 ICC_RISD_Pixel80_OnOff 0 "Pixel On" 1 "Pixel Off" ;
VAL_ 1364 ICC_RISD_Pixel79_OnOff 0 "Pixel On" 1 "Pixel Off" ;
VAL_ 1364 ICC_RISD_Pixel78_OnOff 0 "Pixel On" 1 "Pixel Off" ;
VAL_ 1364 ICC_RISD_Pixel77_OnOff 0 "Pixel On" 1 "Pixel Off" ;
VAL_ 1364 ICC_RISD_Pixel76_OnOff 0 "Pixel On" 1 "Pixel Off" ;
VAL_ 1364 ICC_RISD_Pixel75_OnOff 0 "Pixel On" 1 "Pixel Off" ;
VAL_ 1364 ICC_RISD_Pixel74_OnOff 0 "Pixel On" 1 "Pixel Off" ;
VAL_ 1364 ICC_RISD_Pixel73_OnOff 0 "Pixel On" 1 "Pixel Off" ;
VAL_ 1364 ICC_RISD_Pixel72_OnOff 0 "Pixel On" 1 "Pixel Off" ;
VAL_ 1364 ICC_RISD_Pixel71_OnOff 0 "Pixel On" 1 "Pixel Off" ;
VAL_ 1364 ICC_RISD_Pixel70_OnOff 0 "Pixel On" 1 "Pixel Off" ;
VAL_ 1364 ICC_RISD_Pixel69_OnOff 0 "Pixel On" 1 "Pixel Off" ;
VAL_ 1364 ICC_RISD_Pixel68_OnOff 0 "Pixel On" 1 "Pixel Off" ;
VAL_ 1364 ICC_RISD_Pixel67_OnOff 0 "Pixel On" 1 "Pixel Off" ;
VAL_ 1364 ICC_RISD_Pixel66_OnOff 0 "Pixel On" 1 "Pixel Off" ;
VAL_ 1364 ICC_RISD_Pixel65_OnOff 0 "Pixel On" 1 "Pixel Off" ;
VAL_ 1364 ICC_RISD_Pixel64_OnOff 0 "Pixel On" 1 "Pixel Off" ;
VAL_ 1364 ICC_RISD_Pixel63_OnOff 0 "Pixel On" 1 "Pixel Off" ;
VAL_ 1364 ICC_RISD_Pixel62_OnOff 0 "Pixel On" 1 "Pixel Off" ;
VAL_ 1364 ICC_RISD_Pixel61_OnOff 0 "Pixel On" 1 "Pixel Off" ;
VAL_ 1364 ICC_RISD_Pixel60_OnOff 0 "Pixel On" 1 "Pixel Off" ;
VAL_ 1364 ICC_RISD_Pixel59_OnOff 0 "Pixel On" 1 "Pixel Off" ;
VAL_ 1364 ICC_RISD_Pixel58_OnOff 0 "Pixel On" 1 "Pixel Off" ;
VAL_ 1364 ICC_RISD_Pixel57_OnOff 0 "Pixel On" 1 "Pixel Off" ;
VAL_ 1364 ICC_RISD_Pixel56_OnOff 0 "Pixel On" 1 "Pixel Off" ;
VAL_ 1364 ICC_RISD_Pixel55_OnOff 0 "Pixel On" 1 "Pixel Off" ;
VAL_ 1364 ICC_RISD_Pixel54_OnOff 0 "Pixel On" 1 "Pixel Off" ;
VAL_ 1364 ICC_RISD_Pixel53_OnOff 0 "Pixel On" 1 "Pixel Off" ;
VAL_ 1364 ICC_RISD_Pixel52_OnOff 0 "Pixel On" 1 "Pixel Off" ;
VAL_ 1364 ICC_RISD_Pixel51_OnOff 0 "Pixel On" 1 "Pixel Off" ;
VAL_ 1364 ICC_RISD_Pixel50_OnOff 0 "Pixel On" 1 "Pixel Off" ;
VAL_ 1364 ICC_RISD_Pixel49_OnOff 0 "Pixel On" 1 "Pixel Off" ;
VAL_ 1364 ICC_RISD_Pixel48_OnOff 0 "Pixel On" 1 "Pixel Off" ;
VAL_ 1364 ICC_RISD_Pixel47_OnOff 0 "Pixel On" 1 "Pixel Off" ;
VAL_ 1364 ICC_RISD_Pixel46_OnOff 0 "Pixel On" 1 "Pixel Off" ;
VAL_ 1364 ICC_RISD_Pixel45_OnOff 0 "Pixel On" 1 "Pixel Off" ;
VAL_ 1364 ICC_RISD_Pixel44_OnOff 0 "Pixel On" 1 "Pixel Off" ;
VAL_ 1364 ICC_RISD_Pixel43_OnOff 0 "Pixel On" 1 "Pixel Off" ;
VAL_ 1364 ICC_RISD_Pixel42_OnOff 0 "Pixel On" 1 "Pixel Off" ;
VAL_ 1364 ICC_RISD_Pixel41_OnOff 0 "Pixel On" 1 "Pixel Off" ;
VAL_ 1364 ICC_RISD_Pixel40_OnOff 0 "Pixel On" 1 "Pixel Off" ;
VAL_ 1364 ICC_RISD_Pixel39_OnOff 0 "Pixel On" 1 "Pixel Off" ;
VAL_ 1364 ICC_RISD_Pixel38_OnOff 0 "Pixel On" 1 "Pixel Off" ;
VAL_ 1364 ICC_RISD_Pixel37_OnOff 0 "Pixel On" 1 "Pixel Off" ;
VAL_ 1364 ICC_RISD_Pixel36_OnOff 0 "Pixel On" 1 "Pixel Off" ;
VAL_ 1364 ICC_RISD_Pixel35_OnOff 0 "Pixel On" 1 "Pixel Off" ;
VAL_ 1364 ICC_RISD_Pixel34_OnOff 0 "Pixel On" 1 "Pixel Off" ;
VAL_ 1364 ICC_RISD_Pixel33_OnOff 0 "Pixel On" 1 "Pixel Off" ;
VAL_ 1364 ICC_RISD_Pixel32_OnOff 0 "Pixel On" 1 "Pixel Off" ;
VAL_ 1364 ICC_RISD_Pixel31_OnOff 0 "Pixel On" 1 "Pixel Off" ;
VAL_ 1364 ICC_RISD_Pixel30_OnOff 0 "Pixel On" 1 "Pixel Off" ;
VAL_ 1364 ICC_RISD_Pixel29_OnOff 0 "Pixel On" 1 "Pixel Off" ;
VAL_ 1364 ICC_RISD_Pixel28_OnOff 0 "Pixel On" 1 "Pixel Off" ;
VAL_ 1364 ICC_RISD_Pixel27_OnOff 0 "Pixel On" 1 "Pixel Off" ;
VAL_ 1364 ICC_RISD_Pixel26_OnOff 0 "Pixel On" 1 "Pixel Off" ;
VAL_ 1364 ICC_RISD_Pixel25_OnOff 0 "Pixel On" 1 "Pixel Off" ;
VAL_ 1364 ICC_RISD_Pixel24_OnOff 0 "Pixel On" 1 "Pixel Off" ;
VAL_ 1364 ICC_RISD_Pixel23_OnOff 0 "Pixel On" 1 "Pixel Off" ;
VAL_ 1364 ICC_RISD_Pixel22_OnOff 0 "Pixel On" 1 "Pixel Off" ;
VAL_ 1364 ICC_RISD_Pixel21_OnOff 0 "Pixel On" 1 "Pixel Off" ;
VAL_ 1364 ICC_RISD_Pixel20_OnOff 0 "Pixel On" 1 "Pixel Off" ;
VAL_ 1364 ICC_RISD_Pixel19_OnOff 0 "Pixel On" 1 "Pixel Off" ;
VAL_ 1364 ICC_RISD_Pixel18_OnOff 0 "Pixel On" 1 "Pixel Off" ;
VAL_ 1364 ICC_RISD_Pixel17_OnOff 0 "Pixel On" 1 "Pixel Off" ;
VAL_ 1364 ICC_RISD_Pixel16_OnOff 0 "Pixel On" 1 "Pixel Off" ;
VAL_ 1364 ICC_RISD_Pixel15_OnOff 0 "Pixel On" 1 "Pixel Off" ;
VAL_ 1364 ICC_RISD_Pixel14_OnOff 0 "Pixel On" 1 "Pixel Off" ;
VAL_ 1364 ICC_RISD_Pixel13_OnOff 0 "Pixel On" 1 "Pixel Off" ;
VAL_ 1364 ICC_RISD_Pixel12_OnOff 0 "Pixel On" 1 "Pixel Off" ;
VAL_ 1364 ICC_RISD_Pixel11_OnOff 0 "Pixel On" 1 "Pixel Off" ;
VAL_ 1364 ICC_RISD_Pixel10_OnOff 0 "Pixel On" 1 "Pixel Off" ;
VAL_ 1364 ICC_RISD_Pixel9_OnOff 0 "Pixel On" 1 "Pixel Off" ;
VAL_ 1364 ICC_RISD_Pixel8_OnOff 0 "Pixel On" 1 "Pixel Off" ;
VAL_ 1364 ICC_RISD_Pixel7_OnOff 0 "Pixel On" 1 "Pixel Off" ;
VAL_ 1364 ICC_RISD_Pixel6_OnOff 0 "Pixel On" 1 "Pixel Off" ;
VAL_ 1364 ICC_RISD_Pixel5_OnOff 0 "Pixel On" 1 "Pixel Off" ;
VAL_ 1364 ICC_RISD_Pixel4_OnOff 0 "Pixel On" 1 "Pixel Off" ;
VAL_ 1364 ICC_RISD_Pixel3_OnOff 0 "Pixel On" 1 "Pixel Off" ;
VAL_ 1364 ICC_RISD_Pixel2_OnOff 0 "Pixel On" 1 "Pixel Off" ;
VAL_ 1364 ICC_RISD_Pixel1_OnOff 0 "Pixel On" 1 "Pixel Off" ;
VAL_ 1364 ICC_RISD_RollingCounter 0 "Counter 0" 1 "Counter 1" 2 "Counter 2" ;
VAL_ 1364 ICC_RISD_FrameCounter 0 "FrameCounter 0" 1 "FrameCounter 1" 2 "FrameCounter 2" 3 "FrameCounter 3" ;
VAL_ 1345 DVR_1_DVRFailReasons 0 "NoFailure" 1 "DVR360StorageFailure" 2 "DVRFCMStorageFailure" 3 "DVRAllFailure" 4 "Reserved" 5 "Reserved" 6 "Reserved" 7 "Reserved" ;
VAL_ 1345 DVR_1_RecordSts 0 "Initinal" 1 "Recording" 2 "RecordStop" 3 "Reserved" ;
VAL_ 1121 STAT_AMPNaviVolume 0 "Not Active" 1 "0" 2 "1" 3 "2" 4 "3" 5 "4" 6 "5" 7 "6" 8 "7" 9 "8" 10 "9" 11 "10" 12 "Reserved" 13 "Reserved" 14 "Reserved" 15 "Reserved" ;
VAL_ 1121 STAT_AMPVRVolume 0 "Not Active" 1 "0" 2 "1" 3 "2" 4 "3" 5 "4" 6 "5" 7 "6" 8 "7" 9 "8" 10 "9" 11 "10" 12 "Reserved" 13 "Reserved" 14 "Reserved" 15 "Reserved" ;
VAL_ 1121 STAT_AMPKeyTone 0 "Not Active" 1 "ON" 2 "OFF" 3 "reserved" ;
VAL_ 1121 STAT_AMPMediaVolume 0 "Not Active" 1 "0" 2 "1" 3 "2" 4 "3" 5 "4" 6 "5" 7 "6" 8 "7" 9 "8" 10 "9" 11 "10" 12 "11" 13 "12" 14 "13" 15 "14" 16 "15" 17 "16" 18 "17" 19 "18" 20 "19" 21 "20" 22 "21" 23 "22" 24 "23" 25 "24" 26 "25" 27 "26" 28 "27" 29 "28" 30 "29" 31 "30" 32 "31" 33 "Reserved" 34 "Reserved" 35 "Reserved" 36 "Reserved" 37 "Reserved" 38 "Reserved" 39 "Reserved" 40 "Reserved" 41 "Reserved" 42 "Reserved" 43 "Reserved" 44 "Reserved" 45 "Reserved" 46 "Reserved" 47 "Reserved" 48 "Reserved" 49 "Reserved" 50 "Reserved" 51 "Reserved" 52 "Reserved" 53 "Reserved" 54 "Reserved" 55 "Reserved" 56 "Reserved" 57 "Reserved" 58 "Reserved" 59 "Reserved" 60 "Reserved" 61 "Reserved" 62 "Reserved" 63 "Reserved" ;
VAL_ 1121 STAT_AMPPhoneVolume 0 "Not Active" 1 "0" 2 "1" 3 "2" 4 "3" 5 "4" 6 "5" 7 "6" 8 "7" 9 "8" 10 "9" 11 "10" 12 "11" 13 "12" 14 "13" 15 "14" 16 "15" 17 "16" 18 "17" 19 "18" 20 "19" 21 "20" 22 "21" 23 "22" 24 "23" 25 "24" 26 "25" 27 "Reserved" 28 "Reserved" 29 "Reserved" 30 "Reserved" 31 "Reserved" ;
VAL_ 1121 STAT_AMPSoundFocus 0 "Not Active" 1 "Customized" 2 "All" 3 "Driver" 4 "Sleep" 5 "VIP" 6 "Dolby7.1.4" 7 "Reserved" ;
VAL_ 1121 STAT_AMPSoundEffect 0 "Not Active" 1 "Customer-defined mode" 2 "Standard mode" 3 "Popular mode" 4 "Jazz mode" 5 "Classic mode" 6 "Rock mode" 7 "Vocal mode" 8 "Reserved" 9 "Reserved" 10 "Reserved" 11 "Reserved" 12 "Reserved" 13 "Reserved" 14 "Reserved" 15 "Reserved" ;
VAL_ 1121 STAT_AMPSoundEffectBass 0 "Not Active" 1 "-7" 2 "-6" 3 "-5" 4 "-4" 5 "-3" 6 "-2" 7 "-1" 8 "0" 9 "1" 10 "2" 11 "3" 12 "4" 13 "5" 14 "6" 15 "7" ;
VAL_ 1121 STAT_AMPSoundEffectMidrange 0 "Not Active" 1 "-7" 2 "-6" 3 "-5" 4 "-4" 5 "-3" 6 "-2" 7 "-1" 8 "0" 9 "1" 10 "2" 11 "3" 12 "4" 13 "5" 14 "6" 15 "7" ;
VAL_ 1121 STAT_AMPSoundEffectTreble 0 "Not Active" 1 "-7" 2 "-6" 3 "-5" 4 "-4" 5 "-3" 6 "-2" 7 "-1" 8 "0" 9 "1" 10 "2" 11 "3" 12 "4" 13 "5" 14 "6" 15 "7" ;
VAL_ 1121 STAT_AMPSoundFieldBalance 0 "Not Active" 1 "-7" 2 "-6" 3 "-5" 4 "-4" 5 "-3" 6 "-2" 7 "-1" 8 "0" 9 "1" 10 "2" 11 "3" 12 "4" 13 "5" 14 "6" 15 "7" ;
VAL_ 1121 STAT_AMPSoundFieldFader 0 "Not Active" 1 "-7" 2 "-6" 3 "-5" 4 "-4" 5 "-3" 6 "-2" 7 "-1" 8 "0" 9 "1" 10 "2" 11 "3" 12 "4" 13 "5" 14 "6" 15 "7" ;
VAL_ 1121 STAT_REQ_AMPA2BMediaSound 0 "Not Active" 1 "Media" 2 "Background" 3 "OFF" ;
VAL_ 1121 STAT_REQ_AMPA2BNaviSound 0 "Not Active" 1 "ON" 2 "OFF" 3 "Reserved" ;
VAL_ 1121 STAT_REQ_AMPA2BVRSound 0 "Not Active" 1 "VR" 2 "Siri" 3 "OFF" ;
VAL_ 1121 STAT_REQ_AMPA2BTTSSound 0 "Not Active" 1 "ON" 2 "OFF" 3 "Reserved" ;
VAL_ 1121 STAT_REQ_AMPA2BPhoneSound 0 "Not Active" 1 "BT Phone Sound ON" 2 "Tbox Sound ON" 3 "OFF" ;
VAL_ 1121 STAT_REQ_AMPAlarm 0 "Not Active" 1 "Other CHIME" 2 "PDC_FL only" 3 "PDC_FR only" 4 "PDC_RL only" 5 "PDC_RR only" 6 "PDC_FL+FR" 7 "PDC_FL+RL" 8 "PDC_FL+RR" 9 "PDC_FR+RL" 10 "PDC_FR+RR" 11 "PDC_RL+RR" 12 "PDC_FL+FR+RL" 13 "PDC_FL+FR+RR" 14 "PDC_FL+RL+RR" 15 "PDC_FR+RL+RR" 16 "PDC_all" 17 "BSD_L only" 18 "BSD_R only" 19 "BSD_L+R" 20 "CHIME OFF" 21 "Reserved" 22 "Reserved" 23 "Reserved" 24 "Reserved" 25 "Reserved" 26 "Reserved" 27 "Reserved" 28 "Reserved" 29 "Reserved" 30 "Reserved" 31 "Reserved" 32 "Reserved" 33 "Reserved" 34 "Reserved" 35 "Reserved" 36 "Reserved" 37 "Reserved" 38 "Reserved" 39 "Reserved" 40 "Reserved" 41 "Reserved" 42 "Reserved" 43 "Reserved" 44 "Reserved" 45 "Reserved" 46 "Reserved" 47 "Reserved" 48 "Reserved" 49 "Reserved" 50 "Reserved" 51 "Reserved" 52 "Reserved" 53 "Reserved" 54 "Reserved" 55 "Reserved" 56 "Reserved" 57 "Reserved" 58 "Reserved" 59 "Reserved" 60 "Reserved" 61 "Reserved" 62 "Reserved" 63 "Reserved" ;
VAL_ 1140 STAT_AMPMediaDuck 0 "Not Active" 1 "ON" 2 "OFF" 3 "Reserved" ;
VAL_ 1140 STAT_AMPSpeedVolume 0 "Not Active" 1 "OFF" 2 "Low" 3 "Middle" 4 "High" 5 "Reserved" 6 "Reserved" 7 "Reserved" ;
VAL_ 1140 STAT_AMPMute 0 "Not Active" 1 "ON" 2 "OFF" 3 "Reserved" ;
VAL_ 1140 STAT_AMPRestoreDefaults 0 "Not Active" 1 "ON" 2 "OFF" 3 "Reserved" ;
VAL_ 1140 STAT_AMPAlarmVolume 0 "Not Active" 1 "1" 2 "2" 3 "3" 4 "4" 5 "5" 6 "6" 7 "7" 8 "8" 9 "9" 10 "10" 11 "Reserved" 12 "Reserved" 13 "Reserved" 14 "Reserved" 15 "Reserved" ;
VAL_ 1140 STAT_Headrest_Mode 0 "Not Active" 1 "Share Mode" 2 "Enjoy Driving Mode" 3 "Enjoy Private Mode" ;
VAL_ 1140 STAT_AMPSoundEffectMegaBass 0 "Not Active" 1 "-7" 2 "-6" 3 "-5" 4 "-4" 5 "-3" 6 "-2" 7 "-1" 8 "0" 9 "1" 10 "2" 11 "3" 12 "4" 13 "5" 14 "6" 15 "7" ;
VAL_ 1140 STAT_AMPSoundEffectMidBass 0 "Not Active" 1 "-7" 2 "-6" 3 "-5" 4 "-4" 5 "-3" 6 "-2" 7 "-1" 8 "0" 9 "1" 10 "2" 11 "3" 12 "4" 13 "5" 14 "6" 15 "7" ;
VAL_ 1140 STAT_AMPSoundEffectMidTreble 0 "Not Active" 1 "-7" 2 "-6" 3 "-5" 4 "-4" 5 "-3" 6 "-2" 7 "-1" 8 "0" 9 "1" 10 "2" 11 "3" 12 "4" 13 "5" 14 "6" 15 "7" ;
VAL_ 1140 STAT_VirtualSbwfrOnOff 0 "Not Active" 1 "VocalConcert" 2 "ConcertHall" 3 "OFF" ;
VAL_ 1140 STAT_SurndFnOnOff 0 "Not Active" 1 "ON" 2 "OFF" 3 "Reserved" ;
VAL_ 1140 STAT_AMPBackgroundVolume 0 "Not Active" 1 "0" 2 "1" 3 "2" 4 "3" 5 "4" 6 "5" 7 "6" 8 "7" 9 "8" 10 "9" 11 "10" 12 "11" 13 "12" 14 "13" 15 "14" 16 "15" 17 "16" 18 "17" 19 "18" 20 "19" 21 "20" 22 "21" 23 "22" 24 "23" 25 "24" 26 "25" 27 "26" 28 "27" 29 "28" 30 "29" 31 "30" 32 "31" 33 "Reserved" 34 "Reserved" 35 "Reserved" 36 "Reserved" 37 "Reserved" 38 "Reserved" 39 "Reserved" 40 "Reserved" 41 "Reserved" 42 "Reserved" 43 "Reserved" 44 "Reserved" 45 "Reserved" 46 "Reserved" 47 "Reserved" 48 "Reserved" 49 "Reserved" 50 "Reserved" 51 "Reserved" 52 "Reserved" 53 "Reserved" 54 "Reserved" 55 "Reserved" 56 "Reserved" 57 "Reserved" 58 "Reserved" 59 "Reserved" 60 "Reserved" 61 "Reserved" 62 "Reserved" 63 "Reserved" ;
VAL_ 1140 STAT_AMPSoundBypass 0 "Not Active" 1 "ON" 2 "OFF" 3 "Reserved" ;
VAL_ 1140 STAT_AMPPwrRdySts 0 "Not Active" 1 "Not Ready" 2 "Ready" 3 "Reserved" ;
VAL_ 1206 EAMP_AMPKTVvoiceVolumeFed 0 "Not Active" 1 "0" 2 "1" 3 "2" 4 "3" 5 "4" 6 "5" 7 "6" 8 "7" 9 "8" 10 "9" 11 "10" 12 "11" 13 "12" 14 "13" 15 "14" 16 "15" 17 "16" 18 "17" 19 "18" 20 "19" 21 "20" 22 "21" 23 "22" 24 "23" 25 "24" 26 "25" 27 "26" 28 "27" 29 "28" 30 "29" 31 "30" 32 "31" 33 "Reserved" 34 "Reserved" 35 "Reserved" 36 "Reserved" 37 "Reserved" 38 "Reserved" 39 "Reserved" 40 "Reserved" 41 "Reserved" 42 "Reserved" 43 "Reserved" 44 "Reserved" 45 "Reserved" 46 "Reserved" 47 "Reserved" 48 "Reserved" 49 "Reserved" 50 "Reserved" 51 "Reserved" 52 "Reserved" 53 "Reserved" 54 "Reserved" 55 "Reserved" 56 "Reserved" 57 "Reserved" 58 "Reserved" 59 "Reserved" 60 "Reserved" 61 "Reserved" 62 "Reserved" 63 "Reserved" ;
VAL_ 1206 EAMP_AMPENCVolumeFed 0 "Not Active" 1 "0" 2 "1" 3 "2" 4 "3" 5 "4" 6 "5" 7 "6" 8 "7" 9 "8" 10 "9" 11 "10" 12 "11" 13 "12" 14 "13" 15 "14" 16 "15" 17 "16" 18 "17" 19 "18" 20 "19" 21 "20" 22 "21" 23 "22" 24 "23" 25 "24" 26 "25" 27 "26" 28 "27" 29 "28" 30 "29" 31 "30" 32 "31" 33 "Reserved" 34 "Reserved" 35 "Reserved" 36 "Reserved" 37 "Reserved" 38 "Reserved" 39 "Reserved" 40 "Reserved" 41 "Reserved" 42 "Reserved" 43 "Reserved" 44 "Reserved" 45 "Reserved" 46 "Reserved" 47 "Reserved" 48 "Reserved" 49 "Reserved" 50 "Reserved" 51 "Reserved" 52 "Reserved" 53 "Reserved" 54 "Reserved" 55 "Reserved" 56 "Reserved" 57 "Reserved" 58 "Reserved" 59 "Reserved" 60 "Reserved" 61 "Reserved" 62 "Reserved" 63 "Reserved" ;
VAL_ 1206 EAMP_AMPA2BKTVvoiceSoundFed 0 "Not Active" 1 "IESS OFF and KTV OFF（默认值)" 2 "IESS OFF and KTV ON" 3 "IESS ON and KTV OFF" 4 "IESS ON and KTV ON" 5 "Reserved" 6 "Reserved" 7 "Reserved" ;
VAL_ 1206 STAT_AMPSoundFocus_2 0 "Not Active" 1 "Customized" 2 "All" 3 "Driver" 4 "Sleep" 5 "VIP" 6 "FrontRow" 7 "BackRow" 8 "Reserved" 9 "Reserved" 10 "Reserved" 11 "Reserved" 12 "Reserved" 13 "Reserved" 14 "Reserved" 15 "Reserved" ;
VAL_ 1206 EAMP_AMPA2BENCSoundFed 0 "Not Active" 1 "ON" 2 "OFF" 3 "Reserved" ;
VAL_ 1206 EAMP_AMPA2BChimeSoundFed 0 "Not Active" 1 "ON" 2 "OFF" 3 "Reserved" ;
VAL_ 1206 STAT_AMPLoudness 0 "Not Active" 1 "ON" 2 "OFF" 3 "Reserved" ;
VAL_ 1206 STAT_AMPKeyVolume 0 "Not Active" 1 "0" 2 "1" 3 "2" 4 "3" 5 "4" 6 "5" 7 "6" 8 "7" 9 "8" 10 "9" 11 "10" 12 "11" 13 "12" 14 "13" 15 "14" 16 "15" 17 "16" 18 "17" 19 "18" 20 "19" 21 "20" 22 "21" 23 "22" 24 "23" 25 "24" 26 "25" 27 "26" 28 "27" 29 "28" 30 "29" 31 "30" 32 "31" 33 "Reserved" 34 "Reserved" 35 "Reserved" 36 "Reserved" 37 "Reserved" 38 "Reserved" 39 "Reserved" 40 "Reserved" 41 "Reserved" 42 "Reserved" 43 "Reserved" 44 "Reserved" 45 "Reserved" 46 "Reserved" 47 "Reserved" 48 "Reserved" 49 "Reserved" 50 "Reserved" 51 "Reserved" 52 "Reserved" 53 "Reserved" 54 "Reserved" 55 "Reserved" 56 "Reserved" 57 "Reserved" 58 "Reserved" 59 "Reserved" 60 "Reserved" 61 "Reserved" 62 "Reserved" 63 "Reserved" ;
VAL_ 1206 STAT_AMPExSoundmode 0 "Not Active" 1 "Soundmode1" 2 "Soundmode2" 3 "Soundmode3" 4 "OFF" 5 "Reserved" 6 "Reserved" 7 "Reserved" ;
VAL_ 1206 STAT_AMPA2BENCSound 0 "Not Active" 1 "FL+FR+RL+SWF" 2 "FL+FR+SWF+RR" 3 "FL+FR+RL+RR" 4 "OFF" 5 "reserved" 6 "reserved" 7 "reserved" ;
VAL_ 1078 PLG_LatchSts 0 "Open" 1 "Secondary" 2 "Latched" 3 "Initializing" ;
VAL_ 1252 TotalOdometer_km_OBD 16777215 "Invalid" ;
VAL_ 1252 DisplayVehicleSpeed 8191 "Invalid" ;
VAL_ 1252 ICC_BackLightLevel 0 "Level 1" 1 "Level 2" 2 "Level 3" 3 "Level 4" 4 "Level 5" 5 "Level 6" 6 "Level 7" 7 "Level 8" 8 "Level 9" 9 "Level 10" 10 "Reserved" 11 "Reserved" 12 "Reserved" 13 "Reserved" 14 "Reserved" 15 "Reserved" ;
VAL_ 1252 TotalOdometer_km_OBDValidData 0 "Valid" 1 "Not valid" ;
VAL_ 1252 ICC_TotalodometerbackupEnable 0 "Not Active" 1 "Disable" 2 "Enable" 3 "Reserved" ;
VAL_ 1322 STAT_AMPAlarm 0 "Not Active" 1 "Other CHIME" 2 "PDC_FL only" 3 "PDC_FR only" 4 "PDC_RL only" 5 "PDC_RR only" 6 "PDC_FL+FR" 7 "PDC_FL+RL" 8 "PDC_FL+RR" 9 "PDC_FR+RL" 10 "PDC_FR+RR" 11 "PDC_RL+RR" 12 "PDC_FL+FR+RL" 13 "PDC_FL+FR+RR" 14 "PDC_FL+RL+RR" 15 "PDC_FR+RL+RR" 16 "PDC_all" 17 "BSD_L only" 18 "BSD_R only" 19 "BSD_L+R" 20 "CHIME OFF" 21 "Reserved" 22 "Reserved" 23 "Reserved" 24 "Reserved" 25 "Reserved" 26 "Reserved" 27 "Reserved" 28 "Reserved" 29 "Reserved" 30 "Reserved" 31 "Reserved" 32 "Reserved" 33 "Reserved" 34 "Reserved" 35 "Reserved" 36 "Reserved" 37 "Reserved" 38 "Reserved" 39 "Reserved" 40 "Reserved" 41 "Reserved" 42 "Reserved" 43 "Reserved" 44 "Reserved" 45 "Reserved" 46 "Reserved" 47 "Reserved" 48 "Reserved" 49 "Reserved" 50 "Reserved" 51 "Reserved" 52 "Reserved" 53 "Reserved" 54 "Reserved" 55 "Reserved" 56 "Reserved" 57 "Reserved" 58 "Reserved" 59 "Reserved" 60 "Reserved" 61 "Reserved" 62 "Reserved" 63 "Reserved" ;
VAL_ 1176 ICC_ASUAssistPassSet 0 "Not Active" 1 "ON" 2 "OFF" 3 "Not Used" ;
VAL_ 1176 IHU_AutHldSet 0 "Not Active" 1 "On" 2 "Off" 3 "Not Used" ;
VAL_ 1176 ICC_AutoEasyEntrySet 0 "Not Active" 1 "ON" 2 "OFF" 3 "Not Used" ;
VAL_ 1176 ICC_ManualEasyOutSw 0 "Not Active" 1 "ON" 2 "OFF" 3 "Not Used" ;
VAL_ 1176 ICC_ASCMaintainModeReq 0 "Not Active" 1 "ON" 2 "OFF" 3 "Not Used" ;
VAL_ 1176 ICC_PABSetCmd 0 "Not Active" 1 "PAB OFF Cmd" 2 "PAB ON Cmd" 3 "Not Used" ;
VAL_ 1176 ICC_EPBSetCmd 0 "Not Active" 1 "Release" 2 "Apply" 3 "Reserved" ;
VAL_ 1176 ICC_ASUMemoryPosition 0 "Not Active" 1 "ON" 2 "OFF" 3 "Not Used" ;
VAL_ 1176 ICC_ASUEasyLoadingSet 0 "Not Active" 1 "ON" 2 "OFF" 3 "Not Used" ;
VAL_ 1176 Set_CSTFunctionSts 0 "Not active" 1 "CST ON" 2 "CST OFF" 3 "Reserved" ;
VAL_ 1176 ICC_ASURearaxlewithTaildoor 0 "Not Active" 1 "ON" 2 "OFF" 3 "Not Used" ;
VAL_ 1176 CST_SensitivityReq 0 "Not active" 1 "lowSensitivity" 2 "MiddleSensitivity" 3 "highSensitivity" ;
VAL_ 1176 TIHU_SetHDCOnOff 0 "Not Active" 1 "ON" 2 "OFF" 3 "Not Used" ;
VAL_ 1176 Set_ESPFunctionSts 0 "Not active" 1 "ON" 2 "OFF" 3 "Not Used" ;
VAL_ 1176 ICC_ASUPreviewCont 0 "Not Active" 1 "ON" 2 "OFF" 3 "Not Used" ;
VAL_ 1176 ICC_ASUHighwayModAdjust 0 "Not Active" 1 "ON" 2 "OFF" 3 "Not Used" ;
VAL_ 1176 ICC_ASUMapAdjust 0 "Not Active" 1 "ON" 2 "OFF" 3 "Not Used" ;
VAL_ 1239 ICC_DisChg 0 "Not Active" 1 "OFF" 2 "V2L ON" 3 "V2V ON" ;
VAL_ 1239 ICC_StpDisChgReq 0 "inactive" 1 "active" ;
VAL_ 1239 ICC_RegenLevel 0 "Not Active" 1 "off" 2 "low" 3 "high" ;
VAL_ 1239 ICC_ELockReq 0 "NoUnlockReq" 1 "UnlockReq" ;
VAL_ 1239 ICC_DisChgPercent 0 "Not Active" ;
VAL_ 1239 ICC_ChgSocSet 0 "Not Active" 254 "Abnormal" 255 "Invalid" ;
VAL_ 1239 ICC_CampMode 0 "Not Active" 1 "OFF" 2 "ON" 3 "Not Used" ;
VAL_ 1239 ICC_SftWarning 0 "Not Active" 1 "OFF" 2 "ON" 3 "Not Used" ;
VAL_ 1239 ICC_TowingMode 0 "Not Active" 1 "OFF" 2 "ON" 3 "Not Used" ;
VAL_ 1239 ICC_StopMode 0 "Not Active" 1 "Creep" 2 "Stop" 3 "Not Used" ;
VAL_ 1239 ICC_EPedalMode 0 "Not Active" 1 "ON" 2 "OFF" 3 "Not Used" ;
VAL_ 1246 ICC_WindowKeySts 0 "Not Active" 1 "On" 2 "Off" 3 "Not Used" ;
VAL_ 1246 ICC_FaceKeySts 0 "Not Active" 1 "On" 2 "Off" 3 "Not Used" ;
VAL_ 1246 ICC_FootKeySts 0 "Not Active" 1 "On" 2 "Off" 3 "Not Used" ;
VAL_ 1246 BltCallSts 0 "Not Active" 1 "On" 2 "Off" 3 "Not Used" ;
VAL_ 1246 ICC_DockWinspSts 0 "Not Active" 1 "On" 2 "Off" 3 "Not Used" ;
VAL_ 1246 ICC_DockTSts 0 "Not Active" 1 "On" 2 "Off" 3 "Not Used" ;
VAL_ 1246 ICC_ACFastCool 0 "Not Active" 1 "On" 2 "Off" 3 "Not Used" ;
VAL_ 1246 ICC_ACFastHeat 0 "Not Active" 1 "On" 2 "Off" 3 "Not Used" ;
VAL_ 1246 ICC_SetCLMOn 0 "Not Active" 1 "On" 2 "Off" 3 "Not Used" ;
VAL_ 1246 ICC_SetAutoKeySts 0 "Not Active" 1 "On" 2 "Off" 3 "Not Used" ;
VAL_ 1246 ICC_SetFrontDeforestSts 0 "Not Active" 1 "On" 2 "Off" 3 "Not used" ;
VAL_ 1246 ICC_SetCirculationModeKeySts 0 "Not Active" 1 "Recirculation mode" 2 "Air circulation mode" 3 "Two-Layer Flow Mode" ;
VAL_ 1246 ICC_ZoneSelectionKeySts 0 "Not Active" 1 "Single zone mode" 2 "Dual zone mode" 3 "Not Used" ;
VAL_ 1246 ICC_ResetFilter 0 "Not Active" 1 "On" 2 "Off" 3 "Not Used" ;
VAL_ 1246 ICC_AUTODefrostOnKeySts 0 "Not Active" 1 "On" 2 "Off" 3 "Not Used" ;
VAL_ 1246 ICC_AutoAirClean 0 "Not active" 1 "On" 2 "Off" 3 "Not Used" ;
VAL_ 1246 ICC_KeepWarm 0 "Not active" 1 "Open AC" 2 "Open NotAC" 3 "Closed" ;
VAL_ 1246 ICC_BlowSpeedLevelKeySts 0 "Not active" 1 "Level  1" 2 "Level  2" 3 "Level  3" 4 "Level  4" 5 "Level  5" 6 "Level  6" 7 "Level  7" 8 "Level  8" 9 "Level  9" 10 "Level 10" 11 "Reserved" 12 "Level__0" 13 "Reserved" 14 "Reserved" 15 "Reserved" ;
VAL_ 1246 ICC_SetACRequestKeySts 0 "Not Active" 1 "ON" 2 "OFF" 3 "Not used" 4 "Not used" ;
VAL_ 1246 ICC_DSwingSet 0 "Not_active" 1 "AllZone Swing" 2 "Single Swing" 3 "Mirro Swing" 4 "Free Swing" ;
VAL_ 1246 ICC_PSwingSet 0 "Not_active" 1 "AllZone Swing" 2 "Single Swing" 3 "Mirro Swing" 4 "Free Swing" ;
VAL_ 1246 ICC_AUTODefLevelSet 0 "Not Active" 1 "OFF" 2 "Low" 3 "Medium" 4 "High" ;
VAL_ 1246 ICC_SetTemperature_L_C 31 "Not active" ;
VAL_ 1246 ICC_SetTemperature_R_C 31 "Not active" ;
VAL_ 1246 ICC_NetWorkTemperature 254 "invalid" ;
VAL_ 1246 ICC_NetWorkHumidity 254 "invalid" ;
VAL_ 1246 ICC_DLOnOff 0 "Not Active" 1 "On" 2 "Off" 3 "Not Used" ;
VAL_ 1246 ICC_DROnOff 0 "Not Active" 1 "On" 2 "Off" 3 "Not Used" ;
VAL_ 1246 ICC_PLOnOff 0 "Not Active" 1 "On" 2 "Off" 3 "Not Used" ;
VAL_ 1246 ICC_PROnOff 0 "Not Active" 1 "On" 2 "Off" 3 "Not Used" ;
VAL_ 1246 ICC_DCOnOff 0 "Not Active" 1 "On" 2 "Off" 3 "Not Used" ;
VAL_ 1246 ICC_LoveRemind 0 "Not Active" 1 "On" 2 "Off" 3 "Not Used" ;
VAL_ 1246 ICC_InteCleanCar 0 "Not Active" 1 "On" 2 "Off" 3 "Not Used" ;
VAL_ 1246 ICC_KeepWarmMemory 0 "Not Active" 1 "Memory On" 2 "Memory Off" 3 "Not Used" ;
VAL_ 1250 ICC_AutoLightSW 0 "Not active" 1 "Active" ;
VAL_ 1250 ICC_CleanMode 0 "NotActive" 1 "OFF" 2 "ON" 3 "Reserved" ;
VAL_ 1250 ICC_1_OTASts 0 "Normal Status" 1 "OTA Status" 2 "Reserved" 3 "Reserved" ;
VAL_ 1250 ICC_1_OTAHV_Req 0 "Not active" 1 "HVON" 2 "HVOFF" 3 "Reserved" ;
VAL_ 1250 ICC_1_OTAPwrMngt 0 "No Request" 1 "Power Off" 2 "Power On" 3 "Continuous ON" 4 "Reserved" 5 "Reserved" 6 "Reserved" 7 "Reserved" ;
VAL_ 1250 ICC_DriveModeSwitch 0 "NotActive" 1 "ECO" 2 "NORMAL" 3 "SPORT" 4 "RainSNOW" 5 "MUD(Res)" 6 "Offroad" 7 "Individual" ;
VAL_ 1250 ICC_PropulsionMode 0 "Not Active" 1 "Comfortable" 2 "Normal" 3 "Sport" 4 "Snow" 5 "Off Road" ;
VAL_ 1250 ICC_SteeringMode 0 "Not Active" 1 "Normal" 2 "Sport" 3 "Light" ;
VAL_ 1250 ICC_SuspensionHeight 0 "Not Active" 1 "Very Low" 2 "Low" 3 "Normal" 4 "High" 5 "Very High" ;
VAL_ 1250 ICC_SuspensionDamping 0 "Not Active" 1 "Soft" 2 "Middle" 3 "Hard" ;
VAL_ 1250 ICC_AirconditionMode 0 "Not Active" 1 "ECO" 2 "Comfortable" 3 "Strong" ;
VAL_ 1250 ICC_BrakePedalFeelMode 0 "Not Active" 1 "Comfortable" 2 "Sport" 3 "Offroad" ;
VAL_ 1250 ICC_SentinelHV_Req 0 "Not active" 1 "HVON" 2 "HVOFF" 3 "Reserved" ;
VAL_ 1250 ICC_PetModeHV_Req 0 "Not Active" 1 "HVON" 2 "HVOFF" 3 "Reserved" ;
VAL_ 1250 ICC_SelfClearing 0 "Not active" 1 "Enable" ;
SIG_GROUP_ 1364 New_Signal_Group_554 1 : ICC_RISD_FrameCounter ICC_RISD_RollingCounter ICC_RISD_Pixel1_OnOff ICC_RISD_Pixel2_OnOff ICC_RISD_Pixel3_OnOff ICC_RISD_Pixel4_OnOff ICC_RISD_Pixel5_OnOff ICC_RISD_Pixel6_OnOff ICC_RISD_Pixel7_OnOff ICC_RISD_Pixel8_OnOff ICC_RISD_Pixel9_OnOff ICC_RISD_Pixel10_OnOff ICC_RISD_Pixel11_OnOff ICC_RISD_Pixel12_OnOff ICC_RISD_Pixel13_OnOff ICC_RISD_Pixel14_OnOff ICC_RISD_Pixel15_OnOff ICC_RISD_Pixel16_OnOff ICC_RISD_Pixel17_OnOff ICC_RISD_Pixel18_OnOff ICC_RISD_Pixel19_OnOff ICC_RISD_Pixel20_OnOff ICC_RISD_Pixel21_OnOff ICC_RISD_Pixel22_OnOff ICC_RISD_Pixel23_OnOff ICC_RISD_Pixel24_OnOff ICC_RISD_Pixel25_OnOff ICC_RISD_Pixel26_OnOff ICC_RISD_Pixel27_OnOff ICC_RISD_Pixel28_OnOff ICC_RISD_Pixel29_OnOff ICC_RISD_Pixel30_OnOff ICC_RISD_Pixel31_OnOff ICC_RISD_Pixel32_OnOff ICC_RISD_Pixel33_OnOff ICC_RISD_Pixel34_OnOff ICC_RISD_Pixel35_OnOff ICC_RISD_Pixel36_OnOff ICC_RISD_Pixel37_OnOff ICC_RISD_Pixel38_OnOff ICC_RISD_Pixel39_OnOff ICC_RISD_Pixel40_OnOff ICC_RISD_Pixel41_OnOff ICC_RISD_Pixel42_OnOff ICC_RISD_Pixel43_OnOff ICC_RISD_Pixel44_OnOff ICC_RISD_Pixel45_OnOff ICC_RISD_Pixel46_OnOff ICC_RISD_Pixel47_OnOff ICC_RISD_Pixel48_OnOff ICC_RISD_Pixel49_OnOff ICC_RISD_Pixel50_OnOff ICC_RISD_Pixel51_OnOff ICC_RISD_Pixel52_OnOff ICC_RISD_Pixel53_OnOff ICC_RISD_Pixel54_OnOff ICC_RISD_Pixel55_OnOff ICC_RISD_Pixel56_OnOff ICC_RISD_Pixel57_OnOff ICC_RISD_Pixel58_OnOff ICC_RISD_Pixel59_OnOff ICC_RISD_Pixel60_OnOff ICC_RISD_Pixel61_OnOff ICC_RISD_Pixel62_OnOff ICC_RISD_Pixel63_OnOff ICC_RISD_Pixel64_OnOff ICC_RISD_Pixel65_OnOff ICC_RISD_Pixel66_OnOff ICC_RISD_Pixel67_OnOff ICC_RISD_Pixel68_OnOff ICC_RISD_Pixel69_OnOff ICC_RISD_Pixel70_OnOff ICC_RISD_Pixel71_OnOff ICC_RISD_Pixel72_OnOff ICC_RISD_Pixel73_OnOff ICC_RISD_Pixel74_OnOff ICC_RISD_Pixel75_OnOff ICC_RISD_Pixel76_OnOff ICC_RISD_Pixel77_OnOff ICC_RISD_Pixel78_OnOff ICC_RISD_Pixel79_OnOff ICC_RISD_Pixel80_OnOff ICC_RISD_Pixel81_OnOff ICC_RISD_Pixel82_OnOff ICC_RISD_Pixel83_OnOff ICC_RISD_Pixel84_OnOff ICC_RISD_Pixel85_OnOff ICC_RISD_Pixel86_OnOff ICC_RISD_Pixel87_OnOff ICC_RISD_Pixel88_OnOff ICC_RISD_Pixel89_OnOff ICC_RISD_Pixel90_OnOff ICC_RISD_Pixel91_OnOff ICC_RISD_Pixel92_OnOff ICC_RISD_Pixel93_OnOff ICC_RISD_Pixel94_OnOff ICC_RISD_Pixel95_OnOff ICC_RISD_Pixel96_OnOff ICC_RISD_Pixel97_OnOff ICC_RISD_Pixel98_OnOff ICC_RISD_Pixel99_OnOff ICC_RISD_Pixel100_OnOff ICC_RISD_Pixel101_OnOff ICC_RISD_Pixel102_OnOff ICC_RISD_Pixel103_OnOff ICC_RISD_Pixel104_OnOff ICC_RISD_Pixel105_OnOff ICC_RISD_Pixel106_OnOff ICC_RISD_Pixel107_OnOff ICC_RISD_Pixel108_OnOff ICC_RISD_Pixel109_OnOff ICC_RISD_Pixel110_OnOff ICC_RISD_Pixel111_OnOff ICC_RISD_Pixel112_OnOff ICC_RISD_Pixel113_OnOff ICC_RISD_Pixel114_OnOff ICC_RISD_Pixel115_OnOff ICC_RISD_Pixel116_OnOff ICC_RISD_Pixel117_OnOff ICC_RISD_Pixel118_OnOff ICC_RISD_Pixel119_OnOff ICC_RISD_Pixel120_OnOff ICC_RISD_Pixel121_OnOff ICC_RISD_Pixel122_OnOff ICC_RISD_Pixel123_OnOff ICC_RISD_Pixel124_OnOff ICC_RISD_Pixel125_OnOff ICC_RISD_Pixel126_OnOff ICC_RISD_Pixel127_OnOff ICC_RISD_Pixel128_OnOff ICC_RISD_Pixel129_OnOff ICC_RISD_Pixel130_OnOff ICC_RISD_Pixel131_OnOff ICC_RISD_Pixel132_OnOff ICC_RISD_Pixel133_OnOff ICC_RISD_Pixel134_OnOff ICC_RISD_Pixel135_OnOff ICC_RISD_Pixel136_OnOff ICC_RISD_Pixel137_OnOff ICC_RISD_Pixel138_OnOff ICC_RISD_Pixel139_OnOff ICC_RISD_Pixel140_OnOff ICC_RISD_Pixel141_OnOff ICC_RISD_Pixel142_OnOff ICC_RISD_Pixel143_OnOff ICC_RISD_Pixel144_OnOff ICC_RISD_Pixel145_OnOff ICC_RISD_Pixel146_OnOff ICC_RISD_Pixel147_OnOff ICC_RISD_Pixel148_OnOff ICC_RISD_Pixel149_OnOff ICC_RISD_Pixel150_OnOff ICC_RISD_Pixel151_OnOff ICC_RISD_Pixel152_OnOff ICC_RISD_Pixel153_OnOff ICC_RISD_Pixel154_OnOff ICC_RISD_Pixel155_OnOff ICC_RISD_Pixel156_OnOff ICC_RISD_Pixel157_OnOff ICC_RISD_Pixel158_OnOff ICC_RISD_Pixel159_OnOff ICC_RISD_Pixel160_OnOff ICC_RISD_Pixel161_OnOff ICC_RISD_Pixel162_OnOff ICC_RISD_Pixel163_OnOff ICC_RISD_Pixel164_OnOff ICC_RISD_Pixel165_OnOff ICC_RISD_Pixel166_OnOff ICC_RISD_Pixel167_OnOff ICC_RISD_Pixel168_OnOff ICC_RISD_Pixel169_OnOff ICC_RISD_Pixel170_OnOff ICC_RISD_Pixel171_OnOff ICC_RISD_Pixel172_OnOff ICC_RISD_Pixel173_OnOff ICC_RISD_Pixel174_OnOff ICC_RISD_Pixel175_OnOff ICC_RISD_Pixel176_OnOff ICC_RISD_Pixel177_OnOff ICC_RISD_Pixel178_OnOff ICC_RISD_Pixel179_OnOff ICC_RISD_Pixel180_OnOff ICC_RISD_Pixel181_OnOff ICC_RISD_Pixel182_OnOff ICC_RISD_Pixel183_OnOff ICC_RISD_Pixel184_OnOff ICC_RISD_Pixel185_OnOff ICC_RISD_Pixel186_OnOff ICC_RISD_Pixel187_OnOff ICC_RISD_Pixel188_OnOff ICC_RISD_Pixel189_OnOff ICC_RISD_Pixel190_OnOff ICC_RISD_Pixel191_OnOff ICC_RISD_Pixel192_OnOff ICC_RISD_Pixel193_OnOff ICC_RISD_Pixel194_OnOff ICC_RISD_Pixel195_OnOff ICC_RISD_Pixel196_OnOff ICC_RISD_Pixel197_OnOff ICC_RISD_Pixel198_OnOff ICC_RISD_Pixel199_OnOff ICC_RISD_Pixel200_OnOff ICC_RISD_Pixel201_OnOff ICC_RISD_Pixel202_OnOff ICC_RISD_Pixel203_OnOff ICC_RISD_Pixel204_OnOff ICC_RISD_Pixel205_OnOff ICC_RISD_Pixel206_OnOff ICC_RISD_Pixel207_OnOff ICC_RISD_Pixel208_OnOff ICC_RISD_Pixel209_OnOff ICC_RISD_Pixel210_OnOff ICC_RISD_Pixel211_OnOff ICC_RISD_Pixel212_OnOff ICC_RISD_Pixel213_OnOff ICC_RISD_Pixel214_OnOff ICC_RISD_Pixel215_OnOff ICC_RISD_Pixel216_OnOff ICC_RISD_Pixel217_OnOff ICC_RISD_Pixel218_OnOff ICC_RISD_Pixel219_OnOff ICC_RISD_Pixel220_OnOff ICC_RISD_Pixel221_OnOff ICC_RISD_Pixel222_OnOff ICC_RISD_Pixel223_OnOff ICC_RISD_Pixel224_OnOff ICC_RISD_Pixel225_OnOff ICC_RISD_Pixel226_OnOff ICC_RISD_Pixel227_OnOff ICC_RISD_Pixel228_OnOff ICC_RISD_Pixel229_OnOff ICC_RISD_Pixel230_OnOff ICC_RISD_Pixel231_OnOff ICC_RISD_Pixel232_OnOff ICC_RISD_Pixel233_OnOff ICC_RISD_Pixel234_OnOff ICC_RISD_Pixel235_OnOff ICC_RISD_Pixel236_OnOff ICC_RISD_Pixel237_OnOff ICC_RISD_Pixel238_OnOff ICC_RISD_Pixel239_OnOff ICC_RISD_Pixel240_OnOff ICC_RISD_Pixel241_OnOff ICC_RISD_Pixel242_OnOff ICC_RISD_Pixel243_OnOff ICC_RISD_Pixel244_OnOff ICC_RISD_Pixel245_OnOff ICC_RISD_Pixel246_OnOff ICC_RISD_Pixel247_OnOff ICC_RISD_Pixel248_OnOff ICC_RISD_Pixel249_OnOff ICC_RISD_Pixel250_OnOff ICC_RISD_Pixel251_OnOff ICC_RISD_Pixel252_OnOff ICC_RISD_Pixel253_OnOff ICC_RISD_Pixel254_OnOff ICC_RISD_Pixel255_OnOff ICC_RISD_Pixel256_OnOff ICC_RISD_Pixel257_OnOff ICC_RISD_Pixel258_OnOff ICC_RISD_Pixel259_OnOff ICC_RISD_Pixel260_OnOff ICC_RISD_Pixel261_OnOff ICC_RISD_Pixel262_OnOff ICC_RISD_Pixel263_OnOff ICC_RISD_Pixel264_OnOff ICC_RISD_Pixel265_OnOff ICC_RISD_Pixel266_OnOff ICC_RISD_Pixel267_OnOff ICC_RISD_Pixel268_OnOff ICC_RISD_Pixel269_OnOff ICC_RISD_Pixel270_OnOff ICC_RISD_Pixel271_OnOff ICC_RISD_Pixel272_OnOff ICC_RISD_Pixel273_OnOff ICC_RISD_Pixel274_OnOff ICC_RISD_Pixel275_OnOff ICC_RISD_Pixel276_OnOff ICC_RISD_Pixel277_OnOff ICC_RISD_Pixel278_OnOff ICC_RISD_Pixel279_OnOff ICC_RISD_Pixel280_OnOff ICC_RISD_Pixel281_OnOff ICC_RISD_Pixel282_OnOff ICC_RISD_Pixel283_OnOff ICC_RISD_Pixel284_OnOff ICC_RISD_Pixel285_OnOff ICC_RISD_Pixel286_OnOff ICC_RISD_Pixel287_OnOff ICC_RISD_Pixel288_OnOff ICC_RISD_Pixel289_OnOff ICC_RISD_Pixel290_OnOff ICC_RISD_Pixel291_OnOff ICC_RISD_Pixel292_OnOff ICC_RISD_Pixel293_OnOff ICC_RISD_Pixel294_OnOff ICC_RISD_Pixel295_OnOff ICC_RISD_Pixel296_OnOff ICC_RISD_Pixel297_OnOff ICC_RISD_Pixel298_OnOff ICC_RISD_Pixel299_OnOff ICC_RISD_Pixel300_OnOff ICC_RISD_Pixel301_OnOff ICC_RISD_Pixel302_OnOff ICC_RISD_Pixel303_OnOff ICC_RISD_Pixel304_OnOff ICC_RISD_Pixel305_OnOff ICC_RISD_Pixel306_OnOff ICC_RISD_Pixel307_OnOff ICC_RISD_Pixel308_OnOff ICC_RISD_Pixel309_OnOff ICC_RISD_Pixel310_OnOff ICC_RISD_Pixel311_OnOff ICC_RISD_Pixel312_OnOff ICC_RISD_Pixel313_OnOff ICC_RISD_Pixel314_OnOff ICC_RISD_Pixel315_OnOff ICC_RISD_Pixel316_OnOff ICC_RISD_Pixel317_OnOff ICC_RISD_Pixel318_OnOff ICC_RISD_Pixel319_OnOff ICC_RISD_Pixel320_OnOff ICC_RISD_Pixel321_OnOff ICC_RISD_Pixel322_OnOff ICC_RISD_Pixel323_OnOff ICC_RISD_Pixel324_OnOff ICC_RISD_Pixel325_OnOff ICC_RISD_Pixel326_OnOff ICC_RISD_Pixel327_OnOff ICC_RISD_Pixel328_OnOff ICC_RISD_Pixel329_OnOff ICC_RISD_Pixel330_OnOff ICC_RISD_Pixel331_OnOff ICC_RISD_Pixel332_OnOff ICC_RISD_Pixel333_OnOff ICC_RISD_Pixel334_OnOff ICC_RISD_Pixel335_OnOff ICC_RISD_Pixel336_OnOff ICC_RISD_Pixel337_OnOff ICC_RISD_Pixel338_OnOff ICC_RISD_Pixel339_OnOff ICC_RISD_Pixel340_OnOff ICC_RISD_Pixel341_OnOff ICC_RISD_Pixel342_OnOff ICC_RISD_Pixel343_OnOff ICC_RISD_Pixel344_OnOff ICC_RISD_Pixel345_OnOff ICC_RISD_Pixel346_OnOff ICC_RISD_Pixel347_OnOff ICC_RISD_Pixel348_OnOff ICC_RISD_Pixel349_OnOff ICC_RISD_Pixel350_OnOff ICC_RISD_Pixel351_OnOff ICC_RISD_Pixel352_OnOff ICC_RISD_Pixel353_OnOff ICC_RISD_Pixel354_OnOff ICC_RISD_Pixel355_OnOff ICC_RISD_Pixel356_OnOff ICC_RISD_Pixel357_OnOff ICC_RISD_Pixel358_OnOff ICC_RISD_Pixel359_OnOff ICC_RISD_Pixel360_OnOff ICC_RISD_Pixel361_OnOff ICC_RISD_Pixel362_OnOff ICC_RISD_Pixel363_OnOff ICC_RISD_Pixel364_OnOff ICC_RISD_Pixel365_OnOff ICC_RISD_Pixel366_OnOff ICC_RISD_Pixel367_OnOff ICC_RISD_Pixel368_OnOff ICC_RISD_Pixel369_OnOff ICC_RISD_Pixel370_OnOff ICC_RISD_Pixel371_OnOff ICC_RISD_Pixel372_OnOff ICC_RISD_Pixel373_OnOff ICC_RISD_Pixel374_OnOff ICC_RISD_Pixel375_OnOff ICC_RISD_Pixel376_OnOff ICC_RISD_Pixel377_OnOff ICC_RISD_Pixel378_OnOff ICC_RISD_Pixel379_OnOff ICC_RISD_Pixel380_OnOff ICC_RISD_Pixel381_OnOff ICC_RISD_Pixel382_OnOff ICC_RISD_Pixel383_OnOff ICC_RISD_Pixel384_OnOff ICC_RISD_Pixel385_OnOff ICC_RISD_Pixel386_OnOff ICC_RISD_Pixel387_OnOff ICC_RISD_Pixel388_OnOff ICC_RISD_Pixel389_OnOff ICC_RISD_Pixel390_OnOff ICC_RISD_Pixel391_OnOff ICC_RISD_Pixel392_OnOff ICC_RISD_Pixel393_OnOff ICC_RISD_Pixel394_OnOff ICC_RISD_Pixel395_OnOff ICC_RISD_Pixel396_OnOff ICC_RISD_Pixel397_OnOff ICC_RISD_Pixel398_OnOff ICC_RISD_Pixel399_OnOff ICC_RISD_Pixel400_OnOff ICC_RISD_Pixel401_OnOff ICC_RISD_Pixel402_OnOff ICC_RISD_Pixel403_OnOff ICC_RISD_Pixel404_OnOff ICC_RISD_Pixel405_OnOff ICC_RISD_Pixel406_OnOff ICC_RISD_Pixel407_OnOff ICC_RISD_Pixel408_OnOff ICC_RISD_Pixel409_OnOff ICC_RISD_Pixel410_OnOff ICC_RISD_Pixel411_OnOff ICC_RISD_Pixel412_OnOff ICC_RISD_Pixel413_OnOff ICC_RISD_Pixel414_OnOff ICC_RISD_Pixel415_OnOff ICC_RISD_Pixel416_OnOff ICC_RISD_Pixel417_OnOff ICC_RISD_Pixel418_OnOff ICC_RISD_Pixel419_OnOff ICC_RISD_Pixel420_OnOff ICC_RISD_Pixel421_OnOff ICC_RISD_Pixel422_OnOff ICC_RISD_Pixel423_OnOff ICC_RISD_Pixel424_OnOff ICC_RISD_Pixel425_OnOff ICC_RISD_Pixel426_OnOff ICC_RISD_Pixel427_OnOff ICC_RISD_Pixel428_OnOff ICC_RISD_Pixel429_OnOff ICC_RISD_Pixel430_OnOff ICC_RISD_Pixel431_OnOff ICC_RISD_Pixel432_OnOff ICC_RISD_Pixel433_OnOff ICC_RISD_Pixel434_OnOff ICC_RISD_Pixel435_OnOff ICC_RISD_Pixel436_OnOff ICC_RISD_Pixel437_OnOff ICC_RISD_Pixel438_OnOff ICC_RISD_Pixel439_OnOff ICC_RISD_Pixel440_OnOff ICC_RISD_Pixel441_OnOff ICC_RISD_Pixel442_OnOff ICC_RISD_Pixel443_OnOff ICC_RISD_Pixel444_OnOff ICC_RISD_Pixel445_OnOff ICC_RISD_Pixel446_OnOff ICC_RISD_Pixel447_OnOff ICC_RISD_Pixel448_OnOff ICC_RISD_Pixel449_OnOff ICC_RISD_Pixel450_OnOff ICC_RISD_Pixel451_OnOff ICC_RISD_Pixel452_OnOff ICC_RISD_Pixel453_OnOff ICC_RISD_Pixel454_OnOff ICC_RISD_Pixel455_OnOff ICC_RISD_Pixel456_OnOff ICC_RISD_Pixel457_OnOff ICC_RISD_Pixel458_OnOff ICC_RISD_Pixel459_OnOff ICC_RISD_Pixel460_OnOff ICC_RISD_Pixel461_OnOff ICC_RISD_Pixel462_OnOff ICC_RISD_Pixel463_OnOff ICC_RISD_Pixel464_OnOff ICC_RISD_Pixel465_OnOff ICC_RISD_Pixel466_OnOff ICC_RISD_Pixel467_OnOff ICC_RISD_Pixel468_OnOff ICC_RISD_Pixel469_OnOff ICC_RISD_Pixel470_OnOff ICC_RISD_Pixel471_OnOff ICC_RISD_Pixel472_OnOff ICC_RISD_Pixel473_OnOff ICC_RISD_Pixel474_OnOff ICC_RISD_Pixel475_OnOff ICC_RISD_Pixel476_OnOff ICC_RISD_Pixel477_OnOff ICC_RISD_Pixel478_OnOff ICC_RISD_Pixel479_OnOff ICC_RISD_Pixel480_OnOff ICC_RISD_Pixel481_OnOff ICC_RISD_Pixel482_OnOff ICC_RISD_Pixel483_OnOff ICC_RISD_Pixel484_OnOff ICC_RISD_Pixel485_OnOff ICC_RISD_Pixel486_OnOff ICC_RISD_Pixel487_OnOff ICC_RISD_Pixel488_OnOff ICC_RISD_Pixel489_OnOff ICC_RISD_Pixel490_OnOff ICC_RISD_Pixel491_OnOff ICC_RISD_Pixel492_OnOff ICC_RISD_Pixel493_OnOff ICC_RISD_Pixel494_OnOff ICC_RISD_Pixel495_OnOff ICC_RISD_Pixel496_OnOff ICC_RISD_Pixel497_OnOff ICC_RISD_Pixel498_OnOff ICC_RISD_Pixel499_OnOff ICC_RISD_Pixel500_OnOff ICC_RISD_Pixel501_OnOff ICC_RISD_Pixel502_OnOff ICC_RISD_Pixel503_OnOff ICC_RISD_Pixel504_OnOff;
SIG_GROUP_ 1176 ICC_CH_3_0x498_E2E_P01_1 1 : Fusa_498_1 Fusa_498_2 Fusa_498_3 Fusa_498_4 Fusa_498_5 Fusa_498_6 ICC_CH_3_CRC ICC_CH_3_RollgCntr ICC_ASUAssistPassSet IHU_AutHldSet ICC_AutoEasyEntrySet ICC_ManualEasyOutSw ICC_ASCMaintainModeReq ICC_PABSetCmd ICC_EPBSetCmd ICC_ASUMemoryPosition ICC_ASUEasyLoadingSet Set_CSTFunctionSts ICC_ASURearaxlewithTaildoor CST_SensitivityReq TIHU_SetHDCOnOff Set_ESPFunctionSts ICC_ASUPreviewCont ICC_ASUHighwayModAdjust ICC_ASUMapAdjust;
